VERSION "HNNBNNNYNNNNNNNNNNNNNNNNNNNNNNNNNNNNNNNNNN/4/%%%/4/'%**4NNN///"

NS_ :

BS_:

BU_: BAP_Tester BCM1 Gateway Gateway_PAG Klima_MSB Lift_VA VAS_L VAS_R

BO_ 976 TSG_FT_01: 8 Gateway
 SG_ FT_Tuer_geoeffnet : 0|1@1+ (1.0,0.0) [0.0|1] ""  BCM1,Klima_MSB,Lift_VA,VAS_L,VAS_R
 SG_ FT_verriegelt : 1|1@1+ (1.0,0.0) [0.0|1] ""  VAS_L,VAS_R
 SG_ FT_gesafet : 2|1@1+ (1.0,0.0) [0.0|1] ""  Vector__XXX
 SG_ FT_Schluesselschalter_auf : 3|1@1+ (1.0,0.0) [0.0|1] ""  Vector__XXX
 SG_ FT_Schluesselschalter_zu : 4|1@1+ (1.0,0.0) [0.0|1] ""  Vector__XXX
 SG_ FT_Unlock_Taster : 5|1@1+ (1.0,0.0) [0.0|1] ""  Vector__XXX
 SG_ FT_Lock_Taster : 6|1@1+ (1.0,0.0) [0.0|1] ""  Vector__XXX
 SG_ FT_Sperrklinke : 7|1@1+ (1.0,0.0) [0.0|1] ""  Vector__XXX
 SG_ FT_TAG_betaetigt : 8|1@1+ (1.0,0.0) [0.0|1] ""  VAS_L,VAS_R
 SG_ FT_TIG_betaetigt : 9|1@1+ (1.0,0.0) [0.0|1] ""  BCM1,VAS_L,VAS_R
 SG_ FT_IRUE_Taste : 10|1@1+ (1.0,0.0) [0.0|1] ""  Vector__XXX
 SG_ FT_HD_Taste : 11|1@1+ (1.0,0.0) [0.0|1] ""  Vector__XXX
 SG_ FT_TD_Taste_Fehler : 12|1@1+ (1.0,0.0) [0.0|1] ""  Vector__XXX
 SG_ FT_TD_Taste : 13|1@1+ (1.0,0.0) [0.0|1] ""  Vector__XXX
 SG_ SSR_Temp_Freigabe : 14|1@1+ (1.0,0.0) [0.0|1] ""  Vector__XXX
 SG_ FT_Sp_Heizung_Anf : 15|1@1+ (100,0) [0|100] "Unit_PerCent"  Vector__XXX
 SG_ FT_HD_Taste_2 : 16|1@1+ (1.0,0.0) [0.0|1] ""  Vector__XXX
 SG_ FT_TSG_hinten_verbaut : 18|1@1+ (1.0,0.0) [0.0|1] ""  Vector__XXX
 SG_ FT_Sp_Blk_def : 19|1@1+ (1.0,0.0) [0.0|1] ""  BCM1
 SG_ FT_FH_S_ManHoch : 20|1@1+ (1.0,0.0) [0.0|1] ""  Vector__XXX
 SG_ FT_FH_S_AutoHoch : 21|1@1+ (1.0,0.0) [0.0|1] ""  Vector__XXX
 SG_ FT_FH_S_ManTief : 22|1@1+ (1.0,0.0) [0.0|1] ""  Vector__XXX
 SG_ FT_FH_S_AutoTief : 23|1@1+ (1.0,0.0) [0.0|1] ""  Vector__XXX
 SG_ FT_FH_Oeffnung : 24|8@1+ (0.5,0) [0.0|100.0] "Unit_PerCent"  BCM1,Klima_MSB
 SG_ FT_FH_Bew_hoch : 32|1@1+ (1.0,0.0) [0.0|1] ""  Vector__XXX
 SG_ FT_FH_Bew_tief : 33|1@1+ (1.0,0.0) [0.0|1] ""  Vector__XXX
 SG_ FT_FH_Fang : 34|1@1+ (1.0,0.0) [0.0|1] ""  Vector__XXX
 SG_ FT_FH_Block : 35|1@1+ (1.0,0.0) [0.0|1] ""  Vector__XXX
 SG_ FT_FH_Thermo : 36|1@1+ (1.0,0.0) [0.0|1] ""  Vector__XXX
 SG_ FT_UEKB_aktiviert : 37|1@1+ (1.0,0.0) [0.0|1] ""  Vector__XXX
 SG_ ASW_HMI_defekt : 38|1@1+ (1.0,0.0) [0.0|1] ""  Vector__XXX
 SG_ FT_FH_normiert : 39|1@1+ (1.0,0.0) [0.0|1] ""  Vector__XXX
 SG_ FT_Schliesstaster : 40|1@1+ (1.0,0.0) [0.0|1] ""  Vector__XXX
 SG_ FT_Zuziehhilfe_aktiv : 41|1@1+ (1.0,0.0) [0.0|1] ""  Vector__XXX
 SG_ FT_SP_ausgerastet : 42|1@1+ (1.0,0.0) [0.0|1] ""  Vector__XXX
 SG_ FT_SP_lr_aktiv : 43|1@1+ (1.0,0.0) [0.0|1] ""  Vector__XXX
 SG_ FT_SP_ht_aktiv : 44|1@1+ (1.0,0.0) [0.0|1] ""  Vector__XXX
 SG_ ASW_wakeup : 45|1@1+ (1.0,0.0) [0.0|1] ""  Vector__XXX
 SG_ FT_Oben_Block_erw : 46|1@1+ (1.0,0.0) [0.0|1] ""  Vector__XXX
 SG_ FT_Unten_Block_erw : 47|1@1+ (1.0,0.0) [0.0|1] ""  Vector__XXX
 SG_ FT_Kisi_li_aktiv : 48|1@1+ (1.0,0.0) [0.0|1] ""  BCM1,Klima_MSB
 SG_ FT_Kisi_re_aktiv : 49|1@1+ (1.0,0.0) [0.0|1] ""  BCM1,Klima_MSB
 SG_ FT_Kisi_Taster_li : 50|1@1+ (1.0,0.0) [0.0|1] ""  Vector__XXX
 SG_ FT_Kisi_Taster_re : 51|1@1+ (1.0,0.0) [0.0|1] ""  Vector__XXX
 SG_ FT_BFS_Fond_Freigabe : 52|1@1+ (1.0,0.0) [0.0|1] ""  Vector__XXX
 SG_ FT_Kisi_Fehler : 53|1@1+ (1.0,0.0) [0.0|1] ""  BCM1
 SG_ FT_Daemmglas : 54|1@1+ (1.0,0.0) [0.0|1] ""  Vector__XXX
 SG_ FT_SP_Heizung_Status : 55|1@1+ (1.0,0.0) [0.0|1] ""  BCM1
 SG_ ASW_Warnung_aktiv_FS : 56|1@1+ (1.0,0.0) [0.0|1] ""  BCM1
 SG_ FT_FH_Pos_oben : 57|1@1+ (1.0,0.0) [0.0|1] ""  Vector__XXX
 SG_ FT_Tuerschloss_defekt : 58|1@1+ (1.0,0.0) [0.0|1] ""  Vector__XXX
 SG_ FT_SWA_Taster : 59|1@1+ (1.0,0.0) [0.0|1] ""  Vector__XXX
 SG_ SWA_HMI_Diagnose : 60|2@1+ (1.0,0.0) [0.0|3] ""  Vector__XXX
 SG_ FS_Status_eTAG : 62|2@1+ (1.0,0.0) [0.0|3] ""  Vector__XXX

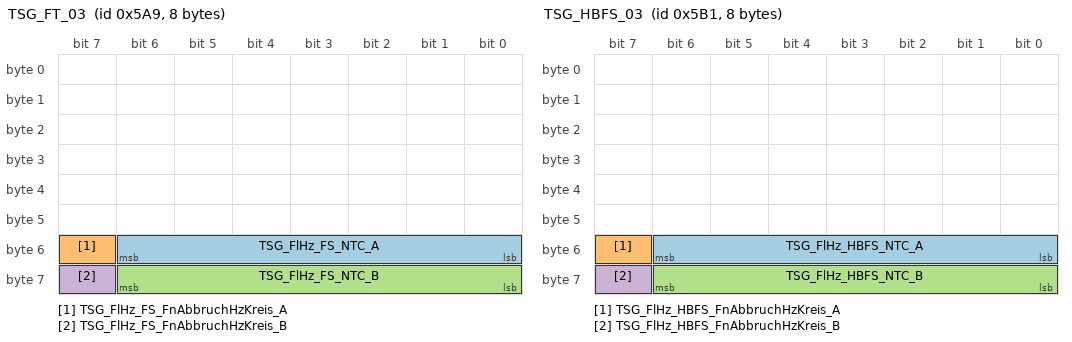
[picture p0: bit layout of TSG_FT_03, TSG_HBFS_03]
BO_ 1449 TSG_FT_03: 8 Gateway
 SG_ TSG_FlHz_FS_NTC_A : 48|7@1+ (1,-40) [-40|80] "Unit_DegreCelsi"  BCM1,Klima_MSB
 SG_ TSG_FlHz_FS_FnAbbruchHzKreis_A : 55|1@1+ (1.0,0.0) [0.0|1] ""  BCM1,Klima_MSB
 SG_ TSG_FlHz_FS_NTC_B : 56|7@1+ (1,-40) [-40|80] "Unit_DegreCelsi"  BCM1
 SG_ TSG_FlHz_FS_FnAbbruchHzKreis_B : 63|1@1+ (1.0,0.0) [0.0|1] ""  BCM1

BO_ 975 TSG_HBFS_01: 8 Gateway
 SG_ HBFS_Tuer_geoeffnet : 0|1@1+ (1.0,0.0) [0.0|1] ""  BCM1,Klima_MSB,VAS_L,VAS_R
 SG_ HBFS_verriegelt : 1|1@1+ (1.0,0.0) [0.0|1] ""  VAS_L,VAS_R
 SG_ HBFS_gesafet : 2|1@1+ (1.0,0.0) [0.0|1] ""  Vector__XXX
 SG_ HBFS_Heckrollotaster_betaetigt : 3|1@1+ (1.0,0.0) [0.0|1] ""  Vector__XXX
 SG_ HBFS_Tuerschloss_defekt : 4|1@1+ (1.0,0.0) [0.0|1] ""  Vector__XXX
 SG_ HBFS_Unlock_Taster : 5|1@1+ (1.0,0.0) [0.0|1] ""  Vector__XXX
 SG_ HBFS_Lock_Taster : 6|1@1+ (1.0,0.0) [0.0|1] ""  Vector__XXX
 SG_ HBFS_Sperrklinke : 7|1@1+ (1.0,0.0) [0.0|1] ""  Vector__XXX
 SG_ HBFS_TAG_betaetigt : 8|1@1+ (1.0,0.0) [0.0|1] ""  VAS_L,VAS_R
 SG_ HBFS_TIG_betaetigt : 9|1@1+ (1.0,0.0) [0.0|1] ""  BCM1,VAS_L,VAS_R
 SG_ HBFS_FH_S_HFS_AutoHoch : 10|1@1+ (1.0,0.0) [0.0|1] ""  Vector__XXX
 SG_ HBFS_FH_S_HFS_AutoTief : 11|1@1+ (1.0,0.0) [0.0|1] ""  Vector__XXX
 SG_ HBFS_FH_S_HFS_ManHoch : 12|1@1+ (1.0,0.0) [0.0|1] ""  Vector__XXX
 SG_ HBFS_FH_S_HFS_ManTief : 13|1@1+ (1.0,0.0) [0.0|1] ""  Vector__XXX
 SG_ HBFS_Tuer_Status : 14|2@1+ (1.0,0.0) [0.0|3] ""  Vector__XXX
 SG_ HBFS_SAD_Schalter : 16|4@1+ (1.0,0.0) [0.0|15] ""  Vector__XXX
 SG_ HBFS_FH_S_ManHoch : 20|1@1+ (1.0,0.0) [0.0|1] ""  Vector__XXX
 SG_ HBFS_FH_S_AutoHoch : 21|1@1+ (1.0,0.0) [0.0|1] ""  Vector__XXX
 SG_ HBFS_FH_S_ManTief : 22|1@1+ (1.0,0.0) [0.0|1] ""  Vector__XXX
 SG_ HBFS_FH_S_AutoTief : 23|1@1+ (1.0,0.0) [0.0|1] ""  Vector__XXX
 SG_ HBFS_FH_Oeffnung : 24|8@1+ (0.5,0) [0.0|100.0] "Unit_PerCent"  BCM1,Klima_MSB
 SG_ HBFS_FH_Bew_hoch : 32|1@1+ (1.0,0.0) [0.0|1] ""  Vector__XXX
 SG_ HBFS_FH_Bew_tief : 33|1@1+ (1.0,0.0) [0.0|1] ""  Vector__XXX
 SG_ HBFS_FH_Fang : 34|1@1+ (1.0,0.0) [0.0|1] ""  Vector__XXX
 SG_ HBFS_FH_Block : 35|1@1+ (1.0,0.0) [0.0|1] ""  Vector__XXX
 SG_ HBFS_FH_Thermo : 36|1@1+ (1.0,0.0) [0.0|1] ""  Vector__XXX
 SG_ HBFS_UEKB_aktiviert : 37|1@1+ (1.0,0.0) [0.0|1] ""  Vector__XXX
 SG_ HBFS_Tueroeffnen_Warnung : 38|1@1+ (1.0,0.0) [0.0|1] ""  Vector__XXX
 SG_ HBFS_FH_normiert : 39|1@1+ (1.0,0.0) [0.0|1] ""  Vector__XXX
 SG_ ASW_Warnung_aktiv_HBFS : 40|1@1+ (1.0,0.0) [0.0|1] ""  BCM1
 SG_ HBFS_Zuziehhilfe_aktiv : 41|1@1+ (1.0,0.0) [0.0|1] ""  Vector__XXX
 SG_ HBFS_Seitenrollo_hoch : 42|1@1+ (1.0,0.0) [0.0|1] ""  BCM1,Klima_MSB
 SG_ HBFS_Seitenrollo_tief : 43|1@1+ (1.0,0.0) [0.0|1] ""  BCM1,Klima_MSB
 SG_ HBFS_Status_KiSi : 44|1@1+ (1.0,0.0) [0.0|1] ""  Vector__XXX
 SG_ SSR_HBFS_Pos_Unten : 45|1@1+ (1.0,0.0) [0.0|1] ""  Vector__XXX
 SG_ HBFS_Oben_Block_erw : 46|1@1+ (1.0,0.0) [0.0|1] ""  Vector__XXX
 SG_ HBFS_Unten_Block_erw : 47|1@1+ (1.0,0.0) [0.0|1] ""  Vector__XXX
 SG_ MTHBFS_M_Taste : 48|1@1+ (1.0,0.0) [0.0|1] ""  Vector__XXX
 SG_ MTHBFS_Pos1 : 49|1@1+ (1.0,0.0) [0.0|1] ""  Vector__XXX
 SG_ MTHBFS_Pos2 : 50|1@1+ (1.0,0.0) [0.0|1] ""  Vector__XXX
 SG_ MTHBFS_Pos3 : 51|1@1+ (1.0,0.0) [0.0|1] ""  Vector__XXX
 SG_ HBFS_MRollo_Schalter : 52|3@1+ (1.0,0.0) [0.0|7] ""  Vector__XXX
 SG_ HBFS_Lock_Taster_inv : 55|1@1+ (1.0,0.0) [0.0|1] ""  Vector__XXX
 SG_ HBFS_Status_KiSi_inv : 56|1@1+ (1.0,0.0) [0.0|1] ""  Vector__XXX
 SG_ HBFS_Status_eTAG : 57|2@1+ (1.0,0.0) [0.0|3] ""  Vector__XXX
 SG_ HBFS_Tuer_Status_QBit : 59|1@1+ (1.0,0.0) [0.0|1] ""  Vector__XXX
 SG_ HBFS_TIG_betaetigt_schliessen : 60|1@1+ (1.0,0.0) [0.0|1] ""  Vector__XXX

BO_ 1457 TSG_HBFS_03: 8 Gateway
 SG_ TSG_FlHz_HBFS_NTC_A : 48|7@1+ (1,-40) [-40|80] "Unit_DegreCelsi"  BCM1,Klima_MSB
 SG_ TSG_FlHz_HBFS_FnAbbruchHzKreis_A : 55|1@1+ (1.0,0.0) [0.0|1] ""  BCM1,Klima_MSB
 SG_ TSG_FlHz_HBFS_NTC_B : 56|7@1+ (1,-40) [-40|80] "Unit_DegreCelsi"  BCM1
 SG_ TSG_FlHz_HBFS_FnAbbruchHzKreis_B : 63|1@1+ (1.0,0.0) [0.0|1] ""  BCM1

BO_ 974 TSG_HFS_01: 8 Gateway
 SG_ HFS_Tuer_geoeffnet : 0|1@1+ (1.0,0.0) [0.0|1] ""  BCM1,Klima_MSB,VAS_L,VAS_R
 SG_ HFS_verriegelt : 1|1@1+ (1.0,0.0) [0.0|1] ""  VAS_L,VAS_R
 SG_ HFS_gesafet : 2|1@1+ (1.0,0.0) [0.0|1] ""  Vector__XXX
 SG_ HFS_Heckrollotaster_betaetigt : 3|1@1+ (1.0,0.0) [0.0|1] ""  Vector__XXX
 SG_ HFS_Tuerschloss_defekt : 4|1@1+ (1.0,0.0) [0.0|1] ""  Vector__XXX
 SG_ HFS_Unlock_Taster : 5|1@1+ (1.0,0.0) [0.0|1] ""  Vector__XXX
 SG_ HFS_Lock_Taster : 6|1@1+ (1.0,0.0) [0.0|1] ""  Vector__XXX
 SG_ HFS_Sperrklinke : 7|1@1+ (1.0,0.0) [0.0|1] ""  Vector__XXX
 SG_ HFS_TAG_betaetigt : 8|1@1+ (1.0,0.0) [0.0|1] ""  VAS_L,VAS_R
 SG_ HFS_TIG_betaetigt : 9|1@1+ (1.0,0.0) [0.0|1] ""  BCM1,VAS_L,VAS_R
 SG_ HFS_FH_S_HBFS_AutoHoch : 10|1@1+ (1.0,0.0) [0.0|1] ""  Vector__XXX
 SG_ HFS_FH_S_HBFS_AutoTief : 11|1@1+ (1.0,0.0) [0.0|1] ""  Vector__XXX
 SG_ HFS_FH_S_HBFS_ManHoch : 12|1@1+ (1.0,0.0) [0.0|1] ""  Vector__XXX
 SG_ HFS_FH_S_HBFS_ManTief : 13|1@1+ (1.0,0.0) [0.0|1] ""  Vector__XXX
 SG_ HFS_Tuer_Status : 14|2@1+ (1.0,0.0) [0.0|3] ""  Vector__XXX
 SG_ HFS_SAD_Schalter : 16|4@1+ (1.0,0.0) [0.0|15] ""  Vector__XXX
 SG_ HFS_FH_S_ManHoch : 20|1@1+ (1.0,0.0) [0.0|1] ""  Vector__XXX
 SG_ HFS_FH_S_AutoHoch : 21|1@1+ (1.0,0.0) [0.0|1] ""  Vector__XXX
 SG_ HFS_FH_S_ManTief : 22|1@1+ (1.0,0.0) [0.0|1] ""  Vector__XXX
 SG_ HFS_FH_S_AutoTief : 23|1@1+ (1.0,0.0) [0.0|1] ""  Vector__XXX
 SG_ HFS_FH_Oeffnung : 24|8@1+ (0.5,0) [0.0|100.0] "Unit_PerCent"  BCM1,Klima_MSB
 SG_ HFS_FH_Bew_hoch : 32|1@1+ (1.0,0.0) [0.0|1] ""  Vector__XXX
 SG_ HFS_FH_Bew_tief : 33|1@1+ (1.0,0.0) [0.0|1] ""  Vector__XXX
 SG_ HFS_FH_Fang : 34|1@1+ (1.0,0.0) [0.0|1] ""  Vector__XXX
 SG_ HFS_FH_Block : 35|1@1+ (1.0,0.0) [0.0|1] ""  Vector__XXX
 SG_ HFS_FH_Thermo : 36|1@1+ (1.0,0.0) [0.0|1] ""  Vector__XXX
 SG_ HFS_UEKB_aktiviert : 37|1@1+ (1.0,0.0) [0.0|1] ""  Vector__XXX
 SG_ HFS_Tueroeffnen_Warnung : 38|1@1+ (1.0,0.0) [0.0|1] ""  Vector__XXX
 SG_ HFS_FH_normiert : 39|1@1+ (1.0,0.0) [0.0|1] ""  Vector__XXX
 SG_ ASW_Warnung_aktiv_HFS : 40|1@1+ (1.0,0.0) [0.0|1] ""  BCM1
 SG_ HFS_Zuziehhilfe_aktiv : 41|1@1+ (1.0,0.0) [0.0|1] ""  Vector__XXX
 SG_ HFS_Seitenrollo_hoch : 42|1@1+ (1.0,0.0) [0.0|1] ""  BCM1,Klima_MSB
 SG_ HFS_Seitenrollo_tief : 43|1@1+ (1.0,0.0) [0.0|1] ""  BCM1,Klima_MSB
 SG_ HFS_Status_KiSi : 44|1@1+ (1.0,0.0) [0.0|1] ""  Vector__XXX
 SG_ SSR_HFS_Pos_Unten : 45|1@1+ (1.0,0.0) [0.0|1] ""  Vector__XXX
 SG_ HFS_Oben_Block_erw : 46|1@1+ (1.0,0.0) [0.0|1] ""  Vector__XXX
 SG_ HFS_Unten_Block_erw : 47|1@1+ (1.0,0.0) [0.0|1] ""  Vector__XXX
 SG_ MTHFS_M_Taste : 48|1@1+ (1.0,0.0) [0.0|1] ""  Vector__XXX
 SG_ MTHFS_Pos1 : 49|1@1+ (1.0,0.0) [0.0|1] ""  Vector__XXX
 SG_ MTHFS_Pos2 : 50|1@1+ (1.0,0.0) [0.0|1] ""  Vector__XXX
 SG_ MTHFS_Pos3 : 51|1@1+ (1.0,0.0) [0.0|1] ""  Vector__XXX
 SG_ HFS_MRollo_Schalter : 52|3@1+ (1.0,0.0) [0.0|7] ""  Vector__XXX
 SG_ HFS_Lock_Taster_inv : 55|1@1+ (1.0,0.0) [0.0|1] ""  Vector__XXX
 SG_ HFS_Status_eTAG : 56|2@1+ (1.0,0.0) [0.0|3] ""  Vector__XXX
 SG_ HFS_Tuer_Status_QBit : 58|1@1+ (1.0,0.0) [0.0|1] ""  Vector__XXX
 SG_ HFS_TCR_Mode_aktiv : 59|1@1+ (1.0,0.0) [0.0|1] ""  Vector__XXX

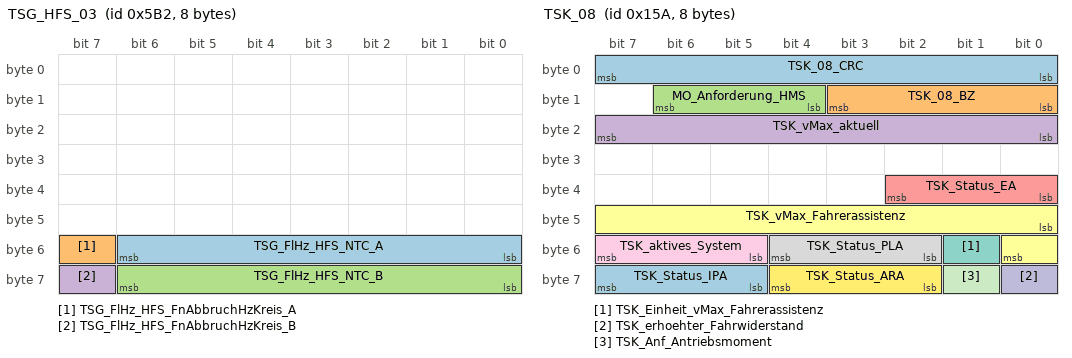
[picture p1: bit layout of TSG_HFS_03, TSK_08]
BO_ 1458 TSG_HFS_03: 8 Gateway
 SG_ TSG_FlHz_HFS_NTC_A : 48|7@1+ (1,-40) [-40|80] "Unit_DegreCelsi"  BCM1,Klima_MSB
 SG_ TSG_FlHz_HFS_FnAbbruchHzKreis_A : 55|1@1+ (1.0,0.0) [0.0|1] ""  BCM1,Klima_MSB
 SG_ TSG_FlHz_HFS_NTC_B : 56|7@1+ (1,-40) [-40|80] "Unit_DegreCelsi"  BCM1
 SG_ TSG_FlHz_HFS_FnAbbruchHzKreis_B : 63|1@1+ (1.0,0.0) [0.0|1] ""  BCM1

BO_ 346 TSK_08: 8 Gateway
 SG_ TSK_08_CRC : 0|8@1+ (1,0) [0|255] ""  Vector__XXX
 SG_ TSK_08_BZ : 8|4@1+ (1,0) [0|15] ""  Vector__XXX
 SG_ MO_Anforderung_HMS : 12|3@1+ (1.0,0.0) [0.0|7] ""  Vector__XXX
 SG_ TSK_vMax_aktuell : 16|8@1+ (1,0) [0|253] "Unit_KiloMeterPerHour"  Vector__XXX
 SG_ TSK_Status_EA : 32|3@1+ (1.0,0.0) [0.0|7] ""  Vector__XXX
 SG_ TSK_vMax_Fahrerassistenz : 40|9@1+ (1,0) [0|510] ""  Vector__XXX
 SG_ TSK_Einheit_vMax_Fahrerassistenz : 49|1@1+ (1.0,0.0) [0.0|1] ""  Vector__XXX
 SG_ TSK_Status_PLA : 50|3@1+ (1.0,0.0) [0.0|7] ""  BCM1
 SG_ TSK_aktives_System : 53|3@1+ (1.0,0.0) [0.0|7] ""  BCM1
 SG_ TSK_erhoehter_Fahrwiderstand : 56|1@1+ (1.0,0.0) [0.0|1] ""  Vector__XXX
 SG_ TSK_Anf_Antriebsmoment : 57|1@1+ (1.0,0.0) [0.0|1] ""  Vector__XXX
 SG_ TSK_Status_ARA : 58|3@1+ (1.0,0.0) [0.0|7] ""  BCM1
 SG_ TSK_Status_IPA : 61|3@1+ (1.0,0.0) [0.0|7] ""  Vector__XXX

BO_ 2589283609 UGDO_02: 8 BCM1
 SG_ UGDO_LED_Code_01 : 0|5@1+ (1.0,0.0) [0.0|31] ""  Gateway,Gateway_PAG
 SG_ UGDO_Function_01 : 5|3@1+ (1.0,0.0) [0.0|7] ""  Gateway,Gateway_PAG
 SG_ UGDO_Failure_Antenne : 8|1@1+ (1.0,0.0) [0.0|1] ""  Gateway,Gateway_PAG
 SG_ UGDO_Failure_Codierung : 9|1@1+ (1.0,0.0) [0.0|1] ""  Gateway,Gateway_PAG
 SG_ UGDO_Failure_Hardware : 10|1@1+ (1.0,0.0) [0.0|1] ""  Gateway,Gateway_PAG
 SG_ UGDO_ResponseError : 16|1@1+ (1.0,0.0) [0.0|1] ""  Gateway,Gateway_PAG
 SG_ UGDO_Channel_1 : 24|1@1+ (1.0,0.0) [0.0|1] ""  Gateway,Gateway_PAG
 SG_ UGDO_Channel_2 : 25|1@1+ (1.0,0.0) [0.0|1] ""  Gateway,Gateway_PAG
 SG_ UGDO_Channel_3 : 26|1@1+ (1.0,0.0) [0.0|1] ""  Gateway,Gateway_PAG
 SG_ UGDO_Channel_4 : 27|1@1+ (1.0,0.0) [0.0|1] ""  Gateway,Gateway_PAG
 SG_ UGDO_Channel_5 : 28|1@1+ (1.0,0.0) [0.0|1] ""  Gateway,Gateway_PAG
 SG_ UGDO_Channel_6 : 29|1@1+ (1.0,0.0) [0.0|1] ""  Gateway,Gateway_PAG
 SG_ UGDO_Channel_7 : 30|1@1+ (1.0,0.0) [0.0|1] ""  Gateway,Gateway_PAG
 SG_ UGDO_Channel_8 : 31|1@1+ (1.0,0.0) [0.0|1] ""  Gateway,Gateway_PAG
 SG_ UGDO_Channel_9 : 32|1@1+ (1.0,0.0) [0.0|1] ""  Gateway,Gateway_PAG
 SG_ UGDO_Channel_10 : 33|1@1+ (1.0,0.0) [0.0|1] ""  Gateway,Gateway_PAG
 SG_ UGDO_Channel_11 : 34|1@1+ (1.0,0.0) [0.0|1] ""  Gateway,Gateway_PAG
 SG_ UGDO_Channel_12 : 35|1@1+ (1.0,0.0) [0.0|1] ""  Gateway,Gateway_PAG
 SG_ UGDO_Channel_13 : 36|1@1+ (1.0,0.0) [0.0|1] ""  Gateway,Gateway_PAG
 SG_ UGDO_Channel_14 : 37|1@1+ (1.0,0.0) [0.0|1] ""  Gateway,Gateway_PAG
 SG_ UGDO_Channel_15 : 38|1@1+ (1.0,0.0) [0.0|1] ""  Gateway,Gateway_PAG
 SG_ UGDO_DoorState : 40|4@1+ (1.0,0.0) [0.0|15] ""  Gateway,Gateway_PAG

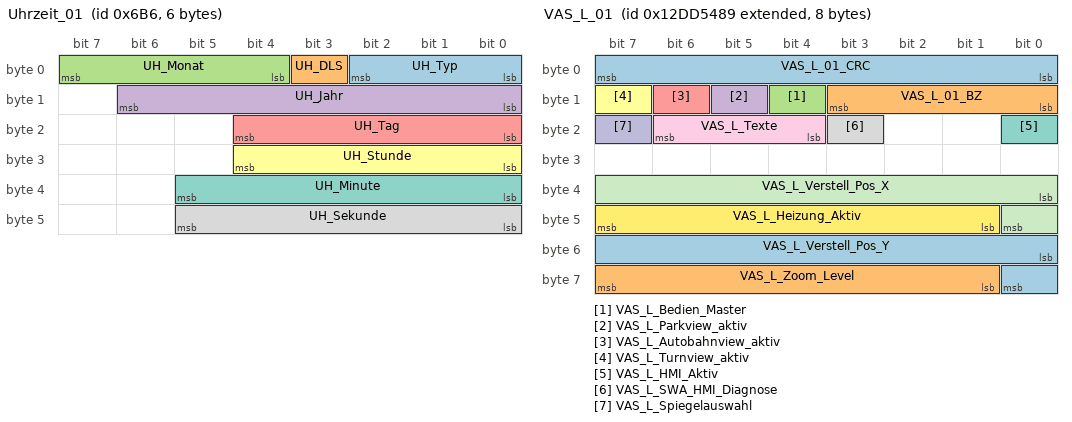
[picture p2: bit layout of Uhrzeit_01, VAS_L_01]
BO_ 1718 Uhrzeit_01: 6 Gateway
 SG_ UH_Typ : 0|3@1+ (1.0,0.0) [0.0|7] ""  Vector__XXX
 SG_ UH_DLS : 3|1@1+ (1.0,0.0) [0.0|1] ""  Vector__XXX
 SG_ UH_Monat : 4|4@1+ (1,0) [1|12] "Unit_Month"  Vector__XXX
 SG_ UH_Jahr : 8|7@1+ (1,2000) [2000|2127] "Unit_Year"  Vector__XXX
 SG_ UH_Tag : 16|5@1+ (1,0) [1|31] "Unit_Day"  Vector__XXX
 SG_ UH_Stunde : 24|5@1+ (1,0) [0|23] "Unit_Hours"  Vector__XXX
 SG_ UH_Minute : 32|6@1+ (1,0) [0|59] "Unit_Minut"  Vector__XXX
 SG_ UH_Sekunde : 40|6@1+ (1,0) [0|59] "Unit_Secon"  Vector__XXX

BO_ 2463978633 VAS_L_01: 8 VAS_L
 SG_ VAS_L_01_CRC : 0|8@1+ (1,0) [0|255] ""  Gateway,Gateway_PAG,VAS_R
 SG_ VAS_L_01_BZ : 8|4@1+ (1,0) [0|15] ""  Gateway,Gateway_PAG,VAS_R
 SG_ VAS_L_Bedien_Master : 12|1@1+ (1.0,0.0) [0.0|1] ""  Gateway,Gateway_PAG,VAS_R
 SG_ VAS_L_Parkview_aktiv : 13|1@1+ (1.0,0.0) [0.0|1] ""  Gateway,Gateway_PAG,VAS_R
 SG_ VAS_L_Autobahnview_aktiv : 14|1@1+ (1.0,0.0) [0.0|1] ""  Gateway,Gateway_PAG,VAS_R
 SG_ VAS_L_Turnview_aktiv : 15|1@1+ (1.0,0.0) [0.0|1] ""  Gateway,Gateway_PAG,VAS_R
 SG_ VAS_L_HMI_Aktiv : 16|1@1+ (1.0,0.0) [0.0|1] ""  Gateway,Gateway_PAG,VAS_R
 SG_ VAS_L_SWA_HMI_Diagnose : 19|1@1+ (1.0,0.0) [0.0|1] ""  Gateway,Gateway_PAG,VAS_R
 SG_ VAS_L_Texte : 20|3@1+ (1.0,0.0) [0.0|7] ""  Gateway,Gateway_PAG,VAS_R
 SG_ VAS_L_Spiegelauswahl : 23|1@1+ (1.0,0.0) [0.0|1] ""  Gateway,Gateway_PAG,VAS_R
 SG_ VAS_L_Verstell_Pos_X : 32|9@1+ (1,0) [0|400] "Unit_None"  Gateway,Gateway_PAG,VAS_R
 SG_ VAS_L_Heizung_Aktiv : 41|7@1+ (1,0) [0|100] "Unit_PerCent"  Gateway,Gateway_PAG,VAS_R
 SG_ VAS_L_Verstell_Pos_Y : 48|9@1+ (1,0) [0|400] "Unit_None"  Gateway,Gateway_PAG,VAS_R
 SG_ VAS_L_Zoom_Level : 57|7@1+ (1,0) [0|100] "Unit_PerCent"  Gateway,Gateway_PAG,VAS_R

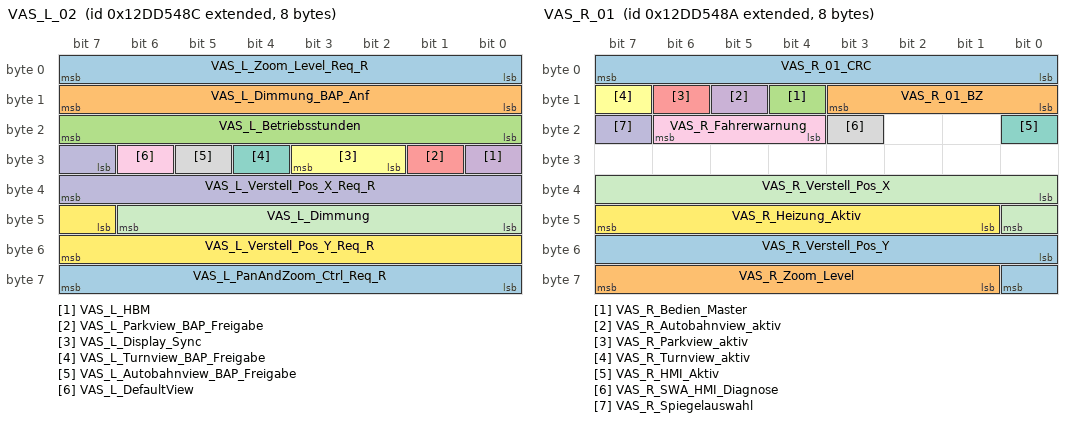
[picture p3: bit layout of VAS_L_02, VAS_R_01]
BO_ 2463978636 VAS_L_02: 8 VAS_L
 SG_ VAS_L_Zoom_Level_Req_R : 0|8@1+ (1,-100) [-100|100] "Unit_PerCent"  VAS_R
 SG_ VAS_L_Dimmung_BAP_Anf : 8|8@1+ (1,-100) [-100|100] "Unit_PerCent"  VAS_R
 SG_ VAS_L_Betriebsstunden : 16|8@1+ (50,0) [0|12500] "Unit_Day"  VAS_R
 SG_ VAS_L_HBM : 24|1@1+ (1.0,0.0) [0.0|1] ""  VAS_R
 SG_ VAS_L_Parkview_BAP_Freigabe : 25|1@1+ (1.0,0.0) [0.0|1] ""  VAS_R
 SG_ VAS_L_Display_Sync : 26|2@1+ (1.0,0.0) [0.0|3] ""  VAS_R
 SG_ VAS_L_Turnview_BAP_Freigabe : 28|1@1+ (1.0,0.0) [0.0|1] ""  VAS_R
 SG_ VAS_L_Autobahnview_BAP_Freigabe : 29|1@1+ (1.0,0.0) [0.0|1] ""  VAS_R
 SG_ VAS_L_DefaultView : 30|1@1+ (1.0,0.0) [0.0|1] ""  VAS_R
 SG_ VAS_L_Verstell_Pos_X_Req_R : 31|9@1+ (1,-200) [-200|200] "Unit_None"  VAS_R
 SG_ VAS_L_Dimmung : 40|7@1+ (1,0) [0|100] "Unit_PerCent"  VAS_R
 SG_ VAS_L_Verstell_Pos_Y_Req_R : 47|9@1+ (1,-200) [-200|200] "Unit_None"  VAS_R
 SG_ VAS_L_PanAndZoom_Ctrl_Req_R : 56|8@1+ (1.0,0.0) [0.0|255] ""  VAS_R

BO_ 2463978634 VAS_R_01: 8 VAS_R
 SG_ VAS_R_01_CRC : 0|8@1+ (1,0) [0|255] ""  Gateway,Gateway_PAG,VAS_L
 SG_ VAS_R_01_BZ : 8|4@1+ (1,0) [0|15] ""  Gateway,Gateway_PAG,VAS_L
 SG_ VAS_R_Bedien_Master : 12|1@1+ (1.0,0.0) [0.0|1] ""  Gateway,Gateway_PAG,VAS_L
 SG_ VAS_R_Autobahnview_aktiv : 13|1@1+ (1.0,0.0) [0.0|1] ""  Gateway,Gateway_PAG,VAS_L
 SG_ VAS_R_Parkview_aktiv : 14|1@1+ (1.0,0.0) [0.0|1] ""  Gateway,Gateway_PAG,VAS_L
 SG_ VAS_R_Turnview_aktiv : 15|1@1+ (1.0,0.0) [0.0|1] ""  Gateway,Gateway_PAG,VAS_L
 SG_ VAS_R_HMI_Aktiv : 16|1@1+ (1.0,0.0) [0.0|1] ""  Gateway,Gateway_PAG,VAS_L
 SG_ VAS_R_SWA_HMI_Diagnose : 19|1@1+ (1.0,0.0) [0.0|1] ""  Gateway,Gateway_PAG,VAS_L
 SG_ VAS_R_Fahrerwarnung : 20|3@1+ (1.0,0.0) [0.0|7] ""  Gateway,Gateway_PAG,VAS_L
 SG_ VAS_R_Spiegelauswahl : 23|1@1+ (1.0,0.0) [0.0|1] ""  Gateway,Gateway_PAG,VAS_L
 SG_ VAS_R_Verstell_Pos_X : 32|9@1+ (1,0) [0|400] "Unit_None"  Gateway,Gateway_PAG,VAS_L
 SG_ VAS_R_Heizung_Aktiv : 41|7@1+ (1,0) [0|100] "Unit_PerCent"  Gateway,Gateway_PAG,VAS_L
 SG_ VAS_R_Verstell_Pos_Y : 48|9@1+ (1,0) [0|400] "Unit_None"  Gateway,Gateway_PAG,VAS_L
 SG_ VAS_R_Zoom_Level : 57|7@1+ (1,0) [0|100] "Unit_PerCent"  Gateway,Gateway_PAG,VAS_L

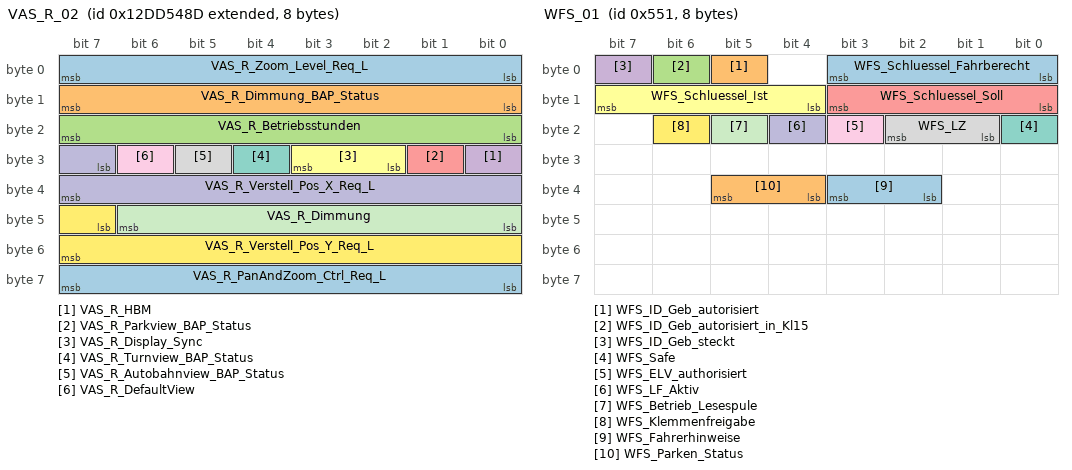
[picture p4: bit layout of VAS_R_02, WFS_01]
BO_ 2463978637 VAS_R_02: 8 VAS_R
 SG_ VAS_R_Zoom_Level_Req_L : 0|8@1+ (1,-100) [-100|100] "Unit_PerCent"  VAS_L
 SG_ VAS_R_Dimmung_BAP_Status : 8|8@1+ (1,-100) [-100|100] "Unit_PerCent"  VAS_L
 SG_ VAS_R_Betriebsstunden : 16|8@1+ (50,0) [0|12500] "Unit_Day"  VAS_L
 SG_ VAS_R_HBM : 24|1@1+ (1.0,0.0) [0.0|1] ""  VAS_L
 SG_ VAS_R_Parkview_BAP_Status : 25|1@1+ (1.0,0.0) [0.0|1] ""  VAS_L
 SG_ VAS_R_Display_Sync : 26|2@1+ (1.0,0.0) [0.0|3] ""  VAS_L
 SG_ VAS_R_Turnview_BAP_Status : 28|1@1+ (1.0,0.0) [0.0|1] ""  VAS_L
 SG_ VAS_R_Autobahnview_BAP_Status : 29|1@1+ (1.0,0.0) [0.0|1] ""  VAS_L
 SG_ VAS_R_DefaultView : 30|1@1+ (1.0,0.0) [0.0|1] ""  VAS_L
 SG_ VAS_R_Verstell_Pos_X_Req_L : 31|9@1+ (1,-200) [-200|200] "Unit_None"  VAS_L
 SG_ VAS_R_Dimmung : 40|7@1+ (1,0) [0|100] "Unit_PerCent"  VAS_L
 SG_ VAS_R_Verstell_Pos_Y_Req_L : 47|9@1+ (1,-200) [-200|200] "Unit_None"  VAS_L
 SG_ VAS_R_PanAndZoom_Ctrl_Req_L : 56|8@1+ (1.0,0.0) [0.0|255] ""  VAS_L

BO_ 995 Verdeck_01: 8 Gateway
 SG_ Verdeck_01_CRC : 0|8@1+ (1,0) [0|255] ""  Vector__XXX
 SG_ Verdeck_01_BZ : 8|4@1+ (1,0) [0|15] ""  Vector__XXX
 SG_ VS_VD_zu_ver : 16|1@1+ (1.0,0.0) [0.0|1] ""  BCM1,Klima_MSB
 SG_ VS_VD_entriegelt : 17|1@1+ (1.0,0.0) [0.0|1] ""  BCM1
 SG_ VS_VD_offen_ver : 18|1@1+ (1.0,0.0) [0.0|1] ""  BCM1,Klima_MSB
 SG_ VS_VD_Zwischenposition : 19|1@1+ (1.0,0.0) [0.0|1] ""  Klima_MSB
 SG_ VS_VD_Bew_auf : 20|1@1+ (1.0,0.0) [0.0|1] ""  BCM1,Klima_MSB
 SG_ VS_VD_Bew_zu : 21|1@1+ (1.0,0.0) [0.0|1] ""  BCM1,Klima_MSB
 SG_ VS_Verdeck_Anf : 22|1@1+ (1.0,0.0) [0.0|1] ""  BCM1
 SG_ VS_Hardtop : 23|1@1+ (1.0,0.0) [0.0|1] ""  BCM1,Klima_MSB
 SG_ VS_VD_Fehler : 24|1@1+ (1.0,0.0) [0.0|1] ""  Vector__XXX
 SG_ VS_Lampe_Blk : 25|1@1+ (1.0,0.0) [0.0|1] ""  Vector__XXX
 SG_ VS_Buzzer : 26|1@1+ (1.0,0.0) [0.0|1] ""  Vector__XXX
 SG_ VS_HD_sperren : 27|1@1+ (1.0,0.0) [0.0|1] ""  Vector__XXX
 SG_ VS_HHS_enable : 28|1@1+ (1.0,0.0) [0.0|1] ""  Vector__XXX
 SG_ VD_SpannungsAnf : 29|2@1+ (1.0,0.0) [0.0|3] ""  Vector__XXX
 SG_ VS_VDKD_auf : 31|1@1+ (1.0,0.0) [0.0|1] ""  BCM1
 SG_ VS_FS_AutoHoch : 32|1@1+ (1.0,0.0) [0.0|1] ""  Vector__XXX
 SG_ VS_FS_AutoTief : 33|1@1+ (1.0,0.0) [0.0|1] ""  Vector__XXX
 SG_ VS_FS_ManHoch : 34|1@1+ (1.0,0.0) [0.0|1] ""  Vector__XXX
 SG_ VS_FS_ManTief : 35|1@1+ (1.0,0.0) [0.0|1] ""  Vector__XXX
 SG_ VS_BFS_AutoHoch : 36|1@1+ (1.0,0.0) [0.0|1] ""  Vector__XXX
 SG_ VS_BFS_AutoTief : 37|1@1+ (1.0,0.0) [0.0|1] ""  Vector__XXX
 SG_ VS_BFS_ManHoch : 38|1@1+ (1.0,0.0) [0.0|1] ""  Vector__XXX
 SG_ VS_BFS_ManTief : 39|1@1+ (1.0,0.0) [0.0|1] ""  Vector__XXX
 SG_ VS_HFS_AutoHoch : 40|1@1+ (1.0,0.0) [0.0|1] ""  Vector__XXX
 SG_ VS_HFS_AutoTief : 41|1@1+ (1.0,0.0) [0.0|1] ""  Vector__XXX
 SG_ VS_HFS_ManHoch : 42|1@1+ (1.0,0.0) [0.0|1] ""  Vector__XXX
 SG_ VS_HFS_ManTief : 43|1@1+ (1.0,0.0) [0.0|1] ""  Vector__XXX
 SG_ VS_HBFS_AutoHoch : 44|1@1+ (1.0,0.0) [0.0|1] ""  Vector__XXX
 SG_ VS_HBFS_AutoTief : 45|1@1+ (1.0,0.0) [0.0|1] ""  Vector__XXX
 SG_ VS_HBFS_ManHoch : 46|1@1+ (1.0,0.0) [0.0|1] ""  Vector__XXX
 SG_ VS_HBFS_ManTief : 47|1@1+ (1.0,0.0) [0.0|1] ""  Vector__XXX
 SG_ VS_FH_FT_Langhub : 49|1@1+ (1.0,0.0) [0.0|1] ""  Vector__XXX
 SG_ VS_Windschott_nicht_abgelegt : 50|1@1+ (1.0,0.0) [0.0|1] ""  Vector__XXX
 SG_ VS_FH_BT_Langhub : 51|1@1+ (1.0,0.0) [0.0|1] ""  Vector__XXX
 SG_ VS_FH_HFS_Langhub : 53|1@1+ (1.0,0.0) [0.0|1] ""  Vector__XXX
 SG_ VS_Heckschloss_auf : 54|1@1+ (1.0,0.0) [0.0|1] ""  Vector__XXX
 SG_ VS_FH_HBFS_Langhub : 55|1@1+ (1.0,0.0) [0.0|1] ""  Vector__XXX
 SG_ VSG_Meldungen : 56|6@1+ (1,0) [1|63] "Unit_None"  BCM1,Klima_MSB
 SG_ VS_StartStopp_Info : 62|2@1+ (1.0,0.0) [0.0|3] ""  Vector__XXX

BO_ 1716 VIN_01: 8 Gateway
 SG_ VIN_01_MUX M  : 0|2@1+ (1,0) [0|3] ""  BCM1,Klima_MSB
 SG_ KS_Geheimnis_1 m0  : 8|8@1+ (1,0) [0|255] ""  Vector__XXX
 SG_ VIN_4 m1  : 8|8@1+ (1,0) [0|255] ""  BCM1,Klima_MSB
 SG_ VIN_11 m2  : 8|8@1+ (1,0) [0|255] ""  BCM1,Klima_MSB
 SG_ KS_Geheimnis_2 m0  : 16|8@1+ (1,0) [0|255] ""  Vector__XXX
 SG_ VIN_5 m1  : 16|8@1+ (1,0) [0|255] ""  BCM1,Klima_MSB
 SG_ VIN_12 m2  : 16|8@1+ (1,0) [0|255] ""  BCM1,Klima_MSB
 SG_ KS_Geheimnis_3 m0  : 24|8@1+ (1,0) [0|255] ""  Vector__XXX
 SG_ VIN_6 m1  : 24|8@1+ (1,0) [0|255] ""  BCM1,Klima_MSB
 SG_ VIN_13 m2  : 24|8@1+ (1,0) [0|255] ""  BCM1,Klima_MSB
 SG_ KS_Geheimnis_4 m0  : 32|8@1+ (1,0) [0|255] ""  Vector__XXX
 SG_ VIN_7 m1  : 32|8@1+ (1,0) [0|255] ""  BCM1,Klima_MSB
 SG_ VIN_14 m2  : 32|8@1+ (1,0) [0|255] ""  BCM1,Klima_MSB
 SG_ VIN_1 m0  : 40|8@1+ (1,0) [0|255] ""  BCM1,Klima_MSB
 SG_ VIN_8 m1  : 40|8@1+ (1,0) [0|255] ""  BCM1,Klima_MSB
 SG_ VIN_15 m2  : 40|8@1+ (1,0) [0|255] ""  BCM1,Klima_MSB
 SG_ VIN_2 m0  : 48|8@1+ (1,0) [0|255] ""  BCM1,Klima_MSB
 SG_ VIN_9 m1  : 48|8@1+ (1,0) [0|255] ""  BCM1,Klima_MSB
 SG_ VIN_16 m2  : 48|8@1+ (1,0) [0|255] ""  BCM1,Klima_MSB
 SG_ VIN_3 m0  : 56|8@1+ (1,0) [0|255] ""  BCM1,Klima_MSB
 SG_ VIN_10 m1  : 56|8@1+ (1,0) [0|255] ""  BCM1,Klima_MSB
 SG_ VIN_17 m2  : 56|8@1+ (1,0) [0|255] ""  BCM1,Klima_MSB

BO_ 1361 WFS_01: 8 Gateway
 SG_ WFS_Schluessel_Fahrberecht : 0|4@1+ (1.0,0.0) [0.0|15] ""  Vector__XXX
 SG_ WFS_ID_Geb_autorisiert : 5|1@1+ (1.0,0.0) [0.0|1] ""  BCM1
 SG_ WFS_ID_Geb_autorisiert_in_Kl15 : 6|1@1+ (1.0,0.0) [0.0|1] ""  Vector__XXX
 SG_ WFS_ID_Geb_steckt : 7|1@1+ (1.0,0.0) [0.0|1] ""  Vector__XXX
 SG_ WFS_Schluessel_Soll : 8|4@1+ (1,0) [0|8] "Unit_None"  Vector__XXX
 SG_ WFS_Schluessel_Ist : 12|4@1+ (1,0) [0|8] "Unit_None"  Vector__XXX
 SG_ WFS_Safe : 16|1@1+ (1.0,0.0) [0.0|1] ""  Vector__XXX
 SG_ WFS_LZ : 17|2@1+ (1.0,0.0) [0.0|3] ""  Vector__XXX
 SG_ WFS_ELV_authorisiert : 19|1@1+ (1.0,0.0) [0.0|1] ""  Vector__XXX
 SG_ WFS_LF_Aktiv : 20|1@1+ (1.0,0.0) [0.0|1] ""  Vector__XXX
 SG_ WFS_Betrieb_Lesespule : 21|1@1+ (1.0,0.0) [0.0|1] ""  Vector__XXX
 SG_ WFS_Klemmenfreigabe : 22|1@1+ (1.0,0.0) [0.0|1] ""  Vector__XXX
 SG_ WFS_Fahrerhinweise : 34|2@1+ (1.0,0.0) [0.0|3] ""  Vector__XXX
 SG_ WFS_Parken_Status : 36|2@1+ (1.0,0.0) [0.0|3] ""  Vector__XXX

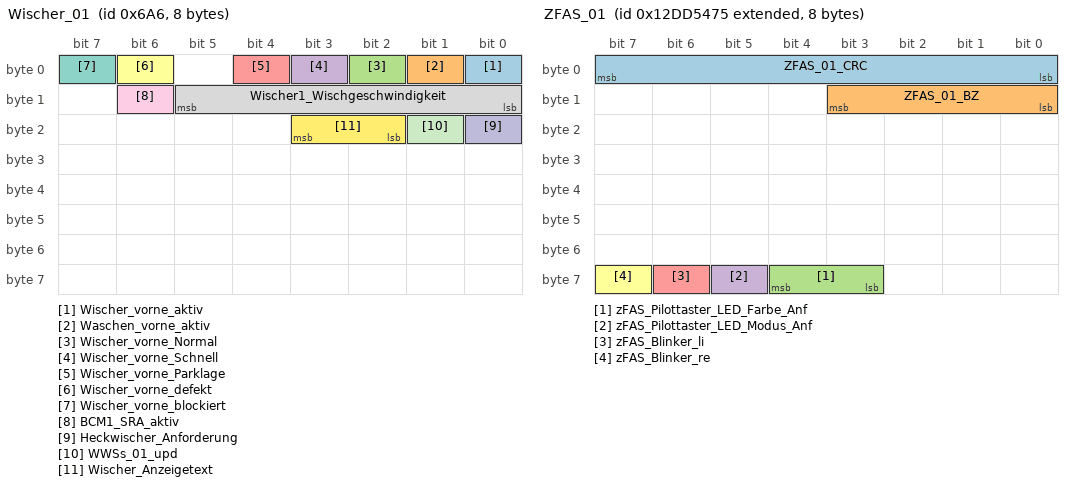
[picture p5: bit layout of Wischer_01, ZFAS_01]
BO_ 1702 Wischer_01: 8 BCM1
 SG_ Wischer_vorne_aktiv : 0|1@1+ (1.0,0.0) [0.0|1] ""  Gateway,Gateway_PAG,Klima_MSB,VAS_L,VAS_R
 SG_ Waschen_vorne_aktiv : 1|1@1+ (1.0,0.0) [0.0|1] ""  Gateway,Gateway_PAG,Klima_MSB
 SG_ Wischer_vorne_Normal : 2|1@1+ (1.0,0.0) [0.0|1] ""  Gateway,Gateway_PAG
 SG_ Wischer_vorne_Schnell : 3|1@1+ (1.0,0.0) [0.0|1] ""  Gateway,Gateway_PAG
 SG_ Wischer_vorne_Parklage : 4|1@1+ (1.0,0.0) [0.0|1] ""  Gateway,Gateway_PAG
 SG_ Wischer_vorne_defekt : 6|1@1+ (1.0,0.0) [0.0|1] ""  Gateway,Gateway_PAG
 SG_ Wischer_vorne_blockiert : 7|1@1+ (1.0,0.0) [0.0|1] ""  Gateway,Gateway_PAG
 SG_ Wischer1_Wischgeschwindigkeit : 8|6@1+ (1,9) [10|70] "Unit_MinutInver"  Gateway,Gateway_PAG
 SG_ BCM1_SRA_aktiv : 14|1@1+ (1.0,0.0) [0.0|1] ""  Gateway,Gateway_PAG
 SG_ Heckwischer_Anforderung : 16|1@1+ (1.0,0.0) [0.0|1] ""  Gateway,Gateway_PAG
 SG_ WWSs_01_upd : 17|1@1+ (1.0,0.0) [0.0|1] ""  Gateway,Gateway_PAG,Klima_MSB
 SG_ Wischer_Anzeigetext : 18|2@1+ (1.0,0.0) [0.0|3] ""  Gateway,Gateway_PAG

BO_ 2617013760 XCP_BCM1_CRO_01: 8 Vector__XXX
 SG_ XCP_BCM1_CRO_01_Data : 0|64@1+ (1,0) [0|1] ""  BCM1

BO_ 2617013761 XCP_BCM1_DTO_01: 8 BCM1
 SG_ XCP_BCM1_DTO_01_Data : 0|64@1+ (1,0) [0|1] ""  Vector__XXX

BO_ 2617124608 XCP_VAS_L_CRO_01: 8 Vector__XXX
 SG_ XCP_VAS_L_CRO_01_Data : 0|64@1+ (1,0) [0|1] ""  VAS_L

BO_ 2617124609 XCP_VAS_L_DTO_01: 8 VAS_L
 SG_ XCP_VAS_L_DTO_01_Data : 0|64@1+ (1,0) [0|1] ""  Vector__XXX

BO_ 2617126656 XCP_VAS_R_CRO_01: 8 Vector__XXX
 SG_ XCP_VAS_R_CRO_01_Data : 0|64@1+ (1,0) [0|1] ""  VAS_R

BO_ 2617126657 XCP_VAS_R_DTO_01: 8 VAS_R
 SG_ XCP_VAS_L_DTO_01_Data : 0|64@1+ (1,0) [0|1] ""  Vector__XXX

BO_ 2463978613 ZFAS_01: 8 Gateway
 SG_ ZFAS_01_CRC : 0|8@1+ (1,0) [0|255] ""  Vector__XXX
 SG_ ZFAS_01_BZ : 8|4@1+ (1,0) [0|15] ""  Vector__XXX
 SG_ zFAS_Pilottaster_LED_Farbe_Anf : 59|2@1+ (1.0,0.0) [0.0|3] ""  BCM1
 SG_ zFAS_Pilottaster_LED_Modus_Anf : 61|1@1+ (1.0,0.0) [0.0|1] ""  BCM1
 SG_ zFAS_Blinker_li : 62|1@1+ (1.0,0.0) [0.0|1] ""  Vector__XXX
 SG_ zFAS_Blinker_re : 63|1@1+ (1.0,0.0) [0.0|1] ""  Vector__XXX

BO_ 388 ZV_01: 8 Gateway
 SG_ ZV_01_CRC : 0|8@1+ (1,0) [0|255] ""  BCM1
 SG_ ZV_01_BZ : 8|4@1+ (1,0) [0|15] ""  BCM1
 SG_ ZV_FT_verriegeln : 12|1@1+ (1.0,0.0) [0.0|1] ""  BCM1
 SG_ ZV_FT_entriegeln : 13|1@1+ (1.0,0.0) [0.0|1] ""  BCM1
 SG_ ZV_BT_verriegeln : 14|1@1+ (1.0,0.0) [0.0|1] ""  Vector__XXX
 SG_ ZV_BT_entriegeln : 15|1@1+ (1.0,0.0) [0.0|1] ""  Vector__XXX
 SG_ ZV_HFS_verriegeln : 16|1@1+ (1.0,0.0) [0.0|1] ""  Vector__XXX
 SG_ ZV_HFS_entriegeln : 17|1@1+ (1.0,0.0) [0.0|1] ""  Vector__XXX
 SG_ ZV_HBFS_verriegeln : 18|1@1+ (1.0,0.0) [0.0|1] ""  Vector__XXX
 SG_ ZV_HBFS_entriegeln : 19|1@1+ (1.0,0.0) [0.0|1] ""  Vector__XXX
 SG_ ZV_zentral_safen : 20|1@1+ (1.0,0.0) [0.0|1] ""  Vector__XXX
 SG_ ZV_zentral_entsafen : 21|1@1+ (1.0,0.0) [0.0|1] ""  Vector__XXX
 SG_ ZV_Spg_Anklappen : 22|1@1+ (1.0,0.0) [0.0|1] ""  Vector__XXX
 SG_ ZV_Softtouch_betaetigt : 23|1@1+ (1.0,0.0) [0.0|1] ""  BCM1
 SG_ ZV_LED_Steuerung : 24|1@1+ (1.0,0.0) [0.0|1] ""  Vector__XXX
 SG_ ZV_LED_Uebernahme : 25|1@1+ (1.0,0.0) [0.0|1] ""  Vector__XXX
 SG_ ZV_auf_FT : 26|1@1+ (1.0,0.0) [0.0|1] ""  BCM1
 SG_ ZV_zu_FT : 27|1@1+ (1.0,0.0) [0.0|1] ""  Vector__XXX
 SG_ ZV_auf_BT : 28|1@1+ (1.0,0.0) [0.0|1] ""  BCM1
 SG_ ZV_zu_BT : 29|1@1+ (1.0,0.0) [0.0|1] ""  Vector__XXX
 SG_ ZV_auf_Kessy : 30|1@1+ (1.0,0.0) [0.0|1] ""  BCM1,Klima_MSB
 SG_ ZV_zu_Kessy : 31|1@1+ (1.0,0.0) [0.0|1] ""  BCM1
 SG_ ZV_auf_Funk : 32|1@1+ (1.0,0.0) [0.0|1] ""  BCM1,Klima_MSB
 SG_ ZV_zu_Funk : 33|1@1+ (1.0,0.0) [0.0|1] ""  BCM1
 SG_ VIP_Sensor_betaetigt : 34|1@1+ (1.0,0.0) [0.0|1] ""  BCM1
 SG_ VIP_Freigabe : 35|1@1+ (1.0,0.0) [0.0|1] ""  Vector__XXX
 SG_ ZV_zu_Zeitl_Nachverr : 36|1@1+ (1.0,0.0) [0.0|1] ""  BCM1
 SG_ ZV_HSK_entriegeln : 37|1@1+ (1.0,0.0) [0.0|1] ""  Vector__XXX
 SG_ ZV_HSK_verriegeln : 38|1@1+ (1.0,0.0) [0.0|1] ""  Vector__XXX
 SG_ ZV_Verdeck_zu : 39|1@1+ (1.0,0.0) [0.0|1] ""  Vector__XXX
 SG_ ZV_Verdeck_auf : 40|1@1+ (1.0,0.0) [0.0|1] ""  Vector__XXX
 SG_ FH_FT_hoch : 41|1@1+ (1.0,0.0) [0.0|1] ""  Vector__XXX
 SG_ FH_FT_tief : 42|1@1+ (1.0,0.0) [0.0|1] ""  Vector__XXX
 SG_ FH_BT_hoch : 43|1@1+ (1.0,0.0) [0.0|1] ""  Vector__XXX
 SG_ FH_BT_tief : 44|1@1+ (1.0,0.0) [0.0|1] ""  Vector__XXX
 SG_ FH_HFS_hoch : 45|1@1+ (1.0,0.0) [0.0|1] ""  Vector__XXX
 SG_ FH_HFS_tief : 46|1@1+ (1.0,0.0) [0.0|1] ""  Vector__XXX
 SG_ FH_HBFS_hoch : 47|1@1+ (1.0,0.0) [0.0|1] ""  Vector__XXX
 SG_ FH_HBFS_tief : 48|1@1+ (1.0,0.0) [0.0|1] ""  Vector__XXX
 SG_ BCM_Spg_Synchron : 49|1@1+ (1.0,0.0) [0.0|1] ""  Vector__XXX
 SG_ BCM_BF_Spg_Absenkung : 50|1@1+ (1.0,0.0) [0.0|1] ""  Vector__XXX
 SG_ ZV_Signatur : 51|11@1+ (1,0) [0|2047] ""  Vector__XXX
 SG_ ZV_entriegeln_Anf : 62|1@1+ (1.0,0.0) [0.0|1] ""  Vector__XXX
 SG_ ZV_auto_Ansteuerung : 63|1@1+ (1.0,0.0) [0.0|1] ""  Vector__XXX

BO_ 1411 ZV_02: 8 Gateway
 SG_ BCM_FH_Freigabe : 12|1@1+ (1.0,0.0) [0.0|1] ""  Vector__XXX
 SG_ BCM_Komfortfkt_Freigabe : 13|1@1+ (1.0,0.0) [0.0|1] ""  BCM1
 SG_ BCM_HSK_Freigabe : 14|1@1+ (1.0,0.0) [0.0|1] ""  Vector__XXX
 SG_ BCM_Verdeck_Freigabe : 15|1@1+ (1.0,0.0) [0.0|1] ""  Vector__XXX
 SG_ ZV_verriegelt_intern_ist : 16|1@1+ (1.0,0.0) [0.0|1] ""  BCM1,Klima_MSB,VAS_L,VAS_R
 SG_ ZV_verriegelt_extern_ist : 17|1@1+ (1.0,0.0) [0.0|1] ""  BCM1,Klima_MSB,VAS_L,VAS_R
 SG_ ZV_verriegelt_intern_soll : 18|1@1+ (1.0,0.0) [0.0|1] ""  BCM1,Klima_MSB
 SG_ ZV_verriegelt_extern_soll : 19|1@1+ (1.0,0.0) [0.0|1] ""  BCM1,Klima_MSB
 SG_ ZV_gesafet_extern_ist : 20|1@1+ (1.0,0.0) [0.0|1] ""  BCM1
 SG_ ZV_gesafet_extern_soll : 21|1@1+ (1.0,0.0) [0.0|1] ""  BCM1
 SG_ ZV_Einzeltuerentriegelung : 22|1@1+ (1.0,0.0) [0.0|1] ""  Vector__XXX
 SG_ ZV_Heckeinzelentriegelung : 23|1@1+ (1.0,0.0) [0.0|1] ""  Vector__XXX
 SG_ ZV_FT_offen : 24|1@1+ (1.0,0.0) [0.0|1] ""  BCM1
 SG_ ZV_BT_offen : 25|1@1+ (1.0,0.0) [0.0|1] ""  BCM1
 SG_ ZV_HFS_offen : 26|1@1+ (1.0,0.0) [0.0|1] ""  BCM1
 SG_ ZV_HBFS_offen : 27|1@1+ (1.0,0.0) [0.0|1] ""  BCM1
 SG_ ZV_HD_offen : 28|1@1+ (1.0,0.0) [0.0|1] ""  BCM1
 SG_ ZV_HS_offen : 29|1@1+ (1.0,0.0) [0.0|1] ""  BCM1
 SG_ IRUE_aktiv : 30|1@1+ (1.0,0.0) [0.0|1] ""  Vector__XXX
 SG_ DWA_aktiv : 31|1@1+ (1.0,0.0) [0.0|1] ""  BCM1
 SG_ HD_Hauptraste : 32|1@1+ (1.0,0.0) [0.0|1] ""  Vector__XXX
 SG_ HD_Vorraste : 33|1@1+ (1.0,0.0) [0.0|1] ""  Vector__XXX
 SG_ FFB_CarFinder : 38|1@1+ (1.0,0.0) [0.0|1] ""  Vector__XXX
 SG_ FFB_Komfortoeffnen : 39|1@1+ (1.0,0.0) [0.0|1] ""  Vector__XXX
 SG_ FFB_Komfortschliessen : 40|1@1+ (1.0,0.0) [0.0|1] ""  Vector__XXX
 SG_ ZV_Schluessel_Zugang : 42|4@1+ (1.0,0.0) [0.0|15] ""  BCM1,Klima_MSB
 SG_ ZV_SafeFunktion_aktiv : 46|1@1+ (1.0,0.0) [0.0|1] ""  Vector__XXX
 SG_ FBS_Warn_Schluessel_Batt : 47|1@1+ (1.0,0.0) [0.0|1] ""  Vector__XXX
 SG_ ZV_Oeffnungsmodus : 48|2@1+ (1.0,0.0) [0.0|3] ""  Vector__XXX
 SG_ HFS_verriegelt : 50|1@1+ (1.0,0.0) [0.0|1] ""  Vector__XXX
 SG_ HFS_gesafet : 51|1@1+ (1.0,0.0) [0.0|1] ""  Vector__XXX
 SG_ HBFS_verriegelt : 52|1@1+ (1.0,0.0) [0.0|1] ""  Vector__XXX
 SG_ HBFS_gesafet : 53|1@1+ (1.0,0.0) [0.0|1] ""  Vector__XXX
 SG_ ZV_ist_Zustand_verfuegbar : 54|1@1+ (1.0,0.0) [0.0|1] ""  BCM1
 SG_ IRUE_Taster_Fkts_LED : 55|1@1+ (1.0,0.0) [0.0|1] ""  Vector__XXX
 SG_ ZV_Tankklappe_offen : 56|1@1+ (1.0,0.0) [0.0|1] ""  Vector__XXX
 SG_ ZV_Rollo_auf : 57|1@1+ (1.0,0.0) [0.0|1] ""  Vector__XXX
 SG_ ZV_Rollo_zu : 58|1@1+ (1.0,0.0) [0.0|1] ""  Vector__XXX
 SG_ ZV_SAD_auf : 59|1@1+ (1.0,0.0) [0.0|1] ""  Vector__XXX
 SG_ ZV_SAD_zu : 60|1@1+ (1.0,0.0) [0.0|1] ""  Vector__XXX
 SG_ BCM_Tankklappensteller_Fehler : 61|1@1+ (1.0,0.0) [0.0|1] ""  Vector__XXX
 SG_ ZV_verriegelt_soll : 62|2@1+ (1.0,0.0) [0.0|3] ""  Vector__XXX

BO_TX_BU_ 976 :Gateway,Gateway_PAG;
BO_TX_BU_ 1449 :Gateway,Gateway_PAG;
BO_TX_BU_ 975 :Gateway,Gateway_PAG;
BO_TX_BU_ 1457 :Gateway,Gateway_PAG;
BO_TX_BU_ 974 :Gateway,Gateway_PAG;
BO_TX_BU_ 1458 :Gateway,Gateway_PAG;
BO_TX_BU_ 346 :Gateway,Gateway_PAG;
BO_TX_BU_ 1718 :Gateway,Gateway_PAG;
BO_TX_BU_ 995 :Gateway,Gateway_PAG;
BO_TX_BU_ 1716 :Gateway,Gateway_PAG;
BO_TX_BU_ 1361 :Gateway,Gateway_PAG;
BO_TX_BU_ 2463978613 :Gateway,Gateway_PAG;
BO_TX_BU_ 388 :Gateway,Gateway_PAG;
BO_TX_BU_ 1411 :Gateway,Gateway_PAG;
CM_ BO_ 976 "ab MQB 7.05";
CM_ BO_ 995 "ab MQB IS5";
CM_ BO_ 1716 "200ms bei D4 und folgende";
CM_ BO_ 1702 "MLBevo";

CM_ SG_ 976 ASW_HMI_defekt "HMI Status der Funktion AusstiegsWarnung (ASW). HMI wird durch das TSG angesteuert.";
CM_ SG_ 976 ASW_wakeup "Trigger Start Nachlaufzeit t_1 für die Funktion Ausstieswarnung (ASW)";
CM_ SG_ 976 ASW_Warnung_aktiv_FS "Abschaltung der Ambientefunktion Fahrertür bei aktiver ASW Warnung an der Fahrertür";
CM_ SG_ 976 FS_Status_eTAG "Status des elektrischen Tueraussengriffes Fahrertuer";
CM_ SG_ 976 FT_BFS_Fond_Freigabe "Freigabe für Fondverstellung";
CM_ SG_ 976 FT_Daemmglas "Daemmglas verbaut";
CM_ SG_ 976 FT_FH_Bew_hoch "Fensterheber in Bewegung Richtung hoch";
CM_ SG_ 976 FT_FH_Bew_tief "Fensterheber in Bewegung Richtung tief";
CM_ SG_ 976 FT_FH_Block "Fensterscheibe befindet sich im mechanischen Block (oben oder unten)";
CM_ SG_ 976 FT_FH_Fang "Fangbereich ist 4mm von oberer Lippendichtung";
CM_ SG_ 976 FT_FH_normiert "Die Position der Fensterheberscheibe ist bekannt";
CM_ SG_ 976 FT_FH_Oeffnung "Gibt den Fensteröffnungswert in % an.";
CM_ SG_ 976 FT_FH_S_AutoHoch "FH Schalter automatisch hoch gedrückt";
CM_ SG_ 976 FT_FH_S_AutoTief "FH Schalter automatisch tief gedrückt";
CM_ SG_ 976 FT_FH_S_ManHoch "FH Schalter manuell hoch gedrückt";
CM_ SG_ 976 FT_FH_S_ManTief "FH Schalter manuell tief gedrückt";
CM_ SG_ 976 FT_FH_Thermo "gibt an ob Fensterheber im Thermoschutz ist";
CM_ SG_ 976 FT_gesafet "Im Zustand Safe wird auch das Signal FT_verriegelt = 1 gesendet";
CM_ SG_ 976 FT_HD_Taste "Taste in der Fahrertür zum Öffnen des Heckschlosses";
CM_ SG_ 976 FT_HD_Taste_2 "2. HD-Taste im Bedienfeld 
Funktion: Heckdeckel schließen";
CM_ SG_ 976 FT_IRUE_Taste "Betätigung IRUE-Taster (Innenraumüberwachung)
MQB: Bei Verbau eines einzelnen Taster zur Deaktivierung von IRUE und NGS wird dieses Signal als Deaktivierungsanforderung beider DWA-Alarmquellen gesendet.";
CM_ SG_ 976 FT_Kisi_Fehler "Fehlerstatus Kindersicherungsfunktion";
CM_ SG_ 976 FT_Kisi_li_aktiv "Aktivierungsstatus der Kindersicherung links";
CM_ SG_ 976 FT_Kisi_re_aktiv "Aktivierungsstatus der Kindersicherung rechts";
CM_ SG_ 976 FT_Kisi_Taster_li "Linker Kisi Taster betaetigt";
CM_ SG_ 976 FT_Kisi_Taster_re "Rechter Kisi Taster betaetigt";
CM_ SG_ 976 FT_Lock_Taster "Verriegelungstaster betätigt";
CM_ SG_ 976 FT_Oben_Block_erw "Fensterheber in Blockerwartung oben";
CM_ SG_ 976 FT_Schliesstaster "Vorhalt";
CM_ SG_ 976 FT_Schluesselschalter_auf "Schlüsselschalter Richtung auf betätigt";
CM_ SG_ 976 FT_SP_ausgerastet "Spiegel ausgerastet";
CM_ SG_ 976 FT_Sp_Blk_def "Blinker am Spiegel defekt";
CM_ SG_ 976 FT_Sp_Heizung_Anf "Kundenanforderung der Außenspiegelheizung Fahrertür";
CM_ SG_ 976 FT_SP_Heizung_Status "Status der Spiegelheizung";
CM_ SG_ 976 FT_SP_ht_aktiv "Spiegelverstellung in Richtung hoch/tief aktiv";
CM_ SG_ 976 FT_SP_lr_aktiv "Spiegelverstellung in Richtung links/rechts aktiv";
CM_ SG_ 976 FT_Sperrklinke "Vorraste für Schloß

zwischen Vor- und Hauptraste Signal kurz auf 1, danach wieder auf 0 wenn Tür in Hauptraste (Tür ist sicher zu wenn Sperrklinke und Türkontakt auf 0 sind)";
CM_ SG_ 976 FT_SWA_Taster "SWA/ASW Taster Fahrertür";
CM_ SG_ 976 FT_TAG_betaetigt "Türaussengriff

wird nicht im MLB-B8 verwendet";
CM_ SG_ 976 FT_TD_Taste "Tankdeckelentriegelungs-Taste betätigt";
CM_ SG_ 976 FT_TD_Taste_Fehler "Fehlerstatus des Tankdeckelentriegelungstasters. Wird bei Drucktankkonzepten vom MSG zusammen mit dem Signal FT_TD_Taste ausgewertet, um Tankbereitschaft herzustellen.
Der Fehler beschreibt einen hängenden TD_Taster. Ein Kurzschluss oder Leitungsunterbre";
CM_ SG_ 976 FT_TIG_betaetigt "Türinnengriff

wird nicht im MLB-B8 verwendet";
CM_ SG_ 976 FT_Tuer_geoeffnet "Zeigt eine geöffnete Tür an";
CM_ SG_ 976 FT_Tuerschloss_defekt "Das Fahrertürschloss ist nicht mehr funktionsfähig.";
CM_ SG_ 976 FT_UEKB_aktiviert "Überschutzbegrenzungskraft bei Reversieren";
CM_ SG_ 976 FT_Unlock_Taster "Entriegelungstaster betätigt";
CM_ SG_ 976 FT_Unten_Block_erw "Fensterheber in Blockerwartung unten";
CM_ SG_ 976 FT_verriegelt "Zeigt eine verriegelte Tür an ( Status wird erst nach vollständiger Schlossansteuerung ausgegeben (<=1,5sek))";
CM_ SG_ 976 FT_Zuziehhilfe_aktiv "Zuziehhilfe aktiv";
CM_ SG_ 976 SSR_Temp_Freigabe "Freigabe des Seitenscheibenrollos. Bit wird  für die Deaktivierung des SSR bei Innenraumtemperaturen kleiner -10 Grad verwendet.";
CM_ SG_ 976 SWA_HMI_Diagnose "SWA HMI Diagnose beim TSG";

CM_ SG_ 1449 TSG_FlHz_FS_FnAbbruchHzKreis_A "Flächenheizung: Status";
CM_ SG_ 1449 TSG_FlHz_FS_FnAbbruchHzKreis_B "Flächenheizung: Status";
CM_ SG_ 1449 TSG_FlHz_FS_NTC_A "Flächenheizung: Temperatur und Fehlerwert des Heizaktors";
CM_ SG_ 1449 TSG_FlHz_FS_NTC_B "Flächenheizung: Temperatur und Fehlerwert des Heizaktors";

CM_ SG_ 975 ASW_Warnung_aktiv_HBFS "Abschaltung der Ambientefunktion Tür hinten der Beifahrerseite bei aktiver ASW Warnung an der Fahrertür";
CM_ SG_ 975 HBFS_FH_Bew_hoch "HBFS Fenster bewegt sich in Richtung hoch";
CM_ SG_ 975 HBFS_FH_Bew_tief "HBFS Fenster bewegt sich in Richtung tief";
CM_ SG_ 975 HBFS_FH_Block "Fensterscheibe befindet sich im mechanischen Block (oben oder unten)";
CM_ SG_ 975 HBFS_FH_Fang "Fangbereich ist 4mm von oberer Lippendichtung";
CM_ SG_ 975 HBFS_FH_normiert "Die Position der Fensterheberscheibe ist bekannt.";
CM_ SG_ 975 HBFS_FH_Oeffnung "Gibt den Fensteröffnungswert in % an.";
CM_ SG_ 975 HBFS_FH_S_AutoHoch "Betaetigung FH Schalter auto tief ";
CM_ SG_ 975 HBFS_FH_S_AutoTief "Betaetigung FH Schalter auto hoch";
CM_ SG_ 975 HBFS_FH_S_HFS_AutoHoch "Automatisches Hochfahren der Seitenscheibe HFS";
CM_ SG_ 975 HBFS_FH_S_HFS_AutoTief "Automatisches Absenken der Seitenscheibe HFS";
CM_ SG_ 975 HBFS_FH_S_HFS_ManHoch "Manuelles Hochfahren der Seitenscheibe HFS";
CM_ SG_ 975 HBFS_FH_S_HFS_ManTief "Manuelles Absenken der Seitenscheibe HFS";
CM_ SG_ 975 HBFS_FH_S_ManHoch "Betaetigung FH Schalter man hoch ";
CM_ SG_ 975 HBFS_FH_S_ManTief "Betaetigung FH Schalter man tief";
CM_ SG_ 975 HBFS_FH_Thermo "gibt an ob Fensterheber im Thermoschutz ist";
CM_ SG_ 975 HBFS_gesafet "HBFS Tuer gesafet.
Im Zustand Safe wird auch das Signal HBFS_verriegelt = 1 gesendet.";
CM_ SG_ 975 HBFS_Heckrollotaster_betaetigt "Verfahren des Heckrollos in Richtung Hoch

Bei Einfachtaster wird Bit als Togglebit verwendet (Heckrollo hoch, tief)";
CM_ SG_ 975 HBFS_Lock_Taster "Betaetigung Lock-Taster";
CM_ SG_ 975 HBFS_Lock_Taster_inv "Lock Taster nicht betätigt";
CM_ SG_ 975 HBFS_MRollo_Schalter "  | MRollo2
-----------------------------
0 | nicht_betaetigt
1 | (m) Zu
2 | (a) Zu
3 | (m) Auf
4 | (a) Auf
5 | Schalter nicht verfuegbar
6 | Init
7 | Fehlerfall";
CM_ SG_ 975 HBFS_Oben_Block_erw "Fensterheber in Blockerwartung oben";
CM_ SG_ 975 HBFS_SAD_Schalter "  |   Ausstelldach MD3
-----------------------------
0 | nicht_betaetigt
1 |
2 |
3 |
4 |
5 | (m) Auf
6 | (a) Auf
7 | (m) Zu
8 | (a) Zu
13| Schalter nicht verfuegbar
14| Init
15| Fehlerfall";
CM_ SG_ 975 HBFS_Seitenrollo_tief "Seitenrollo in Bewegung Richtung tief";
CM_ SG_ 975 HBFS_Sperrklinke "Vorraste für Schloß

zwischen Vor- und Hauptraste Signal kurz auf 1, danach wieder auf 0 wenn Tür in Hauptraste (Tür ist sicher zu wenn Sperrklinke und Türkontakt auf 0 sind)";
CM_ SG_ 975 HBFS_Status_eTAG "Status des elektrischen Tueraussengriffes Tuer Beifahrerseite hinten";
CM_ SG_ 975 HBFS_Status_KiSi "Status Kindersicherung HBFS
";
CM_ SG_ 975 HBFS_Status_KiSi_inv "Inverser Status der elektrischen Kindersicherung Beifahrerseite hinten";
CM_ SG_ 975 HBFS_TAG_betaetigt "Betaetigung Türaussengriff";
CM_ SG_ 975 HBFS_TIG_betaetigt "Betaetigung Tuerinnengriff";
CM_ SG_ 975 HBFS_TIG_betaetigt_schliessen "Türinnenbetätigung, Taster Tür schließen.";
CM_ SG_ 975 HBFS_Tuer_geoeffnet "HBFS Tuer geoeffnet";
CM_ SG_ 975 HBFS_Tuer_Status "Türstatus mit Fehler und Initwert";
CM_ SG_ 975 HBFS_Tuer_Status_QBit "Dieses Bit gibt die Zuverlässigkeit des Türkontakts an. Ein auf dieses Bit folgender Fehlereintrag ist mit dem Sender des Bits abzustimmen (gültig ab PPE).";
CM_ SG_ 975 HBFS_Tueroeffnen_Warnung "Bit wird gesetzt, wenn Tür während der Fahrt geoeffnet werden soll.";
CM_ SG_ 975 HBFS_Tuerschloss_defekt "Das hintere Tuerschloss auf der Beifahrerseite ist nicht mehr funktionsfähig.";
CM_ SG_ 975 HBFS_UEKB_aktiviert "Überschutzbegrenzungskraft bei Reversieren";
CM_ SG_ 975 HBFS_Unlock_Taster "Betaetigung Unlock Taster";
CM_ SG_ 975 HBFS_Unten_Block_erw "Fensterheber in Blockerwartung unten";
CM_ SG_ 975 HBFS_verriegelt "Verriegelungsstatus Tür";
CM_ SG_ 975 HBFS_Zuziehhilfe_aktiv "Zuziehhilfe aktiv";
CM_ SG_ 975 MTHBFS_M_Taste "Betätigung M-Taste HBFS";
CM_ SG_ 975 MTHBFS_Pos1 "Betätigung Postionstaste 1 HBFS";
CM_ SG_ 975 MTHBFS_Pos2 "Betätigung Postionstaste 2 HBFS
";
CM_ SG_ 975 MTHBFS_Pos3 "Betätigung Postionstaste 3 HBFS";
CM_ SG_ 975 SSR_HBFS_Pos_Unten "Signal für die 'Global Close'. Über dieses Bit wissen die anderen TSGs, ob der SSR oder der FH verfahren werden darf.";

CM_ SG_ 1457 TSG_FlHz_HBFS_FnAbbruchHzKreis_A "Flächenheizung: Status";
CM_ SG_ 1457 TSG_FlHz_HBFS_FnAbbruchHzKreis_B "Flächenheizung: Status";
CM_ SG_ 1457 TSG_FlHz_HBFS_NTC_A "Flächenheizung: Temperatur und Fehlerwert des Heizaktors";
CM_ SG_ 1457 TSG_FlHz_HBFS_NTC_B "Flächenheizung: Temperatur und Fehlerwert des Heizaktors";

CM_ SG_ 974 ASW_Warnung_aktiv_HFS "Abschaltung der Ambientefunktion Tür hinten der Fahrerseite bei aktiver ASW Warnung an der Fahrertür";
CM_ SG_ 974 HFS_FH_Bew_hoch "HFS Fenster bewegt sich in Richtung hoch";
CM_ SG_ 974 HFS_FH_Bew_tief "HFS Fenster bewegt sich in Richtung tief";
CM_ SG_ 974 HFS_FH_Block "Fensterscheibe befindet sich im mechanischen Block (oben oder unten)";
CM_ SG_ 974 HFS_FH_Fang "Fangbereich ist 4mm von oberer Lippendichtung";
CM_ SG_ 974 HFS_FH_normiert "Die Position der Fensterheberscheibe ist bekannt.";
CM_ SG_ 974 HFS_FH_Oeffnung "Gibt den Fensteröffnungswert in % an.";
CM_ SG_ 974 HFS_FH_S_AutoHoch "Betaetigung FH Schalter auto hoch";
CM_ SG_ 974 HFS_FH_S_AutoTief "Betaetigung FH Schalter auto tief ";
CM_ SG_ 974 HFS_FH_S_HBFS_AutoHoch "Automatisches Hochfahren der Seitenscheibe HBFS";
CM_ SG_ 974 HFS_FH_S_HBFS_AutoTief "Automatisches Absenken der Seitenscheibe HBFS";
CM_ SG_ 974 HFS_FH_S_HBFS_ManHoch "Manuelles Hochfahren der Seitenscheibe HBFS";
CM_ SG_ 974 HFS_FH_S_HBFS_ManTief "Manuelles Absenken der Seitenscheibe HBFS";
CM_ SG_ 974 HFS_FH_S_ManHoch "Betaetigung FH Schalter man hoch ";
CM_ SG_ 974 HFS_FH_S_ManTief "Betaetigung FH Schalter man tief";
CM_ SG_ 974 HFS_FH_Thermo "gibt an ob Fensterheber im Thermoschutz ist";
CM_ SG_ 974 HFS_gesafet "HFS Tuer gesafet.
Im Zustand Safe wird auch das Signal HFS_verriegelt = 1 gesendet.";
CM_ SG_ 974 HFS_Heckrollotaster_betaetigt "Verfahren des Heckrollos in Richtung Hoch

Bei Einfachtaster wird Bit als Togglebit verwendet (Heckrollo hoch, tief)";
CM_ SG_ 974 HFS_Lock_Taster "Betätigung Lock-Taster";
CM_ SG_ 974 HFS_Lock_Taster_inv "Lock Taster nicht betätigt";
CM_ SG_ 974 HFS_MRollo_Schalter "  | MRollo2
-----------------------------
0 | nicht_betaetigt
1 | (m) Zu
2 | (a) Zu
3 | (m) Auf
4 | (a) Auf
5 | Schalter nicht verfuegbar
6 | Init
7 | Fehlerfall";
CM_ SG_ 974 HFS_Oben_Block_erw "Fensterheber in Blockerwartung oben";
CM_ SG_ 974 HFS_SAD_Schalter "  |   Ausstelldach MD3
-----------------------------
0 | nicht_betaetigt
1 |
2 |
3 |
4 |
5 | (m) Auf
6 | (a) Auf
7 | (m) Zu
8 | (a) Zu
13| Schalter nicht verfuegbar
14| Init
15| Fehlerfall";
CM_ SG_ 974 HFS_Seitenrollo_hoch "Seitenrollo in Bewegung Richtung hoch";
CM_ SG_ 974 HFS_Seitenrollo_tief "Seitenrollo in Bewegung Richtung tief";
CM_ SG_ 974 HFS_Sperrklinke "Vorraste für Schloß

zwischen Vor- und Hauptraste Signal kurz auf 1, danach wieder auf 0 wenn Tür in Hauptraste (Tür ist sicher zu wenn Sperrklinke und Türkontakt auf 0 sind)";
CM_ SG_ 974 HFS_Status_eTAG "Status des elektrischen Tueraussengriffes Tuer Fahrerseite hinten";
CM_ SG_ 974 HFS_Status_KiSi "Status Kindersicherung hinten Fahrerseite";
CM_ SG_ 974 HFS_TAG_betaetigt "Betaetigung Türaussengriff";
CM_ SG_ 974 HFS_TCR_Mode_aktiv "Signal zeigt eine aktive mechanische Redundanz am Türschloss an.";
CM_ SG_ 974 HFS_TIG_betaetigt "Betaetigung Türinnengriff";
CM_ SG_ 974 HFS_Tuer_geoeffnet "HFS Tuer geoeffnet";
CM_ SG_ 974 HFS_Tuer_Status "Türstatus mit Fehler und Initwert";
CM_ SG_ 974 HFS_Tuer_Status_QBit "Dieses Bit gibt die Zuverlässigkeit des Türkontakts an. Ein auf dieses Bit folgender Fehlereintrag ist mit dem Sender des Bits abzustimmen (gültig ab PPE).";
CM_ SG_ 974 HFS_Tueroeffnen_Warnung "Bit wird gesetzt, wenn Tür während der Fahrt geoeffnet werden soll.";
CM_ SG_ 974 HFS_Tuerschloss_defekt "Das hintere Tuerschloss auf der Fahrerseite ist nicht mehr funktionsfähig.";
CM_ SG_ 974 HFS_UEKB_aktiviert "Überschutzbegrenzungskraft bei Reversieren";
CM_ SG_ 974 HFS_Unlock_Taster "Betaetigung Unlock Taster";
CM_ SG_ 974 HFS_Unten_Block_erw "Fensterheber in Blockerwartung unten";
CM_ SG_ 974 HFS_verriegelt "HFS Tuer verriegelt";
CM_ SG_ 974 HFS_Zuziehhilfe_aktiv "Zuziehhilfe aktiv";
CM_ SG_ 974 MTHFS_M_Taste "Betätigung M-Taste HFS";
CM_ SG_ 974 MTHFS_Pos1 "Betätigung Postionstaste 1 HFS";
CM_ SG_ 974 MTHFS_Pos2 "Betätigung Postionstaste 2 HFS
";
CM_ SG_ 974 MTHFS_Pos3 "Betätigung Postionstaste 3 HFS";
CM_ SG_ 974 SSR_HFS_Pos_Unten "Signal für die 'Global Close'. Über dieses Bit wissen die anderen TSGs, ob der SSR oder der FH verfahren werden darf.";

CM_ SG_ 1458 TSG_FlHz_HFS_FnAbbruchHzKreis_A "Flächenheizung: Status";
CM_ SG_ 1458 TSG_FlHz_HFS_FnAbbruchHzKreis_B "Flächenheizung: Status";
CM_ SG_ 1458 TSG_FlHz_HFS_NTC_A "Flächenheizung: Temperatur und Fehlerwert des Heizaktors";
CM_ SG_ 1458 TSG_FlHz_HFS_NTC_B "Flächenheizung: Temperatur und Fehlerwert des Heizaktors";

CM_ SG_ 346 MO_Anforderung_HMS "Halteanforderung vom Motor an HMS";
CM_ SG_ 346 TSK_08_CRC "Für MLB:
'Berechnung siehe Lastenheft 'Kommunikationsabsicherung für FlexRay und CAN''

Ab MQB und MLBevo:
'Berechnung siehe Lastenheft 'End-to-End Kommunikationsabsicherung''

Endwerte siehe Begleitdokument 'S-PDU Kennungsfolgen'";
CM_ SG_ 346 TSK_aktives_System "Anzeige der in der TSK-Längsführung aktiven Funktion";
CM_ SG_ 346 TSK_Anf_Antriebsmoment "Das Signal zeigt an, ob die TSK-Laengsregelung aktuell Antriebsmoment anfordert, zur Verwendung in der ASR/EDS-Funktion";
CM_ SG_ 346 TSK_Einheit_vMax_Fahrerassistenz "Einheit zu Signal TSK_vMax_Fahrerassistenz";
CM_ SG_ 346 TSK_erhoehter_Fahrwiderstand "Rueckmeldung vom Triebstrangkoordinator, dass eine große Reglerdifferenz detektiert wurde. Soll ermoeglichen, einen ggfs. unbekannten Fahrwiderstand am Boden zu erkennen.";
CM_ SG_ 346 TSK_Status_ARA "Funktionsstatus des Triebstrangkoordinators für den Anhängerrangierassistenten";
CM_ SG_ 346 TSK_Status_EA "Funktionsstatus des Triebstrangkoordinators für den Anforderer Emergency Assist";
CM_ SG_ 346 TSK_Status_IPA "Funktionsstatus des Triebstrangkoordinators für die Längsführung des Einparkassistenten";
CM_ SG_ 346 TSK_Status_PLA "Funktionsstatus des Triebstrangkoordinators für den Speedlimiter des Parkassistenten";
CM_ SG_ 346 TSK_vMax_aktuell "Im aktuellen Betriebszustand global gültige Geschwindigkeitslimitierung.";
CM_ SG_ 346 TSK_vMax_Fahrerassistenz "maximale Sollgeschwindigkeit für GRA/ACC/Limiter
Hinweis: Signal ist mit Signal TSK_Einheit_vMax_Fahrerassistenz zu interpretieren.  Das Signal wird abwechselnd in km/h und mph gesendet.";

CM_ SG_ 2589283609 UGDO_Channel_1 "Anlernstatus Kanal X für pilotiertes Parken.";
CM_ SG_ 2589283609 UGDO_Channel_10 "Anlernstatus Kanal X für pilotiertes Parken.";
CM_ SG_ 2589283609 UGDO_Channel_11 "Anlernstatus Kanal X für pilotiertes Parken.";
CM_ SG_ 2589283609 UGDO_Channel_12 "Anlernstatus Kanal X für pilotiertes Parken.";
CM_ SG_ 2589283609 UGDO_Channel_13 "Anlernstatus Kanal X für pilotiertes Parken.";
CM_ SG_ 2589283609 UGDO_Channel_14 "Anlernstatus Kanal X für pilotiertes Parken.";
CM_ SG_ 2589283609 UGDO_Channel_15 "Anlernstatus Kanal X für pilotiertes Parken.";
CM_ SG_ 2589283609 UGDO_Channel_2 "Anlernstatus Kanal X für pilotiertes Parken.";
CM_ SG_ 2589283609 UGDO_Channel_3 "Anlernstatus Kanal X für pilotiertes Parken.";
CM_ SG_ 2589283609 UGDO_Channel_4 "Anlernstatus Kanal X für pilotiertes Parken.";
CM_ SG_ 2589283609 UGDO_Channel_5 "Anlernstatus Kanal X für pilotiertes Parken.";
CM_ SG_ 2589283609 UGDO_Channel_6 "Anlernstatus Kanal X für pilotiertes Parken.";
CM_ SG_ 2589283609 UGDO_Channel_7 "Anlernstatus Kanal X für pilotiertes Parken.";
CM_ SG_ 2589283609 UGDO_Channel_8 "Anlernstatus Kanal X für pilotiertes Parken.";
CM_ SG_ 2589283609 UGDO_Channel_9 "Anlernstatus Kanal X für pilotiertes Parken.";
CM_ SG_ 2589283609 UGDO_DoorState "Ausgabe des Garagentorstatus für pilotiertes Parken.";
CM_ SG_ 2589283609 UGDO_Failure_Antenne "UGDO = LIN-Slave am BCM1.
UGDO-Sender meldet Fehlerstatus ans BCM1.";
CM_ SG_ 2589283609 UGDO_Failure_Codierung "UGDO = LIN-Slave am BCM1.
UGDO-Sender meldet Fehlerstatus ans BCM1.";
CM_ SG_ 2589283609 UGDO_Failure_Hardware "UGDO = LIN-Slave am BCM1.
UGDO-Sender meldet Fehlerstatus ans BCM1.";
CM_ SG_ 2589283609 UGDO_Function_01 "UGDO_Sender = LIN-Slave BCM1
bei Kl.15 AUS wird für 4s noch der letzte Wert gesendet, danach wird der Wert 7 (= Fehler gesendet)";
CM_ SG_ 2589283609 UGDO_LED_Code_01 "UGDO_Sender = LIN-Slave BCM1
Signal wird bei Kl.15 AUS mit dem letzten empfangenen Wert gesendet";
CM_ SG_ 2589283609 UGDO_ResponseError "siehe LIN2.0-Specification
(Darf nicht über ein Fehlergueltigkeitsbit abgesichtert werden!)";

CM_ SG_ 1718 UH_Minute "0x3C- 0x3f = Werte ungültig";
CM_ SG_ 1718 UH_Monat "0x0D, 0xF =  Werte ungültig
0x0E = Relatives Datum (nur VW)";
CM_ SG_ 1718 UH_Sekunde "0x3C- 0x3f = Werte ungültig";
CM_ SG_ 1718 UH_Stunde "0x18 - 0x1F = Werte ungültig";
CM_ SG_ 1718 UH_Tag "0x0: reserviert bei VW";
CM_ SG_ 1718 UH_Typ "0x4 - 0x7 = tbd. ";

CM_ SG_ 2463978633 VAS_L_01_BZ "4bit Botschaftszähler, wird mit jeder Sendebotschaft inkrementiert";
CM_ SG_ 2463978633 VAS_L_01_CRC "Für MLB:
Berechnung siehe Lastenheft 'Kommunikationsabsicherung für FlexRay und CAN'
Ab MQB und MLBevo:
Berechnung siehe Lastenheft 'End-to-End Kommunikationsabsicherung'

Endwerte siehe Begleitdokument 'S-PDU Kennungsfolgen'";
CM_ SG_ 2463978633 VAS_L_Autobahnview_aktiv "Status ob Autobahnview aktiv ist oder nicht";
CM_ SG_ 2463978633 VAS_L_Bedien_Master "Gibt an dass das linke Steuergerät Bedien Master ist";
CM_ SG_ 2463978633 VAS_L_Heizung_Aktiv "VAS rechts Heizung aktiv";
CM_ SG_ 2463978633 VAS_L_HMI_Aktiv "Gibt an ob das HMI angezeigt wird";
CM_ SG_ 2463978633 VAS_L_Parkview_aktiv "VAS links Parkview aktiv";
CM_ SG_ 2463978633 VAS_L_Spiegelauswahl "VAS links Spiegelauswahl";
CM_ SG_ 2463978633 VAS_L_SWA_HMI_Diagnose "SWA HMI Diagnose beim VAS";
CM_ SG_ 2463978633 VAS_L_Texte "Signal uebermittelt die Fahrerhinweise zum Kombi muss E2E abgesichert werden";
CM_ SG_ 2463978633 VAS_L_Turnview_aktiv "Status Turnview Anzeige";
CM_ SG_ 2463978633 VAS_L_Verstell_Pos_X "VAS links Spiegel Verstellposition X";
CM_ SG_ 2463978633 VAS_L_Verstell_Pos_Y "VAS links Spiegel Verstellposition Y";
CM_ SG_ 2463978633 VAS_L_Zoom_Level "VAS links Zoom Level Display";

CM_ SG_ 2463978636 VAS_L_Autobahnview_BAP_Freigabe "BAP Freigabe Autobahnview";
CM_ SG_ 2463978636 VAS_L_Betriebsstunden "Gibt die Bereits gelaufenen Betriebsstunden an zum Abgleich der Display Helligkeiten";
CM_ SG_ 2463978636 VAS_L_DefaultView "Default View aktiviert oder nicht";
CM_ SG_ 2463978636 VAS_L_Dimmung "Dimmungsintensität am VAS links";
CM_ SG_ 2463978636 VAS_L_Dimmung_BAP_Anf "Dimmungs Anforderung über BAP an den VAS Rechts";
CM_ SG_ 2463978636 VAS_L_Display_Sync "VAS links Synchronisierung der Displays beim Startup/Ausschalten";
CM_ SG_ 2463978636 VAS_L_HBM "Status des Highbrightness Modes des linken Aussenspiegels";
CM_ SG_ 2463978636 VAS_L_PanAndZoom_Ctrl_Req_R "Gibt an ob die Verstellung des Signals für PAN oder ZOOM aktiv ist";
CM_ SG_ 2463978636 VAS_L_Parkview_BAP_Freigabe "BAP Freigabe Parkview";
CM_ SG_ 2463978636 VAS_L_Turnview_BAP_Freigabe "BAP Freigabe Turnview";
CM_ SG_ 2463978636 VAS_L_Verstell_Pos_X_Req_R "VAS links Verstellanforderung Position X";
CM_ SG_ 2463978636 VAS_L_Verstell_Pos_Y_Req_R "VAS links Verstellanforderung Position Y";
CM_ SG_ 2463978636 VAS_L_Zoom_Level_Req_R "VAS links Zoom Level Anforderung rechts";

CM_ SG_ 2463978634 VAS_R_01_BZ "4bit Botschaftszähler, wird mit jeder Sendebotschaft inkrementiert";
CM_ SG_ 2463978634 VAS_R_01_CRC "Für MLB:
Berechnung siehe Lastenheft 'Kommunikationsabsicherung für FlexRay und CAN'
Ab MQB und MLBevo:
Berechnung siehe Lastenheft 'End-to-End Kommunikationsabsicherung'

Endwerte siehe Begleitdokument 'S-PDU Kennungsfolgen'";
CM_ SG_ 2463978634 VAS_R_Autobahnview_aktiv "Status der Autobahnview ob aktiv oder deaktiv";
CM_ SG_ 2463978634 VAS_R_Bedien_Master "Gibt an dass das rechte Steuergerät Bedien Master ist";
CM_ SG_ 2463978634 VAS_R_Fahrerwarnung "Signal beinhaltet alle Fahrerwarnungen welche am Kombi angezeigt werden";
CM_ SG_ 2463978634 VAS_R_Heizung_Aktiv "VAS rechts aktive Heizung";
CM_ SG_ 2463978634 VAS_R_HMI_Aktiv "Gibt an ob das HMI angezeigt wird";
CM_ SG_ 2463978634 VAS_R_Parkview_aktiv "VAS rechts Parkview aktiv";
CM_ SG_ 2463978634 VAS_R_Spiegelauswahl "VAS rechts Spiegelauswahl";
CM_ SG_ 2463978634 VAS_R_SWA_HMI_Diagnose "SWA HMI Diagnose beim VAS";
CM_ SG_ 2463978634 VAS_R_Turnview_aktiv "Status Anzeige Turnview des rechten VAS";
CM_ SG_ 2463978634 VAS_R_Verstell_Pos_X "VAS rechts Spiegel Verstellposition X";
CM_ SG_ 2463978634 VAS_R_Verstell_Pos_Y "VAS rechts Spiegel Verstellposition Y";
CM_ SG_ 2463978634 VAS_R_Zoom_Level "VAS rechts Zoom level CMS System";

CM_ SG_ 2463978637 VAS_R_Autobahnview_BAP_Status "Status Rückmeldung BAP Anfage des rechten VAS zur Autobahnview";
CM_ SG_ 2463978637 VAS_R_Betriebsstunden "Gibt die Bereits gelaufenen Betriebsstunden an zum Abgleich der Display Helligkeiten";
CM_ SG_ 2463978637 VAS_R_DefaultView "DefaultView aktiviert oder nicht";
CM_ SG_ 2463978637 VAS_R_Dimmung "Dimmungsintensität am VAS rechts";
CM_ SG_ 2463978637 VAS_R_Dimmung_BAP_Status "Status Rückmeldung VAS R zu BAP Anfrage";
CM_ SG_ 2463978637 VAS_R_Display_Sync "VAS rechts Synchronisierung der Displays beim Startup/Ausschalten";
CM_ SG_ 2463978637 VAS_R_HBM "Status des Highbrightness Modes des rechten Aussenspiegels";
CM_ SG_ 2463978637 VAS_R_PanAndZoom_Ctrl_Req_L "Gibt an ob für die Spiegelverstellung der PAN oder der Zoom aktiv ist";
CM_ SG_ 2463978637 VAS_R_Parkview_BAP_Status "BAP Status Rückmeldung des VAS rechts an den VAS links";
CM_ SG_ 2463978637 VAS_R_Turnview_BAP_Status "Status Rückmeldung BAP Anfage des rechten VAS zur Turnview";
CM_ SG_ 2463978637 VAS_R_Verstell_Pos_X_Req_L "VAS rechts Verstellanforderung Position X";
CM_ SG_ 2463978637 VAS_R_Verstell_Pos_Y_Req_L "VAS rechts Verstellanforderung Position Y";
CM_ SG_ 2463978637 VAS_R_Zoom_Level_Req_L "VAS rechts Anforderung Zoom Level links";

CM_ SG_ 995 VD_SpannungsAnf "Anforderung Forderung des Verdecks zur Spannungsanhebung des Bordnetzes.";
CM_ SG_ 995 Verdeck_01_BZ "4bit Botschaftszähler, wird mit jeder Sendebotschaft inkrementiert";
CM_ SG_ 995 Verdeck_01_CRC "Für MLB:
Berechnung siehe Lastenheft 'Kommunikationsabsicherung für FlexRay und CAN'
Ab MQB und MLBevo:
Berechnung siehe Lastenheft 'End-to-End Kommunikationsabsicherung'

Endwerte siehe Begleitdokument 'S-PDU Kennungsfolgen'";
CM_ SG_ 995 VS_BFS_AutoHoch "automatischer Hochlauf des BFS Fenster ausgelöst durch die Verdecksteuerung";
CM_ SG_ 995 VS_BFS_AutoTief "automatischer Tieflauf des BFS Fenster ausgelöst durch die Verdecksteuerung";
CM_ SG_ 995 VS_BFS_ManHoch "manueller Hochlauf des BFS Fenster ausgelöst durch die Verdecksteuerung";
CM_ SG_ 995 VS_BFS_ManTief "manueller Tieflauf des BFS Fenster ausgelöst durch die Verdecksteuerung";
CM_ SG_ 995 VS_Buzzer "Buzzeransteuerung: 'Buzzeransteuerung' für Gong 200ms (Kombi)";
CM_ SG_ 995 VS_FH_BT_Langhub "Ansteuerung Fensterheber vom Verdecksteuergeraet";
CM_ SG_ 995 VS_FH_FT_Langhub "Ansteuerung Fensterheber vom Verdecksteuergeraet";
CM_ SG_ 995 VS_FH_HBFS_Langhub "Ansteuerung Fensterheber vom Verdecksteuergeraet";
CM_ SG_ 995 VS_FH_HFS_Langhub "Ansteuerung Fensterheber vom Verdecksteuergeraet";
CM_ SG_ 995 VS_FS_AutoHoch "automatischer Hochlauf des FS Fenster ausgelöst durch die Verdecksteuerung";
CM_ SG_ 995 VS_FS_AutoTief "automatischer Tieflauf des FS Fenster ausgelöst durch die Verdecksteuerung";
CM_ SG_ 995 VS_FS_ManHoch "manueller Hochlauf des FS Fenster ausgelöst durch die Verdecksteuerung";
CM_ SG_ 995 VS_FS_ManTief "manueller Tieflauf des FS Fenster ausgelöst durch die Verdecksteuerung";
CM_ SG_ 995 VS_Hardtop "Hardtop montiert";
CM_ SG_ 995 VS_HBFS_AutoHoch "automatischer Hochlauf des HBFS Fenster ausgelöst durch die Verdecksteuerung";
CM_ SG_ 995 VS_HBFS_AutoTief "automatischer Tieflauf des HBFS Fenster ausgelöst durch die Verdecksteuerung";
CM_ SG_ 995 VS_HBFS_ManHoch "manueller Hochlauf des HBFS Fenster ausgelöst durch die Verdecksteuerung";
CM_ SG_ 995 VS_HBFS_ManTief "manueller Tieflauf des HBFS Fenster ausgelöst durch die Verdecksteuerung";
CM_ SG_ 995 VS_HD_sperren "Bei gesetztem Signal wird der Kofferraum/Heckdeckel durch den BCM2 nicht entriegelt werden.";
CM_ SG_ 995 VS_Heckschloss_auf "Signal wird gesetzt, wenn fuer einen Verdeckbetrieb das Öffnen des Heckschlosses erforderlich ist.";
CM_ SG_ 995 VS_HFS_AutoHoch "automatischer Hochlauf des HFS Fenster ausgelöst durch die Verdecksteuerung";
CM_ SG_ 995 VS_HFS_AutoTief "automatischer Tieflauf des HFS Fenster ausgelöst durch die Verdecksteuerung";
CM_ SG_ 995 VS_HFS_ManHoch "manueller Hochlauf des HFS Fenster ausgelöst durch die Verdecksteuerung";
CM_ SG_ 995 VS_HFS_ManTief "manueller Tieflauf des HFS Fenster ausgelöst durch die Verdecksteuerung";
CM_ SG_ 995 VS_HHS_enable "Fehlende Beschreibung (Import)";
CM_ SG_ 995 VS_Lampe_Blk "Ansteuerung Lampe im Kombi

Wird aktiviert bei Aufprüfen, Verdecklauf und Fehlerfall (blinkend).


";
CM_ SG_ 995 VS_StartStopp_Info "Stopp-Freigabe und Start-Anforderung an den Start-Stopp-Koordinator";
CM_ SG_ 995 VS_VD_Bew_auf "



";
CM_ SG_ 995 VS_VD_Bew_zu "


";
CM_ SG_ 995 VS_VD_entriegelt "Zustand des Verdeck entriegelt";
CM_ SG_ 995 VS_VD_Fehler "Fehlerzustand Verdeck";
CM_ SG_ 995 VS_VD_offen_ver "Zustand des Verdecks verriegelt und offen";
CM_ SG_ 995 VS_VD_zu_ver "
";
CM_ SG_ 995 VS_VD_Zwischenposition "Verdeck in Zwischenposition";
CM_ SG_ 995 VS_VDKD_auf "Signal wird gesetzt, wenn der Verdeckkastendeckel vollstaendig geoeffnet ist



";
CM_ SG_ 995 VS_Verdeck_Anf "Verdeckanforderung (Signalisierung der Bereitschaft zur Verdeckbetaetigung ueber Komfortfunktion)";
CM_ SG_ 995 VS_Windschott_nicht_abgelegt "Windschott ist aufgestellt, in Zwischenposition oder die Position ist unbekannt";
CM_ SG_ 995 VSG_Meldungen "Meldungen fuers Kombi lt. konzernübergreifender Abstimmung

0 -> keine Meldung
1 -> 'Verdeckbetrieb RDW aktiv'
2 -> 'Verdeckbetrieb NAR aktiv'
3 -> 'stehendes Verdeck in Zwischenposition (ZP)'
4 -> 'autom. Verdeck in ZP und KL15 aus'
5 -> 'manuelle";

CM_ SG_ 1716 VIN_01_MUX "Achtung:
Die Botschaft ist nicht linear gemultiplext!!!
Sondern 0,1,0,2,0, usw.";
CM_ SG_ 1716 VIN_1 "Initwert:
0x2D bei Fahrzeugen mit Wegfahrsperrengeneration >= 5 
0x58 bei Fahrzeugen mit Wegfahrsperrengeneration < 5 (z.B. WFS-4)";
CM_ SG_ 1716 VIN_10 "Initwert:
0x2D bei Fahrzeugen mit Wegfahrsperrengeneration >= 5 
0x58 bei Fahrzeugen mit Wegfahrsperrengeneration < 5 (z.B. WFS-4)";
CM_ SG_ 1716 VIN_11 "Initwert:
0x2D bei Fahrzeugen mit Wegfahrsperrengeneration >= 5 
0x58 bei Fahrzeugen mit Wegfahrsperrengeneration < 5 (z.B. WFS-4)";
CM_ SG_ 1716 VIN_12 "Initwert:
0x2D bei Fahrzeugen mit Wegfahrsperrengeneration >= 5 
0x58 bei Fahrzeugen mit Wegfahrsperrengeneration < 5 (z.B. WFS-4)";
CM_ SG_ 1716 VIN_13 "Initwert:
0x2D bei Fahrzeugen mit Wegfahrsperrengeneration >= 5 
0x58 bei Fahrzeugen mit Wegfahrsperrengeneration < 5 (z.B. WFS-4)";
CM_ SG_ 1716 VIN_14 "Initwert:
0x2D bei Fahrzeugen mit Wegfahrsperrengeneration >= 5 
0x58 bei Fahrzeugen mit Wegfahrsperrengeneration < 5 (z.B. WFS-4)";
CM_ SG_ 1716 VIN_15 "Initwert:
0x2D bei Fahrzeugen mit Wegfahrsperrengeneration >= 5 
0x58 bei Fahrzeugen mit Wegfahrsperrengeneration < 5 (z.B. WFS-4)";
CM_ SG_ 1716 VIN_16 "Initwert:
0x2D bei Fahrzeugen mit Wegfahrsperrengeneration >= 5 
0x58 bei Fahrzeugen mit Wegfahrsperrengeneration < 5 (z.B. WFS-4)";
CM_ SG_ 1716 VIN_17 "Initwert:
0x2D bei Fahrzeugen mit Wegfahrsperrengeneration >= 5 
0x58 bei Fahrzeugen mit Wegfahrsperrengeneration < 5 (z.B. WFS-4)";
CM_ SG_ 1716 VIN_2 "Initwert:
0x2D bei Fahrzeugen mit Wegfahrsperrengeneration >= 5 
0x58 bei Fahrzeugen mit Wegfahrsperrengeneration < 5 (z.B. WFS-4)";
CM_ SG_ 1716 VIN_3 "Initwert:
0x2D bei Fahrzeugen mit Wegfahrsperrengeneration >= 5 
0x58 bei Fahrzeugen mit Wegfahrsperrengeneration < 5 (z.B. WFS-4)";
CM_ SG_ 1716 VIN_4 "Initwert:
0x2D bei Fahrzeugen mit Wegfahrsperrengeneration >= 5 
0x58 bei Fahrzeugen mit Wegfahrsperrengeneration < 5 (z.B. WFS-4)";
CM_ SG_ 1716 VIN_5 "Initwert:
0x2D bei Fahrzeugen mit Wegfahrsperrengeneration >= 5 
0x58 bei Fahrzeugen mit Wegfahrsperrengeneration < 5 (z.B. WFS-4)";
CM_ SG_ 1716 VIN_6 "Initwert:
0x2D bei Fahrzeugen mit Wegfahrsperrengeneration >= 5 
0x58 bei Fahrzeugen mit Wegfahrsperrengeneration < 5 (z.B. WFS-4)";
CM_ SG_ 1716 VIN_7 "Initwert:
0x2D bei Fahrzeugen mit Wegfahrsperrengeneration >= 5 
0x58 bei Fahrzeugen mit Wegfahrsperrengeneration < 5 (z.B. WFS-4)";
CM_ SG_ 1716 VIN_8 "Initwert:
0x2D bei Fahrzeugen mit Wegfahrsperrengeneration >= 5 
0x58 bei Fahrzeugen mit Wegfahrsperrengeneration < 5 (z.B. WFS-4)";
CM_ SG_ 1716 VIN_9 "Initwert:
0x2D bei Fahrzeugen mit Wegfahrsperrengeneration >= 5 
0x58 bei Fahrzeugen mit Wegfahrsperrengeneration < 5 (z.B. WFS-4)";

CM_ SG_ 1361 WFS_Betrieb_Lesespule "Schlüsselkommunikation über die Lesespule";
CM_ SG_ 1361 WFS_ELV_authorisiert "Authorisierung der elektrischen Lenkungsverriegelung an der WFS";
CM_ SG_ 1361 WFS_Fahrerhinweise "Meldungen, Fahrer- und Warnhinweise der Wegfahrsperre";
CM_ SG_ 1361 WFS_ID_Geb_autorisiert "Authorisierung Schluessel (ID-Geber)";
CM_ SG_ 1361 WFS_ID_Geb_autorisiert_in_Kl15 "Authorisierung des Schlüssels im aktiven Klemme-15-Zyklus";
CM_ SG_ 1361 WFS_ID_Geb_steckt "Schluessel (ID-Geber) im Zuendschloss
";
CM_ SG_ 1361 WFS_Klemmenfreigabe "Freigabe von der WFS zum Einschalten der Klemme 15 und Klemme S";
CM_ SG_ 1361 WFS_LF_Aktiv "LF Schluesselkommunikation
";
CM_ SG_ 1361 WFS_LZ "Anforderung aus Lastenheft WFS V
";
CM_ SG_ 1361 WFS_Parken_Status "Schnittstelle zwischen WFS und ZFAS für das Pilotierte Parken um in Richtung ZFAS den Status der WFS im BCM2 zu kommunizieren";
CM_ SG_ 1361 WFS_Safe "Status WFS";
CM_ SG_ 1361 WFS_Schluessel_Fahrberecht "Schlüsselnummer Fahrberechtigung
0 = ungueltig, xxxx = Schluessel-Nr.";
CM_ SG_ 1361 WFS_Schluessel_Ist "Istwert der gelernten Schluessel";
CM_ SG_ 1361 WFS_Schluessel_Soll "Sollwert der zu lernenden Schluessel";

CM_ SG_ 1702 BCM1_SRA_aktiv "Status Scheinwerferreinigungsanlage";
CM_ SG_ 1702 Heckwischer_Anforderung "Das Signal beschreibt die Anforderung an den Signalausgang im BCM2 zur Ansteuerung des Heckwischers.";
CM_ SG_ 1702 Waschen_vorne_aktiv "Status: Waschen vorne aktiv";
CM_ SG_ 1702 Wischer1_Wischgeschwindigkeit "aktuelle, durch Sensorik gemessene Wischgeschwindigkeit";
CM_ SG_ 1702 Wischer_Anzeigetext "Das Signal fordert einen Kombi-Pop-Up mit entsprechenden Texten an";
CM_ SG_ 1702 Wischer_vorne_aktiv "Status: Wischer vorne";
CM_ SG_ 1702 Wischer_vorne_blockiert "Blockade Wischer vorne (z.B. durch Schnee)";
CM_ SG_ 1702 Wischer_vorne_defekt "Fehlerstatus Wischer vorne (Anzeige im Kombi)";
CM_ SG_ 1702 Wischer_vorne_Normal "Wischer Front normal aktiv";
CM_ SG_ 1702 Wischer_vorne_Parklage "Wischer Front in Parklage";
CM_ SG_ 1702 Wischer_vorne_Schnell "Wischer vorne schnell aktiv";
CM_ SG_ 1702 WWSs_01_upd "Update-Bit für die LIN-Botschaft WWSs_01.

Betroffene Signale:

Wischer_vorne_aktiv
Wischer1_Wischgeschwindigkeit";

CM_ SG_ 2463978613 ZFAS_01_BZ "Botschaftszaehler";
CM_ SG_ 2463978613 ZFAS_01_CRC "Ab MQB und MLBevo:
'Berechnung siehe Lastenheft 'End-to-End Kommunikationsabsicherung''

Endwerte siehe Begleitdokument 'S-PDU Kennungsfolgen'";
CM_ SG_ 2463978613 zFAS_Blinker_li "Anforderung seitens zFAS für 'Links blinken'";
CM_ SG_ 2463978613 zFAS_Blinker_re "Anforderung seitens zFAS für 'Rechts blinken'";
CM_ SG_ 2463978613 zFAS_Pilottaster_LED_Farbe_Anf "Farbanforderung seitens zFAS für die Korona um den Fahrtaster.";
CM_ SG_ 2463978613 zFAS_Pilottaster_LED_Modus_Anf "Anforderung seitens zFAS für den Sondermodus „Blinken/Pulsieren“ der Korona um den Fahrtaster.";

CM_ SG_ 388 BCM_BF_Spg_Absenkung "Spiegelabsenkung Beifahrerseite";
CM_ SG_ 388 BCM_Spg_Synchron "Anforderung zur Aktivierung der synchronen Spiegelverstellung";
CM_ SG_ 388 FH_BT_hoch "Freigabeinformation fuer die FH-Komfortfunktion";
CM_ SG_ 388 FH_BT_tief "Freigabeinformation fuer die FH-Komfortfunktion";
CM_ SG_ 388 FH_FT_hoch "Freigabeinformation fuer die FH-Komfortfunktion";
CM_ SG_ 388 FH_FT_tief "Freigabeinformation fuer die FH-Komfortfunktion";
CM_ SG_ 388 FH_HBFS_hoch "Freigabeinformation fuer die FH-Komfortfunktion";
CM_ SG_ 388 FH_HBFS_tief "Freigabeinformation fuer die FH-Komfortfunktion";
CM_ SG_ 388 FH_HFS_hoch "Freigabeinformation fuer die FH-Komfortfunktion";
CM_ SG_ 388 FH_HFS_tief "Freigabeinformation fuer die FH-Komfortfunktion";
CM_ SG_ 388 VIP_Freigabe "Vituelles Pedal ist über HMI freigeschaltet.";
CM_ SG_ 388 VIP_Sensor_betaetigt "Heckentriegelung durch die Bedienstelle Virtuelles Pedal(VIP) erkannt. Der VIP Sensor hat eine Fusskickbewegung erkannt und es wurde ein Kessy - Schlüssel im Heckaussenbereich erkannt.";
CM_ SG_ 388 ZV_01_CRC "Für MLB:
'Berechnung siehe Lastenheft 'Kommunikationsabsicherung für FlexRay und CAN''

Ab MQB und MLBevo:
'Berechnung siehe Lastenheft 'End-to-End Kommunikationsabsicherung''

Endwerte siehe Begleitdokument 'S-PDU Kennungsfolgen'";
CM_ SG_ 388 ZV_auf_BT "ZV Schliessstelle";
CM_ SG_ 388 ZV_auf_FT "ZV Schliessstelle";
CM_ SG_ 388 ZV_auf_Funk "ZV Schliessstelle";
CM_ SG_ 388 ZV_auf_Kessy "ZV Schliessstelle";
CM_ SG_ 388 ZV_auto_Ansteuerung "Kennung für die automatische Ansteuerung der Zentralverriegelung (Autolock/Autounlock)";
CM_ SG_ 388 ZV_BT_entriegeln "Beifahrertür entriegeln (Anforderung ZV)";
CM_ SG_ 388 ZV_BT_verriegeln "Verriegelungsanforderung ZV für BT";
CM_ SG_ 388 ZV_entriegeln_Anf "Bei ZV Anforderung erfolgt die Entriegelung des Ladesteckers";
CM_ SG_ 388 ZV_FT_entriegeln "Entriegelungsanforderung ZV für FT";
CM_ SG_ 388 ZV_FT_verriegeln "Verriegelungsanforderung ZV für FT";
CM_ SG_ 388 ZV_HBFS_entriegeln "Entriegelungsanforderung ZV für HBFS
";
CM_ SG_ 388 ZV_HBFS_verriegeln "Verriegelungsanforderung ZV für HBFS
";
CM_ SG_ 388 ZV_HFS_entriegeln "Entriegelungsanforderung ZV für HFS
";
CM_ SG_ 388 ZV_HFS_verriegeln "Verriegelungsanforderung ZV für HFS
";
CM_ SG_ 388 ZV_HSK_entriegeln "Anforderungssignal zur Ansteuerung des Handschuhkastenmotors in Richtung Entriegeln. ";
CM_ SG_ 388 ZV_HSK_verriegeln "Anforderungssignal zur Ansteuerung des Handschuhkastenmotors in Richtung Verriegeln. ";
CM_ SG_ 388 ZV_LED_Steuerung "Ansteuerung der LED's in den Tueren; BAF gilt nicht für dieses Bit";
CM_ SG_ 388 ZV_LED_Uebernahme "Uebernahme der LED Steuerung durch das TSG FT";
CM_ SG_ 388 ZV_Signatur "Signatur der ZV";
CM_ SG_ 388 ZV_Softtouch_betaetigt "Betätigung Softtouch";
CM_ SG_ 388 ZV_Spg_Anklappen "Anforderung über ZV: Spiegel sind anzuklappen";
CM_ SG_ 388 ZV_Verdeck_auf "Anforderungssignal für ein Komfortöffnen des Verdecks. 
Signal wird angefordert wenn  SKontakt = 0 und eine Doppelbetätigung Schließzylinder_auf oder Funkfernbedienung_Taste_auf  innerhalb zwei Sekunden empfangen wird. Signal wird auch angefordert wenn S";
CM_ SG_ 388 ZV_Verdeck_zu "Anforderungssignal für ein Komfortschließen des Verdecks. 
Signal wird angefordert wenn  SKontakt = 0 und eine Doppelbetätigung Schließzylinder_Zu oder Funkfernbedienung_Taste_zu  innerhalb zwei Sekunden empfangen wird. Signal wird auch angefordert wenn ";
CM_ SG_ 388 ZV_zentral_entsafen "Zentral entsafen";
CM_ SG_ 388 ZV_zentral_safen "Zentral safen";
CM_ SG_ 388 ZV_zu_BT "ZV Schliessstelle";
CM_ SG_ 388 ZV_zu_FT "ZV Schliessstelle";
CM_ SG_ 388 ZV_zu_Funk "ZV Schliessstelle";
CM_ SG_ 388 ZV_zu_Kessy "ZV Schliessstelle";
CM_ SG_ 388 ZV_zu_Zeitl_Nachverr "ZV Schliessstelle";

CM_ SG_ 1411 BCM_FH_Freigabe "Funktionsfreigabe Fensterheber";
CM_ SG_ 1411 BCM_HSK_Freigabe "Handschuhkastenfreigabe";
CM_ SG_ 1411 BCM_Komfortfkt_Freigabe "globale Freigabe der Komfortfunktion";
CM_ SG_ 1411 BCM_Tankklappensteller_Fehler "Fehler: nicht Funktionalität des Tankklappenstellers";
CM_ SG_ 1411 BCM_Verdeck_Freigabe "Freigabe Verdeckbetrieb
";
CM_ SG_ 1411 DWA_aktiv "Status DWA  aktiv";
CM_ SG_ 1411 FBS_Warn_Schluessel_Batt "Kombi Prio Warnung Schluessel Batterie
'Bitte Schlüsselbatterie wechseln!'";
CM_ SG_ 1411 FFB_CarFinder "Car Finder Funktion (Blinken ohne zu entriegeln)";
CM_ SG_ 1411 FFB_Komfortoeffnen "Komfortoeffnen Funk
";
CM_ SG_ 1411 FFB_Komfortschliessen "Komfortschliessen Funk
";
CM_ SG_ 1411 HBFS_gesafet "HBFS Tuer gesafet.
Im Zustand Safe wird auch das Signal HBFS_verriegelt = 1 gesendet.";
CM_ SG_ 1411 HBFS_verriegelt "Verriegelungsstatus Tür";
CM_ SG_ 1411 HD_Hauptraste "SBL-Schloss (MQB/MLBevo): Drehfalle Heckdeckel
sonst (MQB): Hauptraste Heckdeckel";
CM_ SG_ 1411 HD_Vorraste "SBL_Schloss (MQB/MLBevo): Sperrklinke Heckdeckel
sonst (MQB): Vorraste Heckdeckel";
CM_ SG_ 1411 HFS_gesafet "HFS Tuer gesafet.
Im Zustand Safe wird auch das Signal HFS_verriegelt = 1 gesendet.";
CM_ SG_ 1411 HFS_verriegelt "HFS Tuer verriegelt";
CM_ SG_ 1411 IRUE_aktiv "Status Innenraumüberwachung
";
CM_ SG_ 1411 IRUE_Taster_Fkts_LED "Anforderung Funktions-LED IRUE-Taster (LED wird vom TSG angesteuert)
MQB: Bei Verbau eines einzelnen Taster zur Deaktivierung von IRUE und NGS wird dieses Signal zur Ansteuerung der Funktions-LED gesendet.";
CM_ SG_ 1411 ZV_BT_offen "gespiegeltes Bit BT_Tuer_geoeffnet TSG_BT_1 Botschaft";
CM_ SG_ 1411 ZV_Einzeltuerentriegelung "Einzeltürentriegelung ZV
";
CM_ SG_ 1411 ZV_FT_offen "gespiegeltes Bit FT_Tuer_geoeffnet TSG_FT_1 Botschaft";
CM_ SG_ 1411 ZV_gesafet_extern_ist "Istzustand: Fahrzeug aussen gesafet
";
CM_ SG_ 1411 ZV_gesafet_extern_soll "Sollzustand: Fahrzeug gesafet extern
";
CM_ SG_ 1411 ZV_HBFS_offen "gespiegeltes Bit HBFS_Tuer_geoeffnet TSG_HBFS_1 Botschaft";
CM_ SG_ 1411 ZV_HD_offen "Status Heckdeckel
";
CM_ SG_ 1411 ZV_Heckeinzelentriegelung "Heckdeckeleinzelentriegelung";
CM_ SG_ 1411 ZV_HFS_offen "gespiegeltes Bit HFS_Tuer_geoeffnet TSG_HFS_1 Botschaft";
CM_ SG_ 1411 ZV_HS_offen "Status Heckscheibe
";
CM_ SG_ 1411 ZV_ist_Zustand_verfuegbar "Verfügbarkeit IST-Zustand ZV

";
CM_ SG_ 1411 ZV_Oeffnungsmodus "Konfigurierter Oeffnungsmodus fuer ZV:
0 = globale Oeffnung (alle Tueren)
1 = ZV mit Einzeltuerentriegelung (FFB - nur Fahrertuer, Kessy - nur bediente Tuer)
2 = ZV individuell selektive Oeffnung (FFB - Fahrerseite, Kessy - bediente Tuer + Fahrertuer)";
CM_ SG_ 1411 ZV_Rollo_auf "Komfortöffnen des Dachrollos";
CM_ SG_ 1411 ZV_Rollo_zu "Komfortschließen des Dachrollos";
CM_ SG_ 1411 ZV_SAD_auf "Komfortöffnen des Schiebeausstelldaches";
CM_ SG_ 1411 ZV_SAD_zu "Komfortschließen des Schiebeausstelldaches";
CM_ SG_ 1411 ZV_SafeFunktion_aktiv "Statusübermittlung ob die Safe Funktion im Fzg. aktiv ist. Das Kombi benötigt das Signal, um den Text Safelock aktiv anzuzeigen. ";
CM_ SG_ 1411 ZV_Schluessel_Zugang "aktuelle Funkschlüsselnummer";
CM_ SG_ 1411 ZV_Tankklappe_offen "Öffnungsstatus der Tankklappe";
CM_ SG_ 1411 ZV_verriegelt_extern_ist "Istzustand: Verriegelung Fahrzeug aussen
";
CM_ SG_ 1411 ZV_verriegelt_extern_soll "Sollzustand: Verriegelung Fahrzeug aussen
";
CM_ SG_ 1411 ZV_verriegelt_intern_ist "Istzustand: Verriegelung Fahrzeug innen
";
CM_ SG_ 1411 ZV_verriegelt_intern_soll "Sollzustand: Verriegelung Fahrzeug innen
";
CM_ SG_ 1411 ZV_verriegelt_soll "Fahrzeug Gesamtverriegelungsstatus Sollzustand für Ladestecker- und Ladeklappenverriegelung. ";
BA_DEF_REL_ BU_SG_REL_  "GenSigTimeoutTime" INT 0 65535;
BA_DEF_ BO_  "DiagRequest" ENUM "No", "Yes";
BA_DEF_ BO_  "DiagResponse" ENUM "No", "Yes";
BA_DEF_ BO_  "DiagState" ENUM "No", "Yes";
BA_DEF_ BO_  "GenMsgChkConstant" HEX 0 4095;
BA_DEF_ BO_  "GenMsgCycleTime" INT 0 65535;
BA_DEF_ BO_  "GenMsgCycleTimeFast" INT 0 65535;
BA_DEF_ BO_  "GenMsgDelayTime" INT 0 100000;
BA_DEF_ BO_  "GenMsgILSupport" ENUM "No", "Yes";
BA_DEF_ BO_  "GenMsgNrOfRepetition" INT 0 100;
BA_DEF_ BO_  "GenMsgPDUConstants" STRING;
BA_DEF_ BO_  "GenMsgSendType" ENUM "Cyclic", "not_used", "not_used", "not_used", "not_used", "not_used", "not_used", "IfActive", "NoMsgSendType";
BA_DEF_ BO_  "GenMsgStartDelayTime" INT 0 100000;
BA_DEF_ BO_  "NmMessage" ENUM "No", "Yes";
BA_DEF_ BO_  "NmhMessage" ENUM "No", "Yes";
BA_DEF_ BO_  "MsgType" ENUM "Application", "NM ", "NMH", "TP2.0", "ISO-TP ", "BAP", "EID", "KS", "XCP_PRE_CONFIGURED", "XCP_RUNTIME_CONFIGURED";
BA_DEF_ BO_  "VAGTP20_API" HEX 0 255;
BA_DEF_ BO_  "VAGTP20_DynConnection" ENUM "No", "Yes";
BA_DEF_ BO_  "VAGTP20_DynSetup" ENUM "No", "Yes";
BA_DEF_ BO_  "VAGTP20_StatConnection" ENUM "No", "Yes";
BA_DEF_ SG_  "GenSigActiveRepetitions" INT -2147483648 2147483647;
BA_DEF_ SG_  "GenSigInactiveValue" INT -2147483648 2147483647;
BA_DEF_ SG_  "GenSigSendType" ENUM "Cyclic", "OnWrite", "OnWriteWithRepetition", "OnChange", "OnChangeWithRepetition", "IfActive", "IfActiveWithRepetition", "NoSigSendType", "OnChangeAndIfActive", "OnChangeAndIfActiveWithRepetition";
BA_DEF_ SG_  "GenSigStartValue" INT -2147483648 2147483647;
BA_DEF_ SG_  "NWM-WakeupAllowed" ENUM "No", "Yes";
BA_DEF_ SG_  "GenSigFuncType" ENUM "NoFunction", "MsgCounter", "CRC-8", "XOR", "XOR-2", "DatedBit", "SW-Kl15", "CHK", "Constant", "Protocol", "CRC-8-SAE_J1850", "CRC-32", "DataLength", "DataID", "MsgCounter16", "SOK-Signatur", "Cluster";
BA_DEF_ SG_  "GenSigSwitchedByIgnition" ENUM "No", "Yes";
BA_DEF_ SG_  "Fehlerwert" HEX 0 2147483647;
BA_DEF_ SG_  "GenSigMissingSourceValue" HEX 0 2147483647;
BA_DEF_DEF_REL_  "GenSigTimeoutTime" 0;
BA_DEF_DEF_  "DiagRequest" "No";
BA_DEF_DEF_  "DiagResponse" "No";
BA_DEF_DEF_  "DiagState" "No";
BA_DEF_DEF_  "GenMsgChkConstant" 0;
BA_DEF_DEF_  "GenMsgCycleTime" 0;
BA_DEF_DEF_  "GenMsgCycleTimeFast" 0;
BA_DEF_DEF_  "GenMsgDelayTime" 0;
BA_DEF_DEF_  "GenMsgILSupport" "No";
BA_DEF_DEF_  "GenMsgNrOfRepetition" 0;
BA_DEF_DEF_  "GenMsgPDUConstants" "";
BA_DEF_DEF_  "GenMsgSendType" "NoMsgSendType";
BA_DEF_DEF_  "GenMsgStartDelayTime" 0;
BA_DEF_DEF_  "NmMessage" "No";
BA_DEF_DEF_  "NmhMessage" "No";
BA_DEF_DEF_  "MsgType" "Application";
BA_DEF_DEF_  "VAGTP20_API" 0;
BA_DEF_DEF_  "VAGTP20_DynConnection" "No";
BA_DEF_DEF_  "VAGTP20_DynSetup" "No";
BA_DEF_DEF_  "VAGTP20_StatConnection" "No";
BA_DEF_DEF_  "GenSigActiveRepetitions" 0;
BA_DEF_DEF_  "GenSigInactiveValue" 0;
BA_DEF_DEF_  "GenSigSendType" "NoSigSendType";
BA_DEF_DEF_  "GenSigStartValue" 0;
BA_DEF_DEF_  "NWM-WakeupAllowed" "No";
BA_DEF_DEF_  "GenSigFuncType" "NoFunction";
BA_DEF_DEF_  "GenSigSwitchedByIgnition" "Yes";
BA_DEF_DEF_  "Fehlerwert" 0;
BA_DEF_DEF_  "GenSigMissingSourceValue" 0;
BA_ "GenMsgCycleTime" BO_ 976 100;
BA_ "GenMsgDelayTime" BO_ 976 20;
BA_ "GenMsgILSupport" BO_ 976 1;
BA_ "GenMsgSendType" BO_ 976 0;
BA_ "GenMsgCycleTime" BO_ 1449 1000;
BA_ "GenMsgDelayTime" BO_ 1449 100;
BA_ "GenMsgILSupport" BO_ 1449 1;
BA_ "GenMsgSendType" BO_ 1449 0;
BA_ "GenMsgCycleTime" BO_ 975 100;
BA_ "GenMsgDelayTime" BO_ 975 20;
BA_ "GenMsgILSupport" BO_ 975 1;
BA_ "GenMsgSendType" BO_ 975 0;
BA_ "GenMsgCycleTime" BO_ 1457 1000;
BA_ "GenMsgDelayTime" BO_ 1457 100;
BA_ "GenMsgILSupport" BO_ 1457 1;
BA_ "GenMsgSendType" BO_ 1457 0;
BA_ "GenMsgCycleTime" BO_ 974 100;
BA_ "GenMsgDelayTime" BO_ 974 20;
BA_ "GenMsgILSupport" BO_ 974 1;
BA_ "GenMsgSendType" BO_ 974 0;
BA_ "GenMsgCycleTime" BO_ 1458 1000;
BA_ "GenMsgDelayTime" BO_ 1458 100;
BA_ "GenMsgILSupport" BO_ 1458 1;
BA_ "GenMsgSendType" BO_ 1458 0;
BA_ "GenMsgCycleTime" BO_ 346 100;
BA_ "GenMsgDelayTime" BO_ 346 20;
BA_ "GenMsgILSupport" BO_ 346 1;
BA_ "GenMsgPDUConstants" BO_ 346 "0xcf,0x1a,0x84,0x28,0x05,0xcb,0xb3,0x98,0x82,0x53,0xbe,0xa1,0x4a,0x6d,0x41,0xae";
BA_ "GenMsgSendType" BO_ 346 0;
BA_ "GenMsgCycleTime" BO_ 2589283609 500;
BA_ "GenMsgDelayTime" BO_ 2589283609 80;
BA_ "GenMsgILSupport" BO_ 2589283609 1;
BA_ "GenMsgSendType" BO_ 2589283609 0;
BA_ "GenMsgCycleTime" BO_ 1718 1000;
BA_ "GenMsgILSupport" BO_ 1718 1;
BA_ "GenMsgSendType" BO_ 1718 0;
BA_ "GenMsgCycleTime" BO_ 2463978633 100;
BA_ "GenMsgDelayTime" BO_ 2463978633 50;
BA_ "GenMsgILSupport" BO_ 2463978633 1;
BA_ "GenMsgPDUConstants" BO_ 2463978633 "0x81,0xad,0x54,0x1d,0x28,0xac,0x6c,0x8e,0xd4,0x6e,0xeb,0x58,0x4a,0x71,0x5a,0x3b";
BA_ "GenMsgSendType" BO_ 2463978633 0;
BA_ "GenMsgCycleTime" BO_ 2463978636 1000;
BA_ "GenMsgDelayTime" BO_ 2463978636 10;
BA_ "GenMsgILSupport" BO_ 2463978636 1;
BA_ "GenMsgSendType" BO_ 2463978636 0;
BA_ "GenMsgCycleTime" BO_ 2463978634 100;
BA_ "GenMsgDelayTime" BO_ 2463978634 50;
BA_ "GenMsgILSupport" BO_ 2463978634 1;
BA_ "GenMsgPDUConstants" BO_ 2463978634 "0x10,0xec,0x76,0x31,0x11,0x02,0x55,0xbe,0xa8,0xba,0x68,0x51,0x40,0x7a,0x23,0x13";
BA_ "GenMsgSendType" BO_ 2463978634 0;
BA_ "GenMsgCycleTime" BO_ 2463978637 1000;
BA_ "GenMsgDelayTime" BO_ 2463978637 10;
BA_ "GenMsgILSupport" BO_ 2463978637 1;
BA_ "GenMsgSendType" BO_ 2463978637 0;
BA_ "GenMsgCycleTime" BO_ 995 100;
BA_ "GenMsgCycleTimeFast" BO_ 995 50;
BA_ "GenMsgDelayTime" BO_ 995 50;
BA_ "GenMsgILSupport" BO_ 995 1;
BA_ "GenMsgNrOfRepetition" BO_ 995 5;
BA_ "GenMsgPDUConstants" BO_ 995 "0xad,0x1d,0xac,0x8e,0x6e,0x58,0x71,0x3b,0xce,0xc6,0x27,0x4f,0x06,0xca,0x65,0x84";
BA_ "GenMsgSendType" BO_ 995 0;
BA_ "GenMsgCycleTime" BO_ 1716 200;
BA_ "GenMsgILSupport" BO_ 1716 1;
BA_ "GenMsgSendType" BO_ 1716 0;
BA_ "GenMsgCycleTime" BO_ 1361 200;
BA_ "GenMsgDelayTime" BO_ 1361 50;
BA_ "GenMsgILSupport" BO_ 1361 1;
BA_ "GenMsgSendType" BO_ 1361 0;
BA_ "GenMsgCycleTime" BO_ 1702 500;
BA_ "GenMsgCycleTimeFast" BO_ 1702 100;
BA_ "GenMsgDelayTime" BO_ 1702 50;
BA_ "GenMsgILSupport" BO_ 1702 1;
BA_ "GenMsgNrOfRepetition" BO_ 1702 3;
BA_ "GenMsgSendType" BO_ 1702 0;
BA_ "MsgType" BO_ 2617013760 8;
BA_ "MsgType" BO_ 2617013761 9;
BA_ "MsgType" BO_ 2617124608 6;
BA_ "MsgType" BO_ 2617124609 6;
BA_ "MsgType" BO_ 2617126656 6;
BA_ "MsgType" BO_ 2617126657 6;
BA_ "GenMsgCycleTime" BO_ 2463978613 320;
BA_ "GenMsgCycleTimeFast" BO_ 2463978613 80;
BA_ "GenMsgDelayTime" BO_ 2463978613 20;
BA_ "GenMsgILSupport" BO_ 2463978613 1;
BA_ "GenMsgPDUConstants" BO_ 2463978613 "0x91,0x3a,0x38,0x23,0x8e,0x5b,0xa6,0x6f,0xdf,0x3b,0xc2,0x12,0x0e,0x4b,0x4f,0xb5";
BA_ "GenMsgSendType" BO_ 2463978613 0;
BA_ "GenMsgCycleTime" BO_ 388 1000;
BA_ "GenMsgCycleTimeFast" BO_ 388 20;
BA_ "GenMsgILSupport" BO_ 388 1;
BA_ "GenMsgNrOfRepetition" BO_ 388 11;
BA_ "GenMsgPDUConstants" BO_ 388 "0xe3,0xe8,0xc4,0x7f,0xf1,0x95,0xd8,0xb0,0xc7,0xa3,0xf4,0x6c,0xe7,0xc3,0x5a,0xf7";
BA_ "GenMsgSendType" BO_ 388 0;
BA_ "GenMsgCycleTime" BO_ 1411 200;
BA_ "GenMsgCycleTimeFast" BO_ 1411 50;
BA_ "GenMsgDelayTime" BO_ 1411 50;
BA_ "GenMsgILSupport" BO_ 1411 1;
BA_ "GenMsgNrOfRepetition" BO_ 1411 5;
BA_ "GenMsgSendType" BO_ 1411 0;
BA_ "GenSigSendType" SG_ 976 ASW_HMI_defekt 0;
BA_ "GenSigSwitchedByIgnition" SG_ 976 ASW_HMI_defekt 0;
BA_ "GenSigSendType" SG_ 976 ASW_wakeup 3;
BA_ "GenSigSwitchedByIgnition" SG_ 976 ASW_wakeup 0;
BA_ "GenSigSendType" SG_ 976 ASW_Warnung_aktiv_FS 3;
BA_ "GenSigSwitchedByIgnition" SG_ 976 ASW_Warnung_aktiv_FS 0;
BA_ "GenSigSendType" SG_ 976 FS_Status_eTAG 3;
BA_ "GenSigSwitchedByIgnition" SG_ 976 FS_Status_eTAG 0;
BA_ "Fehlerwert" SG_ 976 FS_Status_eTAG 3;
BA_ "GenSigSendType" SG_ 976 FT_BFS_Fond_Freigabe 3;
BA_ "GenSigSwitchedByIgnition" SG_ 976 FT_BFS_Fond_Freigabe 0;
BA_ "GenSigSendType" SG_ 976 FT_Daemmglas 3;
BA_ "GenSigSwitchedByIgnition" SG_ 976 FT_Daemmglas 0;
BA_ "GenSigSendType" SG_ 976 FT_FH_Bew_hoch 3;
BA_ "GenSigSwitchedByIgnition" SG_ 976 FT_FH_Bew_hoch 0;
BA_ "GenSigSendType" SG_ 976 FT_FH_Bew_tief 3;
BA_ "GenSigSwitchedByIgnition" SG_ 976 FT_FH_Bew_tief 0;
BA_ "GenSigSendType" SG_ 976 FT_FH_Block 3;
BA_ "GenSigSwitchedByIgnition" SG_ 976 FT_FH_Block 0;
BA_ "GenSigSendType" SG_ 976 FT_FH_Fang 3;
BA_ "GenSigSwitchedByIgnition" SG_ 976 FT_FH_Fang 0;
BA_ "GenSigSendType" SG_ 976 FT_FH_normiert 3;
BA_ "GenSigSwitchedByIgnition" SG_ 976 FT_FH_normiert 0;
BA_ "GenSigSendType" SG_ 976 FT_FH_Oeffnung 3;
BA_ "GenSigSwitchedByIgnition" SG_ 976 FT_FH_Oeffnung 0;
BA_ "GenSigSendType" SG_ 976 FT_FH_Pos_oben 3;
BA_ "GenSigSwitchedByIgnition" SG_ 976 FT_FH_Pos_oben 0;
BA_ "GenSigSendType" SG_ 976 FT_FH_S_AutoHoch 3;
BA_ "GenSigSwitchedByIgnition" SG_ 976 FT_FH_S_AutoHoch 0;
BA_ "GenSigSendType" SG_ 976 FT_FH_S_AutoTief 3;
BA_ "GenSigSwitchedByIgnition" SG_ 976 FT_FH_S_AutoTief 0;
BA_ "GenSigSendType" SG_ 976 FT_FH_S_ManHoch 3;
BA_ "GenSigSwitchedByIgnition" SG_ 976 FT_FH_S_ManHoch 0;
BA_ "GenSigSendType" SG_ 976 FT_FH_S_ManTief 3;
BA_ "GenSigSwitchedByIgnition" SG_ 976 FT_FH_S_ManTief 0;
BA_ "GenSigSendType" SG_ 976 FT_FH_Thermo 3;
BA_ "GenSigSwitchedByIgnition" SG_ 976 FT_FH_Thermo 0;
BA_ "GenSigSendType" SG_ 976 FT_gesafet 3;
BA_ "GenSigSwitchedByIgnition" SG_ 976 FT_gesafet 0;
BA_ "GenSigSendType" SG_ 976 FT_HD_Taste 3;
BA_ "GenSigSwitchedByIgnition" SG_ 976 FT_HD_Taste 0;
BA_ "GenSigSendType" SG_ 976 FT_HD_Taste_2 3;
BA_ "GenSigSwitchedByIgnition" SG_ 976 FT_HD_Taste_2 0;
BA_ "GenSigSendType" SG_ 976 FT_IRUE_Taste 3;
BA_ "GenSigSwitchedByIgnition" SG_ 976 FT_IRUE_Taste 0;
BA_ "GenSigSendType" SG_ 976 FT_Kisi_Fehler 3;
BA_ "GenSigSwitchedByIgnition" SG_ 976 FT_Kisi_Fehler 0;
BA_ "Fehlerwert" SG_ 976 FT_Kisi_Fehler 1;
BA_ "GenSigSendType" SG_ 976 FT_Kisi_li_aktiv 3;
BA_ "GenSigSwitchedByIgnition" SG_ 976 FT_Kisi_li_aktiv 0;
BA_ "GenSigSendType" SG_ 976 FT_Kisi_re_aktiv 3;
BA_ "GenSigSwitchedByIgnition" SG_ 976 FT_Kisi_re_aktiv 0;
BA_ "GenSigSendType" SG_ 976 FT_Kisi_Taster_li 3;
BA_ "GenSigSwitchedByIgnition" SG_ 976 FT_Kisi_Taster_li 0;
BA_ "GenSigSendType" SG_ 976 FT_Kisi_Taster_re 3;
BA_ "GenSigSwitchedByIgnition" SG_ 976 FT_Kisi_Taster_re 0;
BA_ "GenSigSendType" SG_ 976 FT_Lock_Taster 3;
BA_ "GenSigSwitchedByIgnition" SG_ 976 FT_Lock_Taster 0;
BA_ "GenSigSendType" SG_ 976 FT_Oben_Block_erw 3;
BA_ "GenSigSwitchedByIgnition" SG_ 976 FT_Oben_Block_erw 0;
BA_ "GenSigSendType" SG_ 976 FT_Schliesstaster 3;
BA_ "GenSigSwitchedByIgnition" SG_ 976 FT_Schliesstaster 0;
BA_ "GenSigSendType" SG_ 976 FT_Schluesselschalter_auf 3;
BA_ "GenSigSwitchedByIgnition" SG_ 976 FT_Schluesselschalter_auf 0;
BA_ "GenSigSendType" SG_ 976 FT_Schluesselschalter_zu 3;
BA_ "GenSigSwitchedByIgnition" SG_ 976 FT_Schluesselschalter_zu 0;
BA_ "GenSigSendType" SG_ 976 FT_SP_ausgerastet 3;
BA_ "GenSigSwitchedByIgnition" SG_ 976 FT_SP_ausgerastet 0;
BA_ "GenSigSendType" SG_ 976 FT_Sp_Blk_def 3;
BA_ "GenSigSwitchedByIgnition" SG_ 976 FT_Sp_Blk_def 0;
BA_ "GenSigSendType" SG_ 976 FT_Sp_Heizung_Anf 0;
BA_ "GenSigSwitchedByIgnition" SG_ 976 FT_Sp_Heizung_Anf 0;
BA_ "GenSigSendType" SG_ 976 FT_SP_Heizung_Status 3;
BA_ "GenSigSwitchedByIgnition" SG_ 976 FT_SP_Heizung_Status 0;
BA_ "GenSigSendType" SG_ 976 FT_SP_ht_aktiv 3;
BA_ "GenSigSwitchedByIgnition" SG_ 976 FT_SP_ht_aktiv 0;
BA_ "GenSigSendType" SG_ 976 FT_SP_lr_aktiv 3;
BA_ "GenSigSwitchedByIgnition" SG_ 976 FT_SP_lr_aktiv 0;
BA_ "GenSigSendType" SG_ 976 FT_Sperrklinke 3;
BA_ "GenSigSwitchedByIgnition" SG_ 976 FT_Sperrklinke 0;
BA_ "GenSigSendType" SG_ 976 FT_SWA_Taster 3;
BA_ "GenSigSwitchedByIgnition" SG_ 976 FT_SWA_Taster 0;
BA_ "GenSigSendType" SG_ 976 FT_TAG_betaetigt 3;
BA_ "GenSigSwitchedByIgnition" SG_ 976 FT_TAG_betaetigt 0;
BA_ "GenSigSendType" SG_ 976 FT_TD_Taste 3;
BA_ "GenSigSwitchedByIgnition" SG_ 976 FT_TD_Taste 0;
BA_ "GenSigSendType" SG_ 976 FT_TD_Taste_Fehler 0;
BA_ "GenSigSwitchedByIgnition" SG_ 976 FT_TD_Taste_Fehler 0;
BA_ "GenSigSendType" SG_ 976 FT_TIG_betaetigt 3;
BA_ "GenSigSwitchedByIgnition" SG_ 976 FT_TIG_betaetigt 0;
BA_ "GenSigSendType" SG_ 976 FT_TSG_hinten_verbaut 3;
BA_ "GenSigSwitchedByIgnition" SG_ 976 FT_TSG_hinten_verbaut 0;
BA_ "GenSigSendType" SG_ 976 FT_Tuer_geoeffnet 3;
BA_ "GenSigSwitchedByIgnition" SG_ 976 FT_Tuer_geoeffnet 0;
BA_ "GenSigSendType" SG_ 976 FT_Tuerschloss_defekt 0;
BA_ "GenSigSwitchedByIgnition" SG_ 976 FT_Tuerschloss_defekt 0;
BA_ "GenSigSendType" SG_ 976 FT_UEKB_aktiviert 3;
BA_ "GenSigSwitchedByIgnition" SG_ 976 FT_UEKB_aktiviert 0;
BA_ "GenSigSendType" SG_ 976 FT_Unlock_Taster 3;
BA_ "GenSigSwitchedByIgnition" SG_ 976 FT_Unlock_Taster 0;
BA_ "GenSigSendType" SG_ 976 FT_Unten_Block_erw 3;
BA_ "GenSigSwitchedByIgnition" SG_ 976 FT_Unten_Block_erw 0;
BA_ "GenSigSendType" SG_ 976 FT_verriegelt 3;
BA_ "GenSigSwitchedByIgnition" SG_ 976 FT_verriegelt 0;
BA_ "GenSigSendType" SG_ 976 FT_Zuziehhilfe_aktiv 3;
BA_ "GenSigSwitchedByIgnition" SG_ 976 FT_Zuziehhilfe_aktiv 0;
BA_ "GenSigSendType" SG_ 976 SSR_Temp_Freigabe 0;
BA_ "GenSigSwitchedByIgnition" SG_ 976 SSR_Temp_Freigabe 0;
BA_ "GenSigSendType" SG_ 976 SWA_HMI_Diagnose 0;
BA_ "GenSigSwitchedByIgnition" SG_ 976 SWA_HMI_Diagnose 0;
BA_ "GenSigSendType" SG_ 1449 TSG_FlHz_FS_FnAbbruchHzKreis_A 3;
BA_ "GenSigSwitchedByIgnition" SG_ 1449 TSG_FlHz_FS_FnAbbruchHzKreis_A 0;
BA_ "GenSigSendType" SG_ 1449 TSG_FlHz_FS_FnAbbruchHzKreis_B 3;
BA_ "GenSigSwitchedByIgnition" SG_ 1449 TSG_FlHz_FS_FnAbbruchHzKreis_B 0;
BA_ "GenSigSendType" SG_ 1449 TSG_FlHz_FS_NTC_A 3;
BA_ "GenSigStartValue" SG_ 1449 TSG_FlHz_FS_NTC_A 127;
BA_ "GenSigSwitchedByIgnition" SG_ 1449 TSG_FlHz_FS_NTC_A 0;
BA_ "GenSigSendType" SG_ 1449 TSG_FlHz_FS_NTC_B 3;
BA_ "GenSigStartValue" SG_ 1449 TSG_FlHz_FS_NTC_B 127;
BA_ "GenSigSwitchedByIgnition" SG_ 1449 TSG_FlHz_FS_NTC_B 0;
BA_ "GenSigSendType" SG_ 975 ASW_Warnung_aktiv_HBFS 3;
BA_ "GenSigSwitchedByIgnition" SG_ 975 ASW_Warnung_aktiv_HBFS 0;
BA_ "GenSigSendType" SG_ 975 HBFS_FH_Bew_hoch 3;
BA_ "GenSigSwitchedByIgnition" SG_ 975 HBFS_FH_Bew_hoch 0;
BA_ "GenSigSendType" SG_ 975 HBFS_FH_Bew_tief 3;
BA_ "GenSigSwitchedByIgnition" SG_ 975 HBFS_FH_Bew_tief 0;
BA_ "GenSigSendType" SG_ 975 HBFS_FH_Block 3;
BA_ "GenSigSwitchedByIgnition" SG_ 975 HBFS_FH_Block 0;
BA_ "GenSigSendType" SG_ 975 HBFS_FH_Fang 3;
BA_ "GenSigSwitchedByIgnition" SG_ 975 HBFS_FH_Fang 0;
BA_ "GenSigSendType" SG_ 975 HBFS_FH_normiert 3;
BA_ "GenSigSwitchedByIgnition" SG_ 975 HBFS_FH_normiert 0;
BA_ "GenSigSendType" SG_ 975 HBFS_FH_Oeffnung 3;
BA_ "GenSigSwitchedByIgnition" SG_ 975 HBFS_FH_Oeffnung 0;
BA_ "GenSigSendType" SG_ 975 HBFS_FH_S_AutoHoch 3;
BA_ "GenSigSwitchedByIgnition" SG_ 975 HBFS_FH_S_AutoHoch 0;
BA_ "GenSigSendType" SG_ 975 HBFS_FH_S_AutoTief 3;
BA_ "GenSigSwitchedByIgnition" SG_ 975 HBFS_FH_S_AutoTief 0;
BA_ "GenSigSendType" SG_ 975 HBFS_FH_S_HFS_AutoHoch 3;
BA_ "GenSigSwitchedByIgnition" SG_ 975 HBFS_FH_S_HFS_AutoHoch 0;
BA_ "GenSigSendType" SG_ 975 HBFS_FH_S_HFS_AutoTief 3;
BA_ "GenSigSwitchedByIgnition" SG_ 975 HBFS_FH_S_HFS_AutoTief 0;
BA_ "GenSigSendType" SG_ 975 HBFS_FH_S_HFS_ManHoch 3;
BA_ "GenSigSwitchedByIgnition" SG_ 975 HBFS_FH_S_HFS_ManHoch 0;
BA_ "GenSigSendType" SG_ 975 HBFS_FH_S_HFS_ManTief 3;
BA_ "GenSigSwitchedByIgnition" SG_ 975 HBFS_FH_S_HFS_ManTief 0;
BA_ "GenSigSendType" SG_ 975 HBFS_FH_S_ManHoch 3;
BA_ "GenSigSwitchedByIgnition" SG_ 975 HBFS_FH_S_ManHoch 0;
BA_ "GenSigSendType" SG_ 975 HBFS_FH_S_ManTief 3;
BA_ "GenSigSwitchedByIgnition" SG_ 975 HBFS_FH_S_ManTief 0;
BA_ "GenSigSendType" SG_ 975 HBFS_FH_Thermo 3;
BA_ "GenSigSwitchedByIgnition" SG_ 975 HBFS_FH_Thermo 0;
BA_ "GenSigSendType" SG_ 975 HBFS_gesafet 3;
BA_ "GenSigSwitchedByIgnition" SG_ 975 HBFS_gesafet 0;
BA_ "GenSigSendType" SG_ 975 HBFS_Heckrollotaster_betaetigt 3;
BA_ "GenSigSwitchedByIgnition" SG_ 975 HBFS_Heckrollotaster_betaetigt 0;
BA_ "GenSigSendType" SG_ 975 HBFS_Lock_Taster 3;
BA_ "GenSigSwitchedByIgnition" SG_ 975 HBFS_Lock_Taster 0;
BA_ "GenSigSendType" SG_ 975 HBFS_Lock_Taster_inv 3;
BA_ "GenSigSwitchedByIgnition" SG_ 975 HBFS_Lock_Taster_inv 0;
BA_ "GenSigSendType" SG_ 975 HBFS_MRollo_Schalter 3;
BA_ "GenSigStartValue" SG_ 975 HBFS_MRollo_Schalter 6;
BA_ "GenSigSwitchedByIgnition" SG_ 975 HBFS_MRollo_Schalter 0;
BA_ "Fehlerwert" SG_ 975 HBFS_MRollo_Schalter 7;
BA_ "GenSigSendType" SG_ 975 HBFS_Oben_Block_erw 3;
BA_ "GenSigSwitchedByIgnition" SG_ 975 HBFS_Oben_Block_erw 0;
BA_ "GenSigSendType" SG_ 975 HBFS_SAD_Schalter 3;
BA_ "GenSigStartValue" SG_ 975 HBFS_SAD_Schalter 14;
BA_ "GenSigSwitchedByIgnition" SG_ 975 HBFS_SAD_Schalter 0;
BA_ "Fehlerwert" SG_ 975 HBFS_SAD_Schalter 15;
BA_ "GenSigSendType" SG_ 975 HBFS_Seitenrollo_hoch 3;
BA_ "GenSigSwitchedByIgnition" SG_ 975 HBFS_Seitenrollo_hoch 0;
BA_ "GenSigSendType" SG_ 975 HBFS_Seitenrollo_tief 3;
BA_ "GenSigSwitchedByIgnition" SG_ 975 HBFS_Seitenrollo_tief 0;
BA_ "GenSigSendType" SG_ 975 HBFS_Sperrklinke 3;
BA_ "GenSigSwitchedByIgnition" SG_ 975 HBFS_Sperrklinke 0;
BA_ "GenSigSendType" SG_ 975 HBFS_Status_eTAG 0;
BA_ "GenSigSwitchedByIgnition" SG_ 975 HBFS_Status_eTAG 0;
BA_ "Fehlerwert" SG_ 975 HBFS_Status_eTAG 3;
BA_ "GenSigSendType" SG_ 975 HBFS_Status_KiSi 3;
BA_ "GenSigSwitchedByIgnition" SG_ 975 HBFS_Status_KiSi 0;
BA_ "GenSigSendType" SG_ 975 HBFS_Status_KiSi_inv 0;
BA_ "GenSigStartValue" SG_ 975 HBFS_Status_KiSi_inv 1;
BA_ "GenSigSwitchedByIgnition" SG_ 975 HBFS_Status_KiSi_inv 0;
BA_ "GenSigSendType" SG_ 975 HBFS_TAG_betaetigt 3;
BA_ "GenSigSwitchedByIgnition" SG_ 975 HBFS_TAG_betaetigt 0;
BA_ "GenSigSendType" SG_ 975 HBFS_TIG_betaetigt 3;
BA_ "GenSigSwitchedByIgnition" SG_ 975 HBFS_TIG_betaetigt 0;
BA_ "GenSigSendType" SG_ 975 HBFS_TIG_betaetigt_schliessen 3;
BA_ "GenSigSwitchedByIgnition" SG_ 975 HBFS_TIG_betaetigt_schliessen 0;
BA_ "GenSigSendType" SG_ 975 HBFS_Tuer_geoeffnet 3;
BA_ "GenSigSwitchedByIgnition" SG_ 975 HBFS_Tuer_geoeffnet 0;
BA_ "GenSigSendType" SG_ 975 HBFS_Tuer_Status 3;
BA_ "GenSigSwitchedByIgnition" SG_ 975 HBFS_Tuer_Status 0;
BA_ "Fehlerwert" SG_ 975 HBFS_Tuer_Status 3;
BA_ "GenSigSendType" SG_ 975 HBFS_Tuer_Status_QBit 0;
BA_ "GenSigSwitchedByIgnition" SG_ 975 HBFS_Tuer_Status_QBit 0;
BA_ "GenSigSendType" SG_ 975 HBFS_Tueroeffnen_Warnung 3;
BA_ "GenSigSwitchedByIgnition" SG_ 975 HBFS_Tueroeffnen_Warnung 0;
BA_ "GenSigSendType" SG_ 975 HBFS_Tuerschloss_defekt 0;
BA_ "GenSigSwitchedByIgnition" SG_ 975 HBFS_Tuerschloss_defekt 0;
BA_ "GenSigSendType" SG_ 975 HBFS_UEKB_aktiviert 3;
BA_ "GenSigSwitchedByIgnition" SG_ 975 HBFS_UEKB_aktiviert 0;
BA_ "GenSigSendType" SG_ 975 HBFS_Unlock_Taster 3;
BA_ "GenSigSwitchedByIgnition" SG_ 975 HBFS_Unlock_Taster 0;
BA_ "GenSigSendType" SG_ 975 HBFS_Unten_Block_erw 3;
BA_ "GenSigSwitchedByIgnition" SG_ 975 HBFS_Unten_Block_erw 0;
BA_ "GenSigSendType" SG_ 975 HBFS_verriegelt 3;
BA_ "GenSigSwitchedByIgnition" SG_ 975 HBFS_verriegelt 0;
BA_ "GenSigSendType" SG_ 975 HBFS_Zuziehhilfe_aktiv 3;
BA_ "GenSigSwitchedByIgnition" SG_ 975 HBFS_Zuziehhilfe_aktiv 0;
BA_ "GenSigSendType" SG_ 975 MTHBFS_M_Taste 3;
BA_ "GenSigSwitchedByIgnition" SG_ 975 MTHBFS_M_Taste 0;
BA_ "GenSigSendType" SG_ 975 MTHBFS_Pos1 3;
BA_ "GenSigSwitchedByIgnition" SG_ 975 MTHBFS_Pos1 0;
BA_ "GenSigSendType" SG_ 975 MTHBFS_Pos2 3;
BA_ "GenSigSwitchedByIgnition" SG_ 975 MTHBFS_Pos2 0;
BA_ "GenSigSendType" SG_ 975 MTHBFS_Pos3 3;
BA_ "GenSigSwitchedByIgnition" SG_ 975 MTHBFS_Pos3 0;
BA_ "GenSigSendType" SG_ 975 SSR_HBFS_Pos_Unten 0;
BA_ "GenSigSwitchedByIgnition" SG_ 975 SSR_HBFS_Pos_Unten 0;
BA_ "GenSigSendType" SG_ 1457 TSG_FlHz_HBFS_FnAbbruchHzKreis_A 3;
BA_ "GenSigSwitchedByIgnition" SG_ 1457 TSG_FlHz_HBFS_FnAbbruchHzKreis_A 0;
BA_ "GenSigSendType" SG_ 1457 TSG_FlHz_HBFS_FnAbbruchHzKreis_B 3;
BA_ "GenSigSwitchedByIgnition" SG_ 1457 TSG_FlHz_HBFS_FnAbbruchHzKreis_B 0;
BA_ "GenSigSendType" SG_ 1457 TSG_FlHz_HBFS_NTC_A 3;
BA_ "GenSigStartValue" SG_ 1457 TSG_FlHz_HBFS_NTC_A 127;
BA_ "GenSigSwitchedByIgnition" SG_ 1457 TSG_FlHz_HBFS_NTC_A 0;
BA_ "GenSigSendType" SG_ 1457 TSG_FlHz_HBFS_NTC_B 3;
BA_ "GenSigStartValue" SG_ 1457 TSG_FlHz_HBFS_NTC_B 127;
BA_ "GenSigSwitchedByIgnition" SG_ 1457 TSG_FlHz_HBFS_NTC_B 0;
BA_ "GenSigSendType" SG_ 974 ASW_Warnung_aktiv_HFS 3;
BA_ "GenSigSwitchedByIgnition" SG_ 974 ASW_Warnung_aktiv_HFS 0;
BA_ "GenSigSendType" SG_ 974 HFS_FH_Bew_hoch 3;
BA_ "GenSigSwitchedByIgnition" SG_ 974 HFS_FH_Bew_hoch 0;
BA_ "GenSigSendType" SG_ 974 HFS_FH_Bew_tief 3;
BA_ "GenSigSwitchedByIgnition" SG_ 974 HFS_FH_Bew_tief 0;
BA_ "GenSigSendType" SG_ 974 HFS_FH_Block 3;
BA_ "GenSigSwitchedByIgnition" SG_ 974 HFS_FH_Block 0;
BA_ "GenSigSendType" SG_ 974 HFS_FH_Fang 3;
BA_ "GenSigSwitchedByIgnition" SG_ 974 HFS_FH_Fang 0;
BA_ "GenSigSendType" SG_ 974 HFS_FH_normiert 3;
BA_ "GenSigSwitchedByIgnition" SG_ 974 HFS_FH_normiert 0;
BA_ "GenSigSendType" SG_ 974 HFS_FH_Oeffnung 3;
BA_ "GenSigSwitchedByIgnition" SG_ 974 HFS_FH_Oeffnung 0;
BA_ "GenSigSendType" SG_ 974 HFS_FH_S_AutoHoch 3;
BA_ "GenSigSwitchedByIgnition" SG_ 974 HFS_FH_S_AutoHoch 0;
BA_ "GenSigSendType" SG_ 974 HFS_FH_S_AutoTief 3;
BA_ "GenSigSwitchedByIgnition" SG_ 974 HFS_FH_S_AutoTief 0;
BA_ "GenSigSendType" SG_ 974 HFS_FH_S_HBFS_AutoHoch 3;
BA_ "GenSigSwitchedByIgnition" SG_ 974 HFS_FH_S_HBFS_AutoHoch 0;
BA_ "GenSigSendType" SG_ 974 HFS_FH_S_HBFS_AutoTief 3;
BA_ "GenSigSwitchedByIgnition" SG_ 974 HFS_FH_S_HBFS_AutoTief 0;
BA_ "GenSigSendType" SG_ 974 HFS_FH_S_HBFS_ManHoch 3;
BA_ "GenSigSwitchedByIgnition" SG_ 974 HFS_FH_S_HBFS_ManHoch 0;
BA_ "GenSigSendType" SG_ 974 HFS_FH_S_HBFS_ManTief 3;
BA_ "GenSigSwitchedByIgnition" SG_ 974 HFS_FH_S_HBFS_ManTief 0;
BA_ "GenSigSendType" SG_ 974 HFS_FH_S_ManHoch 3;
BA_ "GenSigSwitchedByIgnition" SG_ 974 HFS_FH_S_ManHoch 0;
BA_ "GenSigSendType" SG_ 974 HFS_FH_S_ManTief 3;
BA_ "GenSigSwitchedByIgnition" SG_ 974 HFS_FH_S_ManTief 0;
BA_ "GenSigSendType" SG_ 974 HFS_FH_Thermo 3;
BA_ "GenSigSwitchedByIgnition" SG_ 974 HFS_FH_Thermo 0;
BA_ "GenSigSendType" SG_ 974 HFS_gesafet 3;
BA_ "GenSigSwitchedByIgnition" SG_ 974 HFS_gesafet 0;
BA_ "GenSigSendType" SG_ 974 HFS_Heckrollotaster_betaetigt 3;
BA_ "GenSigSwitchedByIgnition" SG_ 974 HFS_Heckrollotaster_betaetigt 0;
BA_ "GenSigSendType" SG_ 974 HFS_Lock_Taster 3;
BA_ "GenSigSwitchedByIgnition" SG_ 974 HFS_Lock_Taster 0;
BA_ "GenSigSendType" SG_ 974 HFS_Lock_Taster_inv 3;
BA_ "GenSigSwitchedByIgnition" SG_ 974 HFS_Lock_Taster_inv 0;
BA_ "GenSigSendType" SG_ 974 HFS_MRollo_Schalter 3;
BA_ "GenSigStartValue" SG_ 974 HFS_MRollo_Schalter 6;
BA_ "GenSigSwitchedByIgnition" SG_ 974 HFS_MRollo_Schalter 0;
BA_ "Fehlerwert" SG_ 974 HFS_MRollo_Schalter 7;
BA_ "GenSigSendType" SG_ 974 HFS_Oben_Block_erw 3;
BA_ "GenSigSwitchedByIgnition" SG_ 974 HFS_Oben_Block_erw 0;
BA_ "GenSigSendType" SG_ 974 HFS_SAD_Schalter 3;
BA_ "GenSigStartValue" SG_ 974 HFS_SAD_Schalter 14;
BA_ "GenSigSwitchedByIgnition" SG_ 974 HFS_SAD_Schalter 0;
BA_ "Fehlerwert" SG_ 974 HFS_SAD_Schalter 15;
BA_ "GenSigSendType" SG_ 974 HFS_Seitenrollo_hoch 3;
BA_ "GenSigSwitchedByIgnition" SG_ 974 HFS_Seitenrollo_hoch 0;
BA_ "GenSigSendType" SG_ 974 HFS_Seitenrollo_tief 3;
BA_ "GenSigSwitchedByIgnition" SG_ 974 HFS_Seitenrollo_tief 0;
BA_ "GenSigSendType" SG_ 974 HFS_Sperrklinke 3;
BA_ "GenSigSwitchedByIgnition" SG_ 974 HFS_Sperrklinke 0;
BA_ "GenSigSendType" SG_ 974 HFS_Status_eTAG 0;
BA_ "GenSigSwitchedByIgnition" SG_ 974 HFS_Status_eTAG 0;
BA_ "Fehlerwert" SG_ 974 HFS_Status_eTAG 3;
BA_ "GenSigSendType" SG_ 974 HFS_Status_KiSi 3;
BA_ "GenSigSwitchedByIgnition" SG_ 974 HFS_Status_KiSi 0;
BA_ "GenSigSendType" SG_ 974 HFS_TAG_betaetigt 3;
BA_ "GenSigSwitchedByIgnition" SG_ 974 HFS_TAG_betaetigt 0;
BA_ "GenSigSendType" SG_ 974 HFS_TCR_Mode_aktiv 3;
BA_ "GenSigSwitchedByIgnition" SG_ 974 HFS_TCR_Mode_aktiv 0;
BA_ "GenSigSendType" SG_ 974 HFS_TIG_betaetigt 3;
BA_ "GenSigSwitchedByIgnition" SG_ 974 HFS_TIG_betaetigt 0;
BA_ "GenSigSendType" SG_ 974 HFS_Tuer_geoeffnet 3;
BA_ "GenSigSwitchedByIgnition" SG_ 974 HFS_Tuer_geoeffnet 0;
BA_ "GenSigSendType" SG_ 974 HFS_Tuer_Status 3;
BA_ "GenSigSwitchedByIgnition" SG_ 974 HFS_Tuer_Status 0;
BA_ "Fehlerwert" SG_ 974 HFS_Tuer_Status 3;
BA_ "GenSigSendType" SG_ 974 HFS_Tuer_Status_QBit 0;
BA_ "GenSigSwitchedByIgnition" SG_ 974 HFS_Tuer_Status_QBit 0;
BA_ "GenSigSendType" SG_ 974 HFS_Tueroeffnen_Warnung 3;
BA_ "GenSigSwitchedByIgnition" SG_ 974 HFS_Tueroeffnen_Warnung 0;
BA_ "GenSigSendType" SG_ 974 HFS_Tuerschloss_defekt 0;
BA_ "GenSigSwitchedByIgnition" SG_ 974 HFS_Tuerschloss_defekt 0;
BA_ "GenSigSendType" SG_ 974 HFS_UEKB_aktiviert 3;
BA_ "GenSigSwitchedByIgnition" SG_ 974 HFS_UEKB_aktiviert 0;
BA_ "GenSigSendType" SG_ 974 HFS_Unlock_Taster 3;
BA_ "GenSigSwitchedByIgnition" SG_ 974 HFS_Unlock_Taster 0;
BA_ "GenSigSendType" SG_ 974 HFS_Unten_Block_erw 3;
BA_ "GenSigSwitchedByIgnition" SG_ 974 HFS_Unten_Block_erw 0;
BA_ "GenSigSendType" SG_ 974 HFS_verriegelt 3;
BA_ "GenSigSwitchedByIgnition" SG_ 974 HFS_verriegelt 0;
BA_ "GenSigSendType" SG_ 974 HFS_Zuziehhilfe_aktiv 3;
BA_ "GenSigSwitchedByIgnition" SG_ 974 HFS_Zuziehhilfe_aktiv 0;
BA_ "GenSigSendType" SG_ 974 MTHFS_M_Taste 3;
BA_ "GenSigSwitchedByIgnition" SG_ 974 MTHFS_M_Taste 0;
BA_ "GenSigSendType" SG_ 974 MTHFS_Pos1 3;
BA_ "GenSigSwitchedByIgnition" SG_ 974 MTHFS_Pos1 0;
BA_ "GenSigSendType" SG_ 974 MTHFS_Pos2 3;
BA_ "GenSigSwitchedByIgnition" SG_ 974 MTHFS_Pos2 0;
BA_ "GenSigSendType" SG_ 974 MTHFS_Pos3 3;
BA_ "GenSigSwitchedByIgnition" SG_ 974 MTHFS_Pos3 0;
BA_ "GenSigSendType" SG_ 974 SSR_HFS_Pos_Unten 0;
BA_ "GenSigSwitchedByIgnition" SG_ 974 SSR_HFS_Pos_Unten 0;
BA_ "GenSigSendType" SG_ 1458 TSG_FlHz_HFS_FnAbbruchHzKreis_A 3;
BA_ "GenSigSwitchedByIgnition" SG_ 1458 TSG_FlHz_HFS_FnAbbruchHzKreis_A 0;
BA_ "GenSigSendType" SG_ 1458 TSG_FlHz_HFS_FnAbbruchHzKreis_B 3;
BA_ "GenSigSwitchedByIgnition" SG_ 1458 TSG_FlHz_HFS_FnAbbruchHzKreis_B 0;
BA_ "GenSigSendType" SG_ 1458 TSG_FlHz_HFS_NTC_A 3;
BA_ "GenSigStartValue" SG_ 1458 TSG_FlHz_HFS_NTC_A 127;
BA_ "GenSigSwitchedByIgnition" SG_ 1458 TSG_FlHz_HFS_NTC_A 0;
BA_ "GenSigSendType" SG_ 1458 TSG_FlHz_HFS_NTC_B 3;
BA_ "GenSigStartValue" SG_ 1458 TSG_FlHz_HFS_NTC_B 127;
BA_ "GenSigSwitchedByIgnition" SG_ 1458 TSG_FlHz_HFS_NTC_B 0;
BA_ "GenSigSendType" SG_ 346 MO_Anforderung_HMS 3;
BA_ "GenSigSwitchedByIgnition" SG_ 346 MO_Anforderung_HMS 0;
BA_ "GenSigSendType" SG_ 346 TSK_08_BZ 0;
BA_ "GenSigFuncType" SG_ 346 TSK_08_BZ 1;
BA_ "GenSigSwitchedByIgnition" SG_ 346 TSK_08_BZ 0;
BA_ "GenSigSendType" SG_ 346 TSK_08_CRC 0;
BA_ "GenSigFuncType" SG_ 346 TSK_08_CRC 2;
BA_ "GenSigSwitchedByIgnition" SG_ 346 TSK_08_CRC 0;
BA_ "GenSigSendType" SG_ 346 TSK_aktives_System 3;
BA_ "GenSigSwitchedByIgnition" SG_ 346 TSK_aktives_System 0;
BA_ "GenSigSendType" SG_ 346 TSK_Anf_Antriebsmoment 3;
BA_ "GenSigSwitchedByIgnition" SG_ 346 TSK_Anf_Antriebsmoment 0;
BA_ "GenSigSendType" SG_ 346 TSK_Einheit_vMax_Fahrerassistenz 0;
BA_ "GenSigSwitchedByIgnition" SG_ 346 TSK_Einheit_vMax_Fahrerassistenz 0;
BA_ "GenSigSendType" SG_ 346 TSK_erhoehter_Fahrwiderstand 3;
BA_ "GenSigSwitchedByIgnition" SG_ 346 TSK_erhoehter_Fahrwiderstand 0;
BA_ "GenSigSendType" SG_ 346 TSK_Status_ARA 3;
BA_ "GenSigStartValue" SG_ 346 TSK_Status_ARA 1;
BA_ "GenSigSwitchedByIgnition" SG_ 346 TSK_Status_ARA 0;
BA_ "Fehlerwert" SG_ 346 TSK_Status_ARA 7;
BA_ "GenSigSendType" SG_ 346 TSK_Status_EA 3;
BA_ "GenSigStartValue" SG_ 346 TSK_Status_EA 1;
BA_ "GenSigSwitchedByIgnition" SG_ 346 TSK_Status_EA 0;
BA_ "Fehlerwert" SG_ 346 TSK_Status_EA 7;
BA_ "GenSigSendType" SG_ 346 TSK_Status_IPA 3;
BA_ "GenSigStartValue" SG_ 346 TSK_Status_IPA 1;
BA_ "GenSigSwitchedByIgnition" SG_ 346 TSK_Status_IPA 0;
BA_ "Fehlerwert" SG_ 346 TSK_Status_IPA 7;
BA_ "GenSigSendType" SG_ 346 TSK_Status_PLA 3;
BA_ "GenSigStartValue" SG_ 346 TSK_Status_PLA 1;
BA_ "GenSigSwitchedByIgnition" SG_ 346 TSK_Status_PLA 0;
BA_ "Fehlerwert" SG_ 346 TSK_Status_PLA 7;
BA_ "GenSigSendType" SG_ 346 TSK_vMax_aktuell 0;
BA_ "GenSigStartValue" SG_ 346 TSK_vMax_aktuell 255;
BA_ "GenSigSendType" SG_ 346 TSK_vMax_Fahrerassistenz 0;
BA_ "GenSigStartValue" SG_ 346 TSK_vMax_Fahrerassistenz 511;
BA_ "GenSigSwitchedByIgnition" SG_ 346 TSK_vMax_Fahrerassistenz 0;
BA_ "GenSigSendType" SG_ 2589283609 UGDO_Channel_1 3;
BA_ "GenSigSwitchedByIgnition" SG_ 2589283609 UGDO_Channel_1 0;
BA_ "GenSigSendType" SG_ 2589283609 UGDO_Channel_10 3;
BA_ "GenSigSwitchedByIgnition" SG_ 2589283609 UGDO_Channel_10 0;
BA_ "GenSigSendType" SG_ 2589283609 UGDO_Channel_11 3;
BA_ "GenSigSwitchedByIgnition" SG_ 2589283609 UGDO_Channel_11 0;
BA_ "GenSigSendType" SG_ 2589283609 UGDO_Channel_12 3;
BA_ "GenSigSwitchedByIgnition" SG_ 2589283609 UGDO_Channel_12 0;
BA_ "GenSigSendType" SG_ 2589283609 UGDO_Channel_13 3;
BA_ "GenSigSwitchedByIgnition" SG_ 2589283609 UGDO_Channel_13 0;
BA_ "GenSigSendType" SG_ 2589283609 UGDO_Channel_14 3;
BA_ "GenSigSwitchedByIgnition" SG_ 2589283609 UGDO_Channel_14 0;
BA_ "GenSigSendType" SG_ 2589283609 UGDO_Channel_15 3;
BA_ "GenSigSwitchedByIgnition" SG_ 2589283609 UGDO_Channel_15 0;
BA_ "GenSigSendType" SG_ 2589283609 UGDO_Channel_2 3;
BA_ "GenSigSwitchedByIgnition" SG_ 2589283609 UGDO_Channel_2 0;
BA_ "GenSigSendType" SG_ 2589283609 UGDO_Channel_3 3;
BA_ "GenSigSwitchedByIgnition" SG_ 2589283609 UGDO_Channel_3 0;
BA_ "GenSigSendType" SG_ 2589283609 UGDO_Channel_4 3;
BA_ "GenSigSwitchedByIgnition" SG_ 2589283609 UGDO_Channel_4 0;
BA_ "GenSigSendType" SG_ 2589283609 UGDO_Channel_5 3;
BA_ "GenSigSwitchedByIgnition" SG_ 2589283609 UGDO_Channel_5 0;
BA_ "GenSigSendType" SG_ 2589283609 UGDO_Channel_6 3;
BA_ "GenSigSwitchedByIgnition" SG_ 2589283609 UGDO_Channel_6 0;
BA_ "GenSigSendType" SG_ 2589283609 UGDO_Channel_7 3;
BA_ "GenSigSwitchedByIgnition" SG_ 2589283609 UGDO_Channel_7 0;
BA_ "GenSigSendType" SG_ 2589283609 UGDO_Channel_8 3;
BA_ "GenSigSwitchedByIgnition" SG_ 2589283609 UGDO_Channel_8 0;
BA_ "GenSigSendType" SG_ 2589283609 UGDO_Channel_9 3;
BA_ "GenSigSwitchedByIgnition" SG_ 2589283609 UGDO_Channel_9 0;
BA_ "GenSigSendType" SG_ 2589283609 UGDO_DoorState 3;
BA_ "GenSigSwitchedByIgnition" SG_ 2589283609 UGDO_DoorState 0;
BA_ "GenSigSendType" SG_ 2589283609 UGDO_Failure_Antenne 0;
BA_ "Fehlerwert" SG_ 2589283609 UGDO_Failure_Antenne 1;
BA_ "GenSigSendType" SG_ 2589283609 UGDO_Failure_Codierung 0;
BA_ "Fehlerwert" SG_ 2589283609 UGDO_Failure_Codierung 1;
BA_ "GenSigSendType" SG_ 2589283609 UGDO_Failure_Hardware 0;
BA_ "Fehlerwert" SG_ 2589283609 UGDO_Failure_Hardware 1;
BA_ "GenSigSendType" SG_ 2589283609 UGDO_Function_01 0;
BA_ "Fehlerwert" SG_ 2589283609 UGDO_Function_01 7;
BA_ "GenSigSendType" SG_ 2589283609 UGDO_LED_Code_01 0;
BA_ "GenSigSendType" SG_ 2589283609 UGDO_ResponseError 0;
BA_ "Fehlerwert" SG_ 2589283609 UGDO_ResponseError 1;
BA_ "GenSigSendType" SG_ 1718 UH_DLS 0;
BA_ "GenSigSwitchedByIgnition" SG_ 1718 UH_DLS 0;
BA_ "GenSigSendType" SG_ 1718 UH_Jahr 0;
BA_ "GenSigSwitchedByIgnition" SG_ 1718 UH_Jahr 0;
BA_ "GenSigSendType" SG_ 1718 UH_Minute 0;
BA_ "GenSigSwitchedByIgnition" SG_ 1718 UH_Minute 0;
BA_ "GenSigSendType" SG_ 1718 UH_Monat 0;
BA_ "GenSigSwitchedByIgnition" SG_ 1718 UH_Monat 0;
BA_ "Fehlerwert" SG_ 1718 UH_Monat 15;
BA_ "GenSigSendType" SG_ 1718 UH_Sekunde 0;
BA_ "GenSigSwitchedByIgnition" SG_ 1718 UH_Sekunde 0;
BA_ "GenSigSendType" SG_ 1718 UH_Stunde 0;
BA_ "GenSigSwitchedByIgnition" SG_ 1718 UH_Stunde 0;
BA_ "GenSigSendType" SG_ 1718 UH_Tag 0;
BA_ "GenSigSwitchedByIgnition" SG_ 1718 UH_Tag 0;
BA_ "GenSigSendType" SG_ 1718 UH_Typ 0;
BA_ "GenSigFuncType" SG_ 1718 UH_Typ 8;
BA_ "GenSigSwitchedByIgnition" SG_ 1718 UH_Typ 0;
BA_ "GenSigSendType" SG_ 2463978633 VAS_L_01_BZ 0;
BA_ "GenSigFuncType" SG_ 2463978633 VAS_L_01_BZ 1;
BA_ "GenSigSwitchedByIgnition" SG_ 2463978633 VAS_L_01_BZ 0;
BA_ "GenSigSendType" SG_ 2463978633 VAS_L_01_CRC 0;
BA_ "GenSigFuncType" SG_ 2463978633 VAS_L_01_CRC 2;
BA_ "GenSigSwitchedByIgnition" SG_ 2463978633 VAS_L_01_CRC 0;
BA_ "GenSigSendType" SG_ 2463978633 VAS_L_Autobahnview_aktiv 3;
BA_ "GenSigSwitchedByIgnition" SG_ 2463978633 VAS_L_Autobahnview_aktiv 0;
BA_ "GenSigSendType" SG_ 2463978633 VAS_L_Bedien_Master 3;
BA_ "GenSigSwitchedByIgnition" SG_ 2463978633 VAS_L_Bedien_Master 0;
BA_ "GenSigSendType" SG_ 2463978633 VAS_L_Heizung_Aktiv 3;
BA_ "GenSigSwitchedByIgnition" SG_ 2463978633 VAS_L_Heizung_Aktiv 0;
BA_ "Fehlerwert" SG_ 2463978633 VAS_L_Heizung_Aktiv 127;
BA_ "GenSigSendType" SG_ 2463978633 VAS_L_HMI_Aktiv 3;
BA_ "GenSigSwitchedByIgnition" SG_ 2463978633 VAS_L_HMI_Aktiv 0;
BA_ "GenSigSendType" SG_ 2463978633 VAS_L_Parkview_aktiv 3;
BA_ "GenSigSwitchedByIgnition" SG_ 2463978633 VAS_L_Parkview_aktiv 0;
BA_ "GenSigSendType" SG_ 2463978633 VAS_L_Spiegelauswahl 3;
BA_ "GenSigSwitchedByIgnition" SG_ 2463978633 VAS_L_Spiegelauswahl 0;
BA_ "GenSigSendType" SG_ 2463978633 VAS_L_SWA_HMI_Diagnose 0;
BA_ "GenSigSwitchedByIgnition" SG_ 2463978633 VAS_L_SWA_HMI_Diagnose 0;
BA_ "GenSigSendType" SG_ 2463978633 VAS_L_Texte 3;
BA_ "GenSigStartValue" SG_ 2463978633 VAS_L_Texte 7;
BA_ "GenSigSwitchedByIgnition" SG_ 2463978633 VAS_L_Texte 0;
BA_ "GenSigSendType" SG_ 2463978633 VAS_L_Turnview_aktiv 3;
BA_ "GenSigSwitchedByIgnition" SG_ 2463978633 VAS_L_Turnview_aktiv 0;
BA_ "GenSigSendType" SG_ 2463978633 VAS_L_Verstell_Pos_X 3;
BA_ "GenSigSwitchedByIgnition" SG_ 2463978633 VAS_L_Verstell_Pos_X 0;
BA_ "Fehlerwert" SG_ 2463978633 VAS_L_Verstell_Pos_X 511;
BA_ "GenSigSendType" SG_ 2463978633 VAS_L_Verstell_Pos_Y 3;
BA_ "GenSigSwitchedByIgnition" SG_ 2463978633 VAS_L_Verstell_Pos_Y 0;
BA_ "Fehlerwert" SG_ 2463978633 VAS_L_Verstell_Pos_Y 511;
BA_ "GenSigSendType" SG_ 2463978633 VAS_L_Zoom_Level 3;
BA_ "GenSigSwitchedByIgnition" SG_ 2463978633 VAS_L_Zoom_Level 0;
BA_ "Fehlerwert" SG_ 2463978633 VAS_L_Zoom_Level 127;
BA_ "GenSigSendType" SG_ 2463978636 VAS_L_Autobahnview_BAP_Freigabe 3;
BA_ "GenSigSwitchedByIgnition" SG_ 2463978636 VAS_L_Autobahnview_BAP_Freigabe 0;
BA_ "GenSigSendType" SG_ 2463978636 VAS_L_Betriebsstunden 0;
BA_ "GenSigStartValue" SG_ 2463978636 VAS_L_Betriebsstunden 255;
BA_ "GenSigSwitchedByIgnition" SG_ 2463978636 VAS_L_Betriebsstunden 0;
BA_ "GenSigSendType" SG_ 2463978636 VAS_L_DefaultView 3;
BA_ "GenSigSwitchedByIgnition" SG_ 2463978636 VAS_L_DefaultView 0;
BA_ "GenSigSendType" SG_ 2463978636 VAS_L_Dimmung 3;
BA_ "GenSigStartValue" SG_ 2463978636 VAS_L_Dimmung 126;
BA_ "GenSigSwitchedByIgnition" SG_ 2463978636 VAS_L_Dimmung 0;
BA_ "Fehlerwert" SG_ 2463978636 VAS_L_Dimmung 127;
BA_ "GenSigSendType" SG_ 2463978636 VAS_L_Dimmung_BAP_Anf 3;
BA_ "GenSigStartValue" SG_ 2463978636 VAS_L_Dimmung_BAP_Anf 254;
BA_ "GenSigSwitchedByIgnition" SG_ 2463978636 VAS_L_Dimmung_BAP_Anf 0;
BA_ "Fehlerwert" SG_ 2463978636 VAS_L_Dimmung_BAP_Anf 255;
BA_ "GenSigSendType" SG_ 2463978636 VAS_L_Display_Sync 3;
BA_ "GenSigSwitchedByIgnition" SG_ 2463978636 VAS_L_Display_Sync 0;
BA_ "Fehlerwert" SG_ 2463978636 VAS_L_Display_Sync 3;
BA_ "GenSigSendType" SG_ 2463978636 VAS_L_HBM 3;
BA_ "GenSigSwitchedByIgnition" SG_ 2463978636 VAS_L_HBM 0;
BA_ "GenSigSendType" SG_ 2463978636 VAS_L_PanAndZoom_Ctrl_Req_R 3;
BA_ "GenSigSwitchedByIgnition" SG_ 2463978636 VAS_L_PanAndZoom_Ctrl_Req_R 0;
BA_ "GenSigSendType" SG_ 2463978636 VAS_L_Parkview_BAP_Freigabe 3;
BA_ "GenSigSwitchedByIgnition" SG_ 2463978636 VAS_L_Parkview_BAP_Freigabe 0;
BA_ "GenSigSendType" SG_ 2463978636 VAS_L_Turnview_BAP_Freigabe 3;
BA_ "GenSigSwitchedByIgnition" SG_ 2463978636 VAS_L_Turnview_BAP_Freigabe 0;
BA_ "GenSigSendType" SG_ 2463978636 VAS_L_Verstell_Pos_X_Req_R 3;
BA_ "GenSigSwitchedByIgnition" SG_ 2463978636 VAS_L_Verstell_Pos_X_Req_R 0;
BA_ "Fehlerwert" SG_ 2463978636 VAS_L_Verstell_Pos_X_Req_R 511;
BA_ "GenSigSendType" SG_ 2463978636 VAS_L_Verstell_Pos_Y_Req_R 3;
BA_ "GenSigSwitchedByIgnition" SG_ 2463978636 VAS_L_Verstell_Pos_Y_Req_R 0;
BA_ "Fehlerwert" SG_ 2463978636 VAS_L_Verstell_Pos_Y_Req_R 511;
BA_ "GenSigSendType" SG_ 2463978636 VAS_L_Zoom_Level_Req_R 3;
BA_ "GenSigStartValue" SG_ 2463978636 VAS_L_Zoom_Level_Req_R 100;
BA_ "GenSigSwitchedByIgnition" SG_ 2463978636 VAS_L_Zoom_Level_Req_R 0;
BA_ "Fehlerwert" SG_ 2463978636 VAS_L_Zoom_Level_Req_R 255;
BA_ "GenSigSendType" SG_ 2463978634 VAS_R_01_BZ 0;
BA_ "GenSigFuncType" SG_ 2463978634 VAS_R_01_BZ 1;
BA_ "GenSigSwitchedByIgnition" SG_ 2463978634 VAS_R_01_BZ 0;
BA_ "GenSigSendType" SG_ 2463978634 VAS_R_01_CRC 0;
BA_ "GenSigFuncType" SG_ 2463978634 VAS_R_01_CRC 2;
BA_ "GenSigSwitchedByIgnition" SG_ 2463978634 VAS_R_01_CRC 0;
BA_ "GenSigSendType" SG_ 2463978634 VAS_R_Autobahnview_aktiv 3;
BA_ "GenSigSwitchedByIgnition" SG_ 2463978634 VAS_R_Autobahnview_aktiv 0;
BA_ "GenSigSendType" SG_ 2463978634 VAS_R_Bedien_Master 3;
BA_ "GenSigSwitchedByIgnition" SG_ 2463978634 VAS_R_Bedien_Master 0;
BA_ "GenSigSendType" SG_ 2463978634 VAS_R_Fahrerwarnung 3;
BA_ "GenSigStartValue" SG_ 2463978634 VAS_R_Fahrerwarnung 7;
BA_ "GenSigSwitchedByIgnition" SG_ 2463978634 VAS_R_Fahrerwarnung 0;
BA_ "GenSigSendType" SG_ 2463978634 VAS_R_Heizung_Aktiv 3;
BA_ "GenSigSwitchedByIgnition" SG_ 2463978634 VAS_R_Heizung_Aktiv 0;
BA_ "Fehlerwert" SG_ 2463978634 VAS_R_Heizung_Aktiv 127;
BA_ "GenSigSendType" SG_ 2463978634 VAS_R_HMI_Aktiv 3;
BA_ "GenSigSwitchedByIgnition" SG_ 2463978634 VAS_R_HMI_Aktiv 0;
BA_ "GenSigSendType" SG_ 2463978634 VAS_R_Parkview_aktiv 3;
BA_ "GenSigSwitchedByIgnition" SG_ 2463978634 VAS_R_Parkview_aktiv 0;
BA_ "GenSigSendType" SG_ 2463978634 VAS_R_Spiegelauswahl 3;
BA_ "GenSigSwitchedByIgnition" SG_ 2463978634 VAS_R_Spiegelauswahl 0;
BA_ "GenSigSendType" SG_ 2463978634 VAS_R_SWA_HMI_Diagnose 0;
BA_ "GenSigSwitchedByIgnition" SG_ 2463978634 VAS_R_SWA_HMI_Diagnose 0;
BA_ "GenSigSendType" SG_ 2463978634 VAS_R_Turnview_aktiv 3;
BA_ "GenSigSwitchedByIgnition" SG_ 2463978634 VAS_R_Turnview_aktiv 0;
BA_ "GenSigSendType" SG_ 2463978634 VAS_R_Verstell_Pos_X 3;
BA_ "GenSigSwitchedByIgnition" SG_ 2463978634 VAS_R_Verstell_Pos_X 0;
BA_ "Fehlerwert" SG_ 2463978634 VAS_R_Verstell_Pos_X 511;
BA_ "GenSigSendType" SG_ 2463978634 VAS_R_Verstell_Pos_Y 3;
BA_ "GenSigSwitchedByIgnition" SG_ 2463978634 VAS_R_Verstell_Pos_Y 0;
BA_ "Fehlerwert" SG_ 2463978634 VAS_R_Verstell_Pos_Y 511;
BA_ "GenSigSendType" SG_ 2463978634 VAS_R_Zoom_Level 3;
BA_ "GenSigStartValue" SG_ 2463978634 VAS_R_Zoom_Level 70;
BA_ "GenSigSwitchedByIgnition" SG_ 2463978634 VAS_R_Zoom_Level 0;
BA_ "Fehlerwert" SG_ 2463978634 VAS_R_Zoom_Level 127;
BA_ "GenSigSendType" SG_ 2463978637 VAS_R_Autobahnview_BAP_Status 3;
BA_ "GenSigSwitchedByIgnition" SG_ 2463978637 VAS_R_Autobahnview_BAP_Status 0;
BA_ "GenSigSendType" SG_ 2463978637 VAS_R_Betriebsstunden 0;
BA_ "GenSigStartValue" SG_ 2463978637 VAS_R_Betriebsstunden 255;
BA_ "GenSigSwitchedByIgnition" SG_ 2463978637 VAS_R_Betriebsstunden 0;
BA_ "GenSigSendType" SG_ 2463978637 VAS_R_DefaultView 3;
BA_ "GenSigSwitchedByIgnition" SG_ 2463978637 VAS_R_DefaultView 0;
BA_ "GenSigSendType" SG_ 2463978637 VAS_R_Dimmung 3;
BA_ "GenSigStartValue" SG_ 2463978637 VAS_R_Dimmung 126;
BA_ "GenSigSwitchedByIgnition" SG_ 2463978637 VAS_R_Dimmung 0;
BA_ "Fehlerwert" SG_ 2463978637 VAS_R_Dimmung 127;
BA_ "GenSigSendType" SG_ 2463978637 VAS_R_Dimmung_BAP_Status 3;
BA_ "GenSigStartValue" SG_ 2463978637 VAS_R_Dimmung_BAP_Status 254;
BA_ "GenSigSwitchedByIgnition" SG_ 2463978637 VAS_R_Dimmung_BAP_Status 0;
BA_ "Fehlerwert" SG_ 2463978637 VAS_R_Dimmung_BAP_Status 255;
BA_ "GenSigSendType" SG_ 2463978637 VAS_R_Display_Sync 3;
BA_ "GenSigSwitchedByIgnition" SG_ 2463978637 VAS_R_Display_Sync 0;
BA_ "Fehlerwert" SG_ 2463978637 VAS_R_Display_Sync 3;
BA_ "GenSigSendType" SG_ 2463978637 VAS_R_HBM 3;
BA_ "GenSigSwitchedByIgnition" SG_ 2463978637 VAS_R_HBM 0;
BA_ "GenSigSendType" SG_ 2463978637 VAS_R_PanAndZoom_Ctrl_Req_L 3;
BA_ "GenSigSwitchedByIgnition" SG_ 2463978637 VAS_R_PanAndZoom_Ctrl_Req_L 0;
BA_ "GenSigSendType" SG_ 2463978637 VAS_R_Parkview_BAP_Status 3;
BA_ "GenSigSwitchedByIgnition" SG_ 2463978637 VAS_R_Parkview_BAP_Status 0;
BA_ "GenSigSendType" SG_ 2463978637 VAS_R_Turnview_BAP_Status 3;
BA_ "GenSigSwitchedByIgnition" SG_ 2463978637 VAS_R_Turnview_BAP_Status 0;
BA_ "GenSigSendType" SG_ 2463978637 VAS_R_Verstell_Pos_X_Req_L 3;
BA_ "GenSigSwitchedByIgnition" SG_ 2463978637 VAS_R_Verstell_Pos_X_Req_L 0;
BA_ "Fehlerwert" SG_ 2463978637 VAS_R_Verstell_Pos_X_Req_L 511;
BA_ "GenSigSendType" SG_ 2463978637 VAS_R_Verstell_Pos_Y_Req_L 3;
BA_ "GenSigSwitchedByIgnition" SG_ 2463978637 VAS_R_Verstell_Pos_Y_Req_L 0;
BA_ "Fehlerwert" SG_ 2463978637 VAS_R_Verstell_Pos_Y_Req_L 511;
BA_ "GenSigSendType" SG_ 2463978637 VAS_R_Zoom_Level_Req_L 3;
BA_ "GenSigStartValue" SG_ 2463978637 VAS_R_Zoom_Level_Req_L 100;
BA_ "GenSigSwitchedByIgnition" SG_ 2463978637 VAS_R_Zoom_Level_Req_L 0;
BA_ "Fehlerwert" SG_ 2463978637 VAS_R_Zoom_Level_Req_L 255;
BA_ "GenSigSendType" SG_ 995 VD_SpannungsAnf 3;
BA_ "GenSigSwitchedByIgnition" SG_ 995 VD_SpannungsAnf 0;
BA_ "GenSigSendType" SG_ 995 Verdeck_01_BZ 0;
BA_ "GenSigFuncType" SG_ 995 Verdeck_01_BZ 1;
BA_ "GenSigSwitchedByIgnition" SG_ 995 Verdeck_01_BZ 0;
BA_ "GenSigSendType" SG_ 995 Verdeck_01_CRC 0;
BA_ "GenSigFuncType" SG_ 995 Verdeck_01_CRC 2;
BA_ "GenSigActiveRepetitions" SG_ 995 VS_BFS_AutoHoch 5;
BA_ "GenSigSendType" SG_ 995 VS_BFS_AutoHoch 4;
BA_ "GenSigSwitchedByIgnition" SG_ 995 VS_BFS_AutoHoch 0;
BA_ "GenSigActiveRepetitions" SG_ 995 VS_BFS_AutoTief 5;
BA_ "GenSigSendType" SG_ 995 VS_BFS_AutoTief 4;
BA_ "GenSigSwitchedByIgnition" SG_ 995 VS_BFS_AutoTief 0;
BA_ "GenSigActiveRepetitions" SG_ 995 VS_BFS_ManHoch 5;
BA_ "GenSigSendType" SG_ 995 VS_BFS_ManHoch 4;
BA_ "GenSigSwitchedByIgnition" SG_ 995 VS_BFS_ManHoch 0;
BA_ "GenSigActiveRepetitions" SG_ 995 VS_BFS_ManTief 5;
BA_ "GenSigSendType" SG_ 995 VS_BFS_ManTief 4;
BA_ "GenSigSwitchedByIgnition" SG_ 995 VS_BFS_ManTief 0;
BA_ "GenSigSendType" SG_ 995 VS_Buzzer 3;
BA_ "GenSigSwitchedByIgnition" SG_ 995 VS_Buzzer 0;
BA_ "GenSigSendType" SG_ 995 VS_FH_BT_Langhub 3;
BA_ "GenSigSwitchedByIgnition" SG_ 995 VS_FH_BT_Langhub 0;
BA_ "GenSigSendType" SG_ 995 VS_FH_FT_Langhub 3;
BA_ "GenSigSwitchedByIgnition" SG_ 995 VS_FH_FT_Langhub 0;
BA_ "GenSigSendType" SG_ 995 VS_FH_HBFS_Langhub 3;
BA_ "GenSigSwitchedByIgnition" SG_ 995 VS_FH_HBFS_Langhub 0;
BA_ "GenSigSendType" SG_ 995 VS_FH_HFS_Langhub 3;
BA_ "GenSigSwitchedByIgnition" SG_ 995 VS_FH_HFS_Langhub 0;
BA_ "GenSigActiveRepetitions" SG_ 995 VS_FS_AutoHoch 5;
BA_ "GenSigSendType" SG_ 995 VS_FS_AutoHoch 4;
BA_ "GenSigSwitchedByIgnition" SG_ 995 VS_FS_AutoHoch 0;
BA_ "GenSigActiveRepetitions" SG_ 995 VS_FS_AutoTief 5;
BA_ "GenSigSendType" SG_ 995 VS_FS_AutoTief 4;
BA_ "GenSigSwitchedByIgnition" SG_ 995 VS_FS_AutoTief 0;
BA_ "GenSigActiveRepetitions" SG_ 995 VS_FS_ManHoch 5;
BA_ "GenSigSendType" SG_ 995 VS_FS_ManHoch 4;
BA_ "GenSigSwitchedByIgnition" SG_ 995 VS_FS_ManHoch 0;
BA_ "GenSigActiveRepetitions" SG_ 995 VS_FS_ManTief 5;
BA_ "GenSigSendType" SG_ 995 VS_FS_ManTief 4;
BA_ "GenSigSwitchedByIgnition" SG_ 995 VS_FS_ManTief 0;
BA_ "GenSigSendType" SG_ 995 VS_Hardtop 3;
BA_ "GenSigSwitchedByIgnition" SG_ 995 VS_Hardtop 0;
BA_ "GenSigActiveRepetitions" SG_ 995 VS_HBFS_AutoHoch 5;
BA_ "GenSigSendType" SG_ 995 VS_HBFS_AutoHoch 4;
BA_ "GenSigSwitchedByIgnition" SG_ 995 VS_HBFS_AutoHoch 0;
BA_ "GenSigActiveRepetitions" SG_ 995 VS_HBFS_AutoTief 5;
BA_ "GenSigSendType" SG_ 995 VS_HBFS_AutoTief 4;
BA_ "GenSigSwitchedByIgnition" SG_ 995 VS_HBFS_AutoTief 0;
BA_ "GenSigActiveRepetitions" SG_ 995 VS_HBFS_ManHoch 5;
BA_ "GenSigSendType" SG_ 995 VS_HBFS_ManHoch 4;
BA_ "GenSigSwitchedByIgnition" SG_ 995 VS_HBFS_ManHoch 0;
BA_ "GenSigActiveRepetitions" SG_ 995 VS_HBFS_ManTief 5;
BA_ "GenSigSendType" SG_ 995 VS_HBFS_ManTief 4;
BA_ "GenSigSwitchedByIgnition" SG_ 995 VS_HBFS_ManTief 0;
BA_ "GenSigSendType" SG_ 995 VS_HD_sperren 3;
BA_ "GenSigSwitchedByIgnition" SG_ 995 VS_HD_sperren 0;
BA_ "GenSigSendType" SG_ 995 VS_Heckschloss_auf 3;
BA_ "GenSigSwitchedByIgnition" SG_ 995 VS_Heckschloss_auf 0;
BA_ "GenSigActiveRepetitions" SG_ 995 VS_HFS_AutoHoch 5;
BA_ "GenSigSendType" SG_ 995 VS_HFS_AutoHoch 4;
BA_ "GenSigSwitchedByIgnition" SG_ 995 VS_HFS_AutoHoch 0;
BA_ "GenSigActiveRepetitions" SG_ 995 VS_HFS_AutoTief 5;
BA_ "GenSigSendType" SG_ 995 VS_HFS_AutoTief 4;
BA_ "GenSigSwitchedByIgnition" SG_ 995 VS_HFS_AutoTief 0;
BA_ "GenSigActiveRepetitions" SG_ 995 VS_HFS_ManHoch 5;
BA_ "GenSigSendType" SG_ 995 VS_HFS_ManHoch 4;
BA_ "GenSigSwitchedByIgnition" SG_ 995 VS_HFS_ManHoch 0;
BA_ "GenSigActiveRepetitions" SG_ 995 VS_HFS_ManTief 5;
BA_ "GenSigSendType" SG_ 995 VS_HFS_ManTief 4;
BA_ "GenSigSwitchedByIgnition" SG_ 995 VS_HFS_ManTief 0;
BA_ "GenSigSendType" SG_ 995 VS_HHS_enable 3;
BA_ "GenSigSwitchedByIgnition" SG_ 995 VS_HHS_enable 0;
BA_ "GenSigSendType" SG_ 995 VS_Lampe_Blk 3;
BA_ "GenSigSwitchedByIgnition" SG_ 995 VS_Lampe_Blk 0;
BA_ "GenSigSendType" SG_ 995 VS_StartStopp_Info 3;
BA_ "GenSigSwitchedByIgnition" SG_ 995 VS_StartStopp_Info 0;
BA_ "Fehlerwert" SG_ 995 VS_StartStopp_Info 3;
BA_ "GenSigSendType" SG_ 995 VS_VD_Bew_auf 3;
BA_ "GenSigSwitchedByIgnition" SG_ 995 VS_VD_Bew_auf 0;
BA_ "GenSigSendType" SG_ 995 VS_VD_Bew_zu 3;
BA_ "GenSigSwitchedByIgnition" SG_ 995 VS_VD_Bew_zu 0;
BA_ "GenSigSendType" SG_ 995 VS_VD_entriegelt 3;
BA_ "GenSigSwitchedByIgnition" SG_ 995 VS_VD_entriegelt 0;
BA_ "GenSigSendType" SG_ 995 VS_VD_Fehler 3;
BA_ "GenSigSwitchedByIgnition" SG_ 995 VS_VD_Fehler 0;
BA_ "GenSigSendType" SG_ 995 VS_VD_offen_ver 3;
BA_ "GenSigSwitchedByIgnition" SG_ 995 VS_VD_offen_ver 0;
BA_ "GenSigSendType" SG_ 995 VS_VD_zu_ver 3;
BA_ "GenSigSwitchedByIgnition" SG_ 995 VS_VD_zu_ver 0;
BA_ "GenSigSendType" SG_ 995 VS_VD_Zwischenposition 3;
BA_ "GenSigSwitchedByIgnition" SG_ 995 VS_VD_Zwischenposition 0;
BA_ "GenSigSendType" SG_ 995 VS_VDKD_auf 3;
BA_ "GenSigSwitchedByIgnition" SG_ 995 VS_VDKD_auf 0;
BA_ "GenSigSendType" SG_ 995 VS_Verdeck_Anf 3;
BA_ "GenSigSwitchedByIgnition" SG_ 995 VS_Verdeck_Anf 0;
BA_ "GenSigSendType" SG_ 995 VS_Windschott_nicht_abgelegt 3;
BA_ "GenSigSwitchedByIgnition" SG_ 995 VS_Windschott_nicht_abgelegt 0;
BA_ "GenSigSendType" SG_ 995 VSG_Meldungen 3;
BA_ "GenSigSwitchedByIgnition" SG_ 995 VSG_Meldungen 0;
BA_ "GenSigSwitchedByIgnition" SG_ 1716 KS_Geheimnis_1 0;
BA_ "GenSigSwitchedByIgnition" SG_ 1716 KS_Geheimnis_2 0;
BA_ "GenSigSwitchedByIgnition" SG_ 1716 KS_Geheimnis_3 0;
BA_ "GenSigSwitchedByIgnition" SG_ 1716 KS_Geheimnis_4 0;
BA_ "GenSigSendType" SG_ 1716 VIN_01_MUX 0;
BA_ "GenSigSwitchedByIgnition" SG_ 1716 VIN_01_MUX 0;
BA_ "GenSigStartValue" SG_ 1716 VIN_1 45;
BA_ "GenSigSwitchedByIgnition" SG_ 1716 VIN_1 0;
BA_ "GenSigStartValue" SG_ 1716 VIN_10 45;
BA_ "GenSigSwitchedByIgnition" SG_ 1716 VIN_10 0;
BA_ "GenSigStartValue" SG_ 1716 VIN_11 45;
BA_ "GenSigSwitchedByIgnition" SG_ 1716 VIN_11 0;
BA_ "GenSigStartValue" SG_ 1716 VIN_12 45;
BA_ "GenSigSwitchedByIgnition" SG_ 1716 VIN_12 0;
BA_ "GenSigStartValue" SG_ 1716 VIN_13 45;
BA_ "GenSigSwitchedByIgnition" SG_ 1716 VIN_13 0;
BA_ "GenSigStartValue" SG_ 1716 VIN_14 45;
BA_ "GenSigSwitchedByIgnition" SG_ 1716 VIN_14 0;
BA_ "GenSigStartValue" SG_ 1716 VIN_15 45;
BA_ "GenSigSwitchedByIgnition" SG_ 1716 VIN_15 0;
BA_ "GenSigStartValue" SG_ 1716 VIN_16 45;
BA_ "GenSigSwitchedByIgnition" SG_ 1716 VIN_16 0;
BA_ "GenSigStartValue" SG_ 1716 VIN_17 45;
BA_ "GenSigSwitchedByIgnition" SG_ 1716 VIN_17 0;
BA_ "GenSigStartValue" SG_ 1716 VIN_2 45;
BA_ "GenSigSwitchedByIgnition" SG_ 1716 VIN_2 0;
BA_ "GenSigStartValue" SG_ 1716 VIN_3 45;
BA_ "GenSigSwitchedByIgnition" SG_ 1716 VIN_3 0;
BA_ "GenSigStartValue" SG_ 1716 VIN_4 45;
BA_ "GenSigSwitchedByIgnition" SG_ 1716 VIN_4 0;
BA_ "GenSigStartValue" SG_ 1716 VIN_5 45;
BA_ "GenSigSwitchedByIgnition" SG_ 1716 VIN_5 0;
BA_ "GenSigStartValue" SG_ 1716 VIN_6 45;
BA_ "GenSigSwitchedByIgnition" SG_ 1716 VIN_6 0;
BA_ "GenSigStartValue" SG_ 1716 VIN_7 45;
BA_ "GenSigSwitchedByIgnition" SG_ 1716 VIN_7 0;
BA_ "GenSigStartValue" SG_ 1716 VIN_8 45;
BA_ "GenSigSwitchedByIgnition" SG_ 1716 VIN_8 0;
BA_ "GenSigStartValue" SG_ 1716 VIN_9 45;
BA_ "GenSigSwitchedByIgnition" SG_ 1716 VIN_9 0;
BA_ "GenSigSendType" SG_ 1361 WFS_Betrieb_Lesespule 3;
BA_ "GenSigSwitchedByIgnition" SG_ 1361 WFS_Betrieb_Lesespule 0;
BA_ "GenSigSendType" SG_ 1361 WFS_ELV_authorisiert 3;
BA_ "GenSigSwitchedByIgnition" SG_ 1361 WFS_ELV_authorisiert 0;
BA_ "GenSigSendType" SG_ 1361 WFS_Fahrerhinweise 3;
BA_ "GenSigSwitchedByIgnition" SG_ 1361 WFS_Fahrerhinweise 0;
BA_ "GenSigSendType" SG_ 1361 WFS_ID_Geb_autorisiert 3;
BA_ "GenSigSwitchedByIgnition" SG_ 1361 WFS_ID_Geb_autorisiert 0;
BA_ "GenSigSendType" SG_ 1361 WFS_ID_Geb_autorisiert_in_Kl15 3;
BA_ "GenSigSwitchedByIgnition" SG_ 1361 WFS_ID_Geb_autorisiert_in_Kl15 0;
BA_ "GenSigSendType" SG_ 1361 WFS_ID_Geb_steckt 3;
BA_ "GenSigSwitchedByIgnition" SG_ 1361 WFS_ID_Geb_steckt 0;
BA_ "GenSigSendType" SG_ 1361 WFS_Klemmenfreigabe 3;
BA_ "GenSigSwitchedByIgnition" SG_ 1361 WFS_Klemmenfreigabe 0;
BA_ "GenSigSendType" SG_ 1361 WFS_LF_Aktiv 3;
BA_ "GenSigSwitchedByIgnition" SG_ 1361 WFS_LF_Aktiv 0;
BA_ "GenSigSendType" SG_ 1361 WFS_LZ 3;
BA_ "GenSigSwitchedByIgnition" SG_ 1361 WFS_LZ 0;
BA_ "GenSigSendType" SG_ 1361 WFS_Parken_Status 3;
BA_ "GenSigSwitchedByIgnition" SG_ 1361 WFS_Parken_Status 0;
BA_ "GenSigSendType" SG_ 1361 WFS_Safe 3;
BA_ "GenSigSwitchedByIgnition" SG_ 1361 WFS_Safe 0;
BA_ "GenSigSendType" SG_ 1361 WFS_Schluessel_Fahrberecht 0;
BA_ "GenSigSwitchedByIgnition" SG_ 1361 WFS_Schluessel_Fahrberecht 0;
BA_ "GenSigSendType" SG_ 1361 WFS_Schluessel_Ist 3;
BA_ "GenSigSwitchedByIgnition" SG_ 1361 WFS_Schluessel_Ist 0;
BA_ "GenSigSendType" SG_ 1361 WFS_Schluessel_Soll 3;
BA_ "GenSigSwitchedByIgnition" SG_ 1361 WFS_Schluessel_Soll 0;
BA_ "GenSigSendType" SG_ 1702 BCM1_SRA_aktiv 3;
BA_ "GenSigSwitchedByIgnition" SG_ 1702 BCM1_SRA_aktiv 0;
BA_ "GenSigActiveRepetitions" SG_ 1702 Heckwischer_Anforderung 3;
BA_ "GenSigSendType" SG_ 1702 Heckwischer_Anforderung 4;
BA_ "GenSigSwitchedByIgnition" SG_ 1702 Heckwischer_Anforderung 0;
BA_ "GenSigSendType" SG_ 1702 Waschen_vorne_aktiv 3;
BA_ "GenSigSwitchedByIgnition" SG_ 1702 Waschen_vorne_aktiv 0;
BA_ "GenSigSendType" SG_ 1702 Wischer1_Wischgeschwindigkeit 0;
BA_ "GenSigStartValue" SG_ 1702 Wischer1_Wischgeschwindigkeit 62;
BA_ "GenSigSwitchedByIgnition" SG_ 1702 Wischer1_Wischgeschwindigkeit 0;
BA_ "Fehlerwert" SG_ 1702 Wischer1_Wischgeschwindigkeit 63;
BA_ "GenSigSendType" SG_ 1702 Wischer_Anzeigetext 3;
BA_ "GenSigSwitchedByIgnition" SG_ 1702 Wischer_Anzeigetext 0;
BA_ "GenSigSendType" SG_ 1702 Wischer_vorne_aktiv 3;
BA_ "GenSigSwitchedByIgnition" SG_ 1702 Wischer_vorne_aktiv 0;
BA_ "GenSigSendType" SG_ 1702 Wischer_vorne_blockiert 3;
BA_ "GenSigSwitchedByIgnition" SG_ 1702 Wischer_vorne_blockiert 0;
BA_ "GenSigSendType" SG_ 1702 Wischer_vorne_defekt 3;
BA_ "GenSigSwitchedByIgnition" SG_ 1702 Wischer_vorne_defekt 0;
BA_ "GenSigSendType" SG_ 1702 Wischer_vorne_Normal 3;
BA_ "GenSigSwitchedByIgnition" SG_ 1702 Wischer_vorne_Normal 0;
BA_ "GenSigSendType" SG_ 1702 Wischer_vorne_Parklage 3;
BA_ "GenSigStartValue" SG_ 1702 Wischer_vorne_Parklage 1;
BA_ "GenSigSwitchedByIgnition" SG_ 1702 Wischer_vorne_Parklage 0;
BA_ "GenSigSendType" SG_ 1702 Wischer_vorne_Schnell 3;
BA_ "GenSigSwitchedByIgnition" SG_ 1702 Wischer_vorne_Schnell 0;
BA_ "GenSigSendType" SG_ 1702 WWSs_01_upd 0;
BA_ "GenSigFuncType" SG_ 1702 WWSs_01_upd 5;
BA_ "GenSigSwitchedByIgnition" SG_ 1702 WWSs_01_upd 0;
BA_ "GenSigSwitchedByIgnition" SG_ 2617013760 XCP_BCM1_CRO_01_Data 0;
BA_ "GenSigSwitchedByIgnition" SG_ 2617013761 XCP_BCM1_DTO_01_Data 0;
BA_ "GenSigSwitchedByIgnition" SG_ 2617124608 XCP_VAS_L_CRO_01_Data 0;
BA_ "GenSigSwitchedByIgnition" SG_ 2617124609 XCP_VAS_L_DTO_01_Data 0;
BA_ "GenSigSwitchedByIgnition" SG_ 2617126656 XCP_VAS_R_CRO_01_Data 0;
BA_ "GenSigSwitchedByIgnition" SG_ 2617126657 XCP_VAS_L_DTO_01_Data 0;
BA_ "GenSigSendType" SG_ 2463978613 ZFAS_01_BZ 0;
BA_ "GenSigFuncType" SG_ 2463978613 ZFAS_01_BZ 1;
BA_ "GenSigSwitchedByIgnition" SG_ 2463978613 ZFAS_01_BZ 0;
BA_ "GenSigSendType" SG_ 2463978613 ZFAS_01_CRC 0;
BA_ "GenSigFuncType" SG_ 2463978613 ZFAS_01_CRC 2;
BA_ "GenSigSwitchedByIgnition" SG_ 2463978613 ZFAS_01_CRC 0;
BA_ "GenSigSendType" SG_ 2463978613 zFAS_Blinker_li 5;
BA_ "GenSigSwitchedByIgnition" SG_ 2463978613 zFAS_Blinker_li 0;
BA_ "GenSigSendType" SG_ 2463978613 zFAS_Blinker_re 5;
BA_ "GenSigSwitchedByIgnition" SG_ 2463978613 zFAS_Blinker_re 0;
BA_ "GenSigActiveRepetitions" SG_ 2463978613 zFAS_Pilottaster_LED_Farbe_Anf 5;
BA_ "GenSigSendType" SG_ 2463978613 zFAS_Pilottaster_LED_Farbe_Anf 4;
BA_ "GenSigActiveRepetitions" SG_ 2463978613 zFAS_Pilottaster_LED_Modus_Anf 5;
BA_ "GenSigSendType" SG_ 2463978613 zFAS_Pilottaster_LED_Modus_Anf 4;
BA_ "GenSigSendType" SG_ 388 BCM_BF_Spg_Absenkung 0;
BA_ "GenSigSwitchedByIgnition" SG_ 388 BCM_BF_Spg_Absenkung 0;
BA_ "GenSigSendType" SG_ 388 BCM_Spg_Synchron 0;
BA_ "GenSigSwitchedByIgnition" SG_ 388 BCM_Spg_Synchron 0;
BA_ "GenSigActiveRepetitions" SG_ 388 FH_BT_hoch 11;
BA_ "GenSigSendType" SG_ 388 FH_BT_hoch 6;
BA_ "GenSigSwitchedByIgnition" SG_ 388 FH_BT_hoch 0;
BA_ "GenSigActiveRepetitions" SG_ 388 FH_BT_tief 11;
BA_ "GenSigSendType" SG_ 388 FH_BT_tief 6;
BA_ "GenSigSwitchedByIgnition" SG_ 388 FH_BT_tief 0;
BA_ "GenSigActiveRepetitions" SG_ 388 FH_FT_hoch 11;
BA_ "GenSigSendType" SG_ 388 FH_FT_hoch 6;
BA_ "GenSigSwitchedByIgnition" SG_ 388 FH_FT_hoch 0;
BA_ "GenSigActiveRepetitions" SG_ 388 FH_FT_tief 11;
BA_ "GenSigSendType" SG_ 388 FH_FT_tief 6;
BA_ "GenSigSwitchedByIgnition" SG_ 388 FH_FT_tief 0;
BA_ "GenSigActiveRepetitions" SG_ 388 FH_HBFS_hoch 11;
BA_ "GenSigSendType" SG_ 388 FH_HBFS_hoch 6;
BA_ "GenSigSwitchedByIgnition" SG_ 388 FH_HBFS_hoch 0;
BA_ "GenSigActiveRepetitions" SG_ 388 FH_HBFS_tief 11;
BA_ "GenSigSendType" SG_ 388 FH_HBFS_tief 6;
BA_ "GenSigSwitchedByIgnition" SG_ 388 FH_HBFS_tief 0;
BA_ "GenSigActiveRepetitions" SG_ 388 FH_HFS_hoch 11;
BA_ "GenSigSendType" SG_ 388 FH_HFS_hoch 6;
BA_ "GenSigSwitchedByIgnition" SG_ 388 FH_HFS_hoch 0;
BA_ "GenSigActiveRepetitions" SG_ 388 FH_HFS_tief 11;
BA_ "GenSigSendType" SG_ 388 FH_HFS_tief 6;
BA_ "GenSigSwitchedByIgnition" SG_ 388 FH_HFS_tief 0;
BA_ "GenSigSendType" SG_ 388 VIP_Freigabe 0;
BA_ "GenSigSwitchedByIgnition" SG_ 388 VIP_Freigabe 0;
BA_ "GenSigActiveRepetitions" SG_ 388 VIP_Sensor_betaetigt 11;
BA_ "GenSigSendType" SG_ 388 VIP_Sensor_betaetigt 6;
BA_ "GenSigSwitchedByIgnition" SG_ 388 VIP_Sensor_betaetigt 0;
BA_ "GenSigSendType" SG_ 388 ZV_01_BZ 0;
BA_ "GenSigFuncType" SG_ 388 ZV_01_BZ 1;
BA_ "GenSigSendType" SG_ 388 ZV_01_CRC 0;
BA_ "GenSigFuncType" SG_ 388 ZV_01_CRC 2;
BA_ "GenSigActiveRepetitions" SG_ 388 ZV_auf_BT 11;
BA_ "GenSigSendType" SG_ 388 ZV_auf_BT 6;
BA_ "GenSigSwitchedByIgnition" SG_ 388 ZV_auf_BT 0;
BA_ "GenSigActiveRepetitions" SG_ 388 ZV_auf_FT 11;
BA_ "GenSigSendType" SG_ 388 ZV_auf_FT 6;
BA_ "GenSigSwitchedByIgnition" SG_ 388 ZV_auf_FT 0;
BA_ "GenSigActiveRepetitions" SG_ 388 ZV_auf_Funk 11;
BA_ "GenSigSendType" SG_ 388 ZV_auf_Funk 6;
BA_ "GenSigSwitchedByIgnition" SG_ 388 ZV_auf_Funk 0;
BA_ "GenSigActiveRepetitions" SG_ 388 ZV_auf_Kessy 11;
BA_ "GenSigSendType" SG_ 388 ZV_auf_Kessy 6;
BA_ "GenSigSwitchedByIgnition" SG_ 388 ZV_auf_Kessy 0;
BA_ "GenSigActiveRepetitions" SG_ 388 ZV_auto_Ansteuerung 11;
BA_ "GenSigSendType" SG_ 388 ZV_auto_Ansteuerung 6;
BA_ "GenSigSwitchedByIgnition" SG_ 388 ZV_auto_Ansteuerung 0;
BA_ "GenSigActiveRepetitions" SG_ 388 ZV_BT_entriegeln 11;
BA_ "GenSigSendType" SG_ 388 ZV_BT_entriegeln 6;
BA_ "GenSigSwitchedByIgnition" SG_ 388 ZV_BT_entriegeln 0;
BA_ "GenSigActiveRepetitions" SG_ 388 ZV_BT_verriegeln 11;
BA_ "GenSigSendType" SG_ 388 ZV_BT_verriegeln 6;
BA_ "GenSigSwitchedByIgnition" SG_ 388 ZV_BT_verriegeln 0;
BA_ "GenSigActiveRepetitions" SG_ 388 ZV_entriegeln_Anf 11;
BA_ "GenSigSendType" SG_ 388 ZV_entriegeln_Anf 6;
BA_ "GenSigSwitchedByIgnition" SG_ 388 ZV_entriegeln_Anf 0;
BA_ "GenSigActiveRepetitions" SG_ 388 ZV_FT_entriegeln 11;
BA_ "GenSigSendType" SG_ 388 ZV_FT_entriegeln 6;
BA_ "GenSigSwitchedByIgnition" SG_ 388 ZV_FT_entriegeln 0;
BA_ "GenSigActiveRepetitions" SG_ 388 ZV_FT_verriegeln 11;
BA_ "GenSigSendType" SG_ 388 ZV_FT_verriegeln 6;
BA_ "GenSigSwitchedByIgnition" SG_ 388 ZV_FT_verriegeln 0;
BA_ "GenSigActiveRepetitions" SG_ 388 ZV_HBFS_entriegeln 11;
BA_ "GenSigSendType" SG_ 388 ZV_HBFS_entriegeln 6;
BA_ "GenSigSwitchedByIgnition" SG_ 388 ZV_HBFS_entriegeln 0;
BA_ "GenSigActiveRepetitions" SG_ 388 ZV_HBFS_verriegeln 11;
BA_ "GenSigSendType" SG_ 388 ZV_HBFS_verriegeln 6;
BA_ "GenSigSwitchedByIgnition" SG_ 388 ZV_HBFS_verriegeln 0;
BA_ "GenSigActiveRepetitions" SG_ 388 ZV_HFS_entriegeln 11;
BA_ "GenSigSendType" SG_ 388 ZV_HFS_entriegeln 6;
BA_ "GenSigSwitchedByIgnition" SG_ 388 ZV_HFS_entriegeln 0;
BA_ "GenSigActiveRepetitions" SG_ 388 ZV_HFS_verriegeln 11;
BA_ "GenSigSendType" SG_ 388 ZV_HFS_verriegeln 6;
BA_ "GenSigSwitchedByIgnition" SG_ 388 ZV_HFS_verriegeln 0;
BA_ "GenSigActiveRepetitions" SG_ 388 ZV_HSK_entriegeln 11;
BA_ "GenSigSendType" SG_ 388 ZV_HSK_entriegeln 6;
BA_ "GenSigSwitchedByIgnition" SG_ 388 ZV_HSK_entriegeln 0;
BA_ "GenSigActiveRepetitions" SG_ 388 ZV_HSK_verriegeln 11;
BA_ "GenSigSendType" SG_ 388 ZV_HSK_verriegeln 6;
BA_ "GenSigSwitchedByIgnition" SG_ 388 ZV_HSK_verriegeln 0;
BA_ "GenSigActiveRepetitions" SG_ 388 ZV_LED_Steuerung 11;
BA_ "GenSigSendType" SG_ 388 ZV_LED_Steuerung 6;
BA_ "GenSigSwitchedByIgnition" SG_ 388 ZV_LED_Steuerung 0;
BA_ "GenSigActiveRepetitions" SG_ 388 ZV_LED_Uebernahme 11;
BA_ "GenSigSendType" SG_ 388 ZV_LED_Uebernahme 6;
BA_ "GenSigSwitchedByIgnition" SG_ 388 ZV_LED_Uebernahme 0;
BA_ "GenSigActiveRepetitions" SG_ 388 ZV_Signatur 11;
BA_ "GenSigSendType" SG_ 388 ZV_Signatur 6;
BA_ "GenSigSwitchedByIgnition" SG_ 388 ZV_Signatur 0;
BA_ "GenSigActiveRepetitions" SG_ 388 ZV_Softtouch_betaetigt 11;
BA_ "GenSigSendType" SG_ 388 ZV_Softtouch_betaetigt 6;
BA_ "GenSigSwitchedByIgnition" SG_ 388 ZV_Softtouch_betaetigt 0;
BA_ "GenSigActiveRepetitions" SG_ 388 ZV_Spg_Anklappen 11;
BA_ "GenSigSendType" SG_ 388 ZV_Spg_Anklappen 6;
BA_ "GenSigSwitchedByIgnition" SG_ 388 ZV_Spg_Anklappen 0;
BA_ "GenSigActiveRepetitions" SG_ 388 ZV_Verdeck_auf 11;
BA_ "GenSigSendType" SG_ 388 ZV_Verdeck_auf 6;
BA_ "GenSigSwitchedByIgnition" SG_ 388 ZV_Verdeck_auf 0;
BA_ "GenSigActiveRepetitions" SG_ 388 ZV_Verdeck_zu 11;
BA_ "GenSigSendType" SG_ 388 ZV_Verdeck_zu 6;
BA_ "GenSigSwitchedByIgnition" SG_ 388 ZV_Verdeck_zu 0;
BA_ "GenSigActiveRepetitions" SG_ 388 ZV_zentral_entsafen 11;
BA_ "GenSigSendType" SG_ 388 ZV_zentral_entsafen 6;
BA_ "GenSigSwitchedByIgnition" SG_ 388 ZV_zentral_entsafen 0;
BA_ "GenSigActiveRepetitions" SG_ 388 ZV_zentral_safen 11;
BA_ "GenSigSendType" SG_ 388 ZV_zentral_safen 6;
BA_ "GenSigSwitchedByIgnition" SG_ 388 ZV_zentral_safen 0;
BA_ "GenSigActiveRepetitions" SG_ 388 ZV_zu_BT 11;
BA_ "GenSigSendType" SG_ 388 ZV_zu_BT 6;
BA_ "GenSigSwitchedByIgnition" SG_ 388 ZV_zu_BT 0;
BA_ "GenSigActiveRepetitions" SG_ 388 ZV_zu_FT 11;
BA_ "GenSigSendType" SG_ 388 ZV_zu_FT 6;
BA_ "GenSigSwitchedByIgnition" SG_ 388 ZV_zu_FT 0;
BA_ "GenSigActiveRepetitions" SG_ 388 ZV_zu_Funk 11;
BA_ "GenSigSendType" SG_ 388 ZV_zu_Funk 6;
BA_ "GenSigSwitchedByIgnition" SG_ 388 ZV_zu_Funk 0;
BA_ "GenSigActiveRepetitions" SG_ 388 ZV_zu_Kessy 11;
BA_ "GenSigSendType" SG_ 388 ZV_zu_Kessy 6;
BA_ "GenSigSwitchedByIgnition" SG_ 388 ZV_zu_Kessy 0;
BA_ "GenSigActiveRepetitions" SG_ 388 ZV_zu_Zeitl_Nachverr 11;
BA_ "GenSigSendType" SG_ 388 ZV_zu_Zeitl_Nachverr 6;
BA_ "GenSigSwitchedByIgnition" SG_ 388 ZV_zu_Zeitl_Nachverr 0;
BA_ "GenSigSendType" SG_ 1411 BCM_FH_Freigabe 3;
BA_ "GenSigSwitchedByIgnition" SG_ 1411 BCM_FH_Freigabe 0;
BA_ "GenSigSendType" SG_ 1411 BCM_HSK_Freigabe 3;
BA_ "GenSigSwitchedByIgnition" SG_ 1411 BCM_HSK_Freigabe 0;
BA_ "GenSigSendType" SG_ 1411 BCM_Komfortfkt_Freigabe 3;
BA_ "GenSigSwitchedByIgnition" SG_ 1411 BCM_Komfortfkt_Freigabe 0;
BA_ "GenSigSendType" SG_ 1411 BCM_Tankklappensteller_Fehler 0;
BA_ "GenSigSwitchedByIgnition" SG_ 1411 BCM_Tankklappensteller_Fehler 0;
BA_ "Fehlerwert" SG_ 1411 BCM_Tankklappensteller_Fehler 1;
BA_ "GenSigSendType" SG_ 1411 BCM_Verdeck_Freigabe 3;
BA_ "GenSigSwitchedByIgnition" SG_ 1411 BCM_Verdeck_Freigabe 0;
BA_ "GenSigSendType" SG_ 1411 DWA_aktiv 3;
BA_ "GenSigSwitchedByIgnition" SG_ 1411 DWA_aktiv 0;
BA_ "GenSigSendType" SG_ 1411 FBS_Warn_Schluessel_Batt 3;
BA_ "GenSigSwitchedByIgnition" SG_ 1411 FBS_Warn_Schluessel_Batt 0;
BA_ "GenSigActiveRepetitions" SG_ 1411 FFB_CarFinder 5;
BA_ "GenSigSendType" SG_ 1411 FFB_CarFinder 2;
BA_ "GenSigSwitchedByIgnition" SG_ 1411 FFB_CarFinder 0;
BA_ "GenSigActiveRepetitions" SG_ 1411 FFB_Komfortoeffnen 5;
BA_ "GenSigSendType" SG_ 1411 FFB_Komfortoeffnen 2;
BA_ "GenSigSwitchedByIgnition" SG_ 1411 FFB_Komfortoeffnen 0;
BA_ "GenSigActiveRepetitions" SG_ 1411 FFB_Komfortschliessen 5;
BA_ "GenSigSendType" SG_ 1411 FFB_Komfortschliessen 2;
BA_ "GenSigSwitchedByIgnition" SG_ 1411 FFB_Komfortschliessen 0;
BA_ "GenSigSendType" SG_ 1411 HBFS_gesafet 3;
BA_ "GenSigSwitchedByIgnition" SG_ 1411 HBFS_gesafet 0;
BA_ "GenSigSendType" SG_ 1411 HBFS_verriegelt 3;
BA_ "GenSigSwitchedByIgnition" SG_ 1411 HBFS_verriegelt 0;
BA_ "GenSigSendType" SG_ 1411 HD_Hauptraste 3;
BA_ "GenSigSwitchedByIgnition" SG_ 1411 HD_Hauptraste 0;
BA_ "GenSigSendType" SG_ 1411 HD_Vorraste 3;
BA_ "GenSigSwitchedByIgnition" SG_ 1411 HD_Vorraste 0;
BA_ "GenSigSendType" SG_ 1411 HFS_gesafet 3;
BA_ "GenSigSwitchedByIgnition" SG_ 1411 HFS_gesafet 0;
BA_ "GenSigSendType" SG_ 1411 HFS_verriegelt 3;
BA_ "GenSigSwitchedByIgnition" SG_ 1411 HFS_verriegelt 0;
BA_ "GenSigSendType" SG_ 1411 IRUE_aktiv 3;
BA_ "GenSigSwitchedByIgnition" SG_ 1411 IRUE_aktiv 0;
BA_ "GenSigSendType" SG_ 1411 IRUE_Taster_Fkts_LED 3;
BA_ "GenSigSwitchedByIgnition" SG_ 1411 IRUE_Taster_Fkts_LED 0;
BA_ "GenSigSendType" SG_ 1411 ZV_BT_offen 3;
BA_ "GenSigSwitchedByIgnition" SG_ 1411 ZV_BT_offen 0;
BA_ "GenSigSendType" SG_ 1411 ZV_Einzeltuerentriegelung 3;
BA_ "GenSigSwitchedByIgnition" SG_ 1411 ZV_Einzeltuerentriegelung 0;
BA_ "GenSigSendType" SG_ 1411 ZV_FT_offen 3;
BA_ "GenSigSwitchedByIgnition" SG_ 1411 ZV_FT_offen 0;
BA_ "GenSigSendType" SG_ 1411 ZV_gesafet_extern_ist 3;
BA_ "GenSigSwitchedByIgnition" SG_ 1411 ZV_gesafet_extern_ist 0;
BA_ "GenSigSendType" SG_ 1411 ZV_gesafet_extern_soll 3;
BA_ "GenSigSwitchedByIgnition" SG_ 1411 ZV_gesafet_extern_soll 0;
BA_ "GenSigSendType" SG_ 1411 ZV_HBFS_offen 3;
BA_ "GenSigSwitchedByIgnition" SG_ 1411 ZV_HBFS_offen 0;
BA_ "GenSigSendType" SG_ 1411 ZV_HD_offen 3;
BA_ "GenSigSwitchedByIgnition" SG_ 1411 ZV_HD_offen 0;
BA_ "GenSigSendType" SG_ 1411 ZV_Heckeinzelentriegelung 3;
BA_ "GenSigSwitchedByIgnition" SG_ 1411 ZV_Heckeinzelentriegelung 0;
BA_ "GenSigSendType" SG_ 1411 ZV_HFS_offen 3;
BA_ "GenSigSwitchedByIgnition" SG_ 1411 ZV_HFS_offen 0;
BA_ "GenSigSendType" SG_ 1411 ZV_HS_offen 3;
BA_ "GenSigSwitchedByIgnition" SG_ 1411 ZV_HS_offen 0;
BA_ "GenSigSendType" SG_ 1411 ZV_ist_Zustand_verfuegbar 3;
BA_ "GenSigSwitchedByIgnition" SG_ 1411 ZV_ist_Zustand_verfuegbar 0;
BA_ "GenSigSendType" SG_ 1411 ZV_Oeffnungsmodus 3;
BA_ "GenSigSwitchedByIgnition" SG_ 1411 ZV_Oeffnungsmodus 0;
BA_ "GenSigSendType" SG_ 1411 ZV_Rollo_auf 3;
BA_ "GenSigSwitchedByIgnition" SG_ 1411 ZV_Rollo_auf 0;
BA_ "GenSigSendType" SG_ 1411 ZV_Rollo_zu 3;
BA_ "GenSigSwitchedByIgnition" SG_ 1411 ZV_Rollo_zu 0;
BA_ "GenSigSendType" SG_ 1411 ZV_SAD_auf 3;
BA_ "GenSigSwitchedByIgnition" SG_ 1411 ZV_SAD_auf 0;
BA_ "GenSigSendType" SG_ 1411 ZV_SAD_zu 3;
BA_ "GenSigSwitchedByIgnition" SG_ 1411 ZV_SAD_zu 0;
BA_ "GenSigSendType" SG_ 1411 ZV_SafeFunktion_aktiv 3;
BA_ "GenSigSwitchedByIgnition" SG_ 1411 ZV_SafeFunktion_aktiv 0;
BA_ "GenSigActiveRepetitions" SG_ 1411 ZV_Schluessel_Zugang 5;
BA_ "GenSigSendType" SG_ 1411 ZV_Schluessel_Zugang 4;
BA_ "GenSigSwitchedByIgnition" SG_ 1411 ZV_Schluessel_Zugang 0;
BA_ "GenSigSendType" SG_ 1411 ZV_Tankklappe_offen 0;
BA_ "GenSigSwitchedByIgnition" SG_ 1411 ZV_Tankklappe_offen 0;
BA_ "GenSigSendType" SG_ 1411 ZV_verriegelt_extern_ist 3;
BA_ "GenSigSwitchedByIgnition" SG_ 1411 ZV_verriegelt_extern_ist 0;
BA_ "GenSigSendType" SG_ 1411 ZV_verriegelt_extern_soll 3;
BA_ "GenSigSwitchedByIgnition" SG_ 1411 ZV_verriegelt_extern_soll 0;
BA_ "GenSigSendType" SG_ 1411 ZV_verriegelt_intern_ist 3;
BA_ "GenSigSwitchedByIgnition" SG_ 1411 ZV_verriegelt_intern_ist 0;
BA_ "GenSigSendType" SG_ 1411 ZV_verriegelt_intern_soll 3;
BA_ "GenSigSwitchedByIgnition" SG_ 1411 ZV_verriegelt_intern_soll 0;
BA_ "GenSigSendType" SG_ 1411 ZV_verriegelt_soll 3;
BA_ "GenSigSwitchedByIgnition" SG_ 1411 ZV_verriegelt_soll 0;
BA_REL_ "GenSigTimeoutTime" BU_SG_REL_ BCM1 SG_ 976 FT_Tuer_geoeffnet 1000;
BA_REL_ "GenSigTimeoutTime" BU_SG_REL_ BCM1 SG_ 976 FT_TIG_betaetigt 1000;
BA_REL_ "GenSigTimeoutTime" BU_SG_REL_ BCM1 SG_ 976 FT_Sp_Blk_def 1000;
BA_REL_ "GenSigTimeoutTime" BU_SG_REL_ BCM1 SG_ 976 FT_FH_Oeffnung 1000;
BA_REL_ "GenSigTimeoutTime" BU_SG_REL_ BCM1 SG_ 976 FT_Kisi_li_aktiv 1000;
BA_REL_ "GenSigTimeoutTime" BU_SG_REL_ BCM1 SG_ 976 FT_Kisi_re_aktiv 1000;
BA_REL_ "GenSigTimeoutTime" BU_SG_REL_ BCM1 SG_ 976 FT_Kisi_Fehler 1000;
BA_REL_ "GenSigTimeoutTime" BU_SG_REL_ BCM1 SG_ 976 FT_SP_Heizung_Status 1000;
BA_REL_ "GenSigTimeoutTime" BU_SG_REL_ BCM1 SG_ 976 ASW_Warnung_aktiv_FS 1000;
BA_REL_ "GenSigTimeoutTime" BU_SG_REL_ BCM1 SG_ 1449 TSG_FlHz_FS_NTC_A 5000;
BA_REL_ "GenSigTimeoutTime" BU_SG_REL_ BCM1 SG_ 1449 TSG_FlHz_FS_FnAbbruchHzKreis_A 5000;
BA_REL_ "GenSigTimeoutTime" BU_SG_REL_ BCM1 SG_ 1449 TSG_FlHz_FS_NTC_B 5000;
BA_REL_ "GenSigTimeoutTime" BU_SG_REL_ BCM1 SG_ 1449 TSG_FlHz_FS_FnAbbruchHzKreis_B 5000;
BA_REL_ "GenSigTimeoutTime" BU_SG_REL_ BCM1 SG_ 975 HBFS_Tuer_geoeffnet 1000;
BA_REL_ "GenSigTimeoutTime" BU_SG_REL_ BCM1 SG_ 975 HBFS_TIG_betaetigt 1000;
BA_REL_ "GenSigTimeoutTime" BU_SG_REL_ BCM1 SG_ 975 HBFS_FH_Oeffnung 1000;
BA_REL_ "GenSigTimeoutTime" BU_SG_REL_ BCM1 SG_ 975 ASW_Warnung_aktiv_HBFS 1000;
BA_REL_ "GenSigTimeoutTime" BU_SG_REL_ BCM1 SG_ 975 HBFS_Seitenrollo_hoch 1000;
BA_REL_ "GenSigTimeoutTime" BU_SG_REL_ BCM1 SG_ 975 HBFS_Seitenrollo_tief 1000;
BA_REL_ "GenSigTimeoutTime" BU_SG_REL_ BCM1 SG_ 1457 TSG_FlHz_HBFS_NTC_A 5000;
BA_REL_ "GenSigTimeoutTime" BU_SG_REL_ BCM1 SG_ 1457 TSG_FlHz_HBFS_FnAbbruchHzKreis_A 5000;
BA_REL_ "GenSigTimeoutTime" BU_SG_REL_ BCM1 SG_ 1457 TSG_FlHz_HBFS_NTC_B 5000;
BA_REL_ "GenSigTimeoutTime" BU_SG_REL_ BCM1 SG_ 1457 TSG_FlHz_HBFS_FnAbbruchHzKreis_B 5000;
BA_REL_ "GenSigTimeoutTime" BU_SG_REL_ BCM1 SG_ 974 HFS_Tuer_geoeffnet 1000;
BA_REL_ "GenSigTimeoutTime" BU_SG_REL_ BCM1 SG_ 974 HFS_TIG_betaetigt 1000;
BA_REL_ "GenSigTimeoutTime" BU_SG_REL_ BCM1 SG_ 974 HFS_FH_Oeffnung 1000;
BA_REL_ "GenSigTimeoutTime" BU_SG_REL_ BCM1 SG_ 974 ASW_Warnung_aktiv_HFS 1000;
BA_REL_ "GenSigTimeoutTime" BU_SG_REL_ BCM1 SG_ 974 HFS_Seitenrollo_hoch 1000;
BA_REL_ "GenSigTimeoutTime" BU_SG_REL_ BCM1 SG_ 974 HFS_Seitenrollo_tief 1000;
BA_REL_ "GenSigTimeoutTime" BU_SG_REL_ BCM1 SG_ 1458 TSG_FlHz_HFS_NTC_A 5000;
BA_REL_ "GenSigTimeoutTime" BU_SG_REL_ BCM1 SG_ 1458 TSG_FlHz_HFS_FnAbbruchHzKreis_A 5000;
BA_REL_ "GenSigTimeoutTime" BU_SG_REL_ BCM1 SG_ 1458 TSG_FlHz_HFS_NTC_B 5000;
BA_REL_ "GenSigTimeoutTime" BU_SG_REL_ BCM1 SG_ 1458 TSG_FlHz_HFS_FnAbbruchHzKreis_B 5000;
BA_REL_ "GenSigTimeoutTime" BU_SG_REL_ BCM1 SG_ 346 TSK_Status_PLA 1000;
BA_REL_ "GenSigTimeoutTime" BU_SG_REL_ BCM1 SG_ 346 TSK_aktives_System 1000;
BA_REL_ "GenSigTimeoutTime" BU_SG_REL_ BCM1 SG_ 346 TSK_Status_ARA 1000;
BA_REL_ "GenSigTimeoutTime" BU_SG_REL_ BCM1 SG_ 995 VS_VD_zu_ver 1000;
BA_REL_ "GenSigTimeoutTime" BU_SG_REL_ BCM1 SG_ 995 VS_VD_entriegelt 1000;
BA_REL_ "GenSigTimeoutTime" BU_SG_REL_ BCM1 SG_ 995 VS_VD_offen_ver 1000;
BA_REL_ "GenSigTimeoutTime" BU_SG_REL_ BCM1 SG_ 995 VS_VD_Bew_auf 1000;
BA_REL_ "GenSigTimeoutTime" BU_SG_REL_ BCM1 SG_ 995 VS_VD_Bew_zu 1000;
BA_REL_ "GenSigTimeoutTime" BU_SG_REL_ BCM1 SG_ 995 VS_Verdeck_Anf 1000;
BA_REL_ "GenSigTimeoutTime" BU_SG_REL_ BCM1 SG_ 995 VS_Hardtop 1000;
BA_REL_ "GenSigTimeoutTime" BU_SG_REL_ BCM1 SG_ 995 VS_VDKD_auf 1000;
BA_REL_ "GenSigTimeoutTime" BU_SG_REL_ BCM1 SG_ 995 VSG_Meldungen 1000;
BA_REL_ "GenSigTimeoutTime" BU_SG_REL_ BCM1 SG_ 1716 VIN_01_MUX 2000;
BA_REL_ "GenSigTimeoutTime" BU_SG_REL_ BCM1 SG_ 1716 VIN_4 2000;
BA_REL_ "GenSigTimeoutTime" BU_SG_REL_ BCM1 SG_ 1716 VIN_11 2000;
BA_REL_ "GenSigTimeoutTime" BU_SG_REL_ BCM1 SG_ 1716 VIN_5 2000;
BA_REL_ "GenSigTimeoutTime" BU_SG_REL_ BCM1 SG_ 1716 VIN_12 2000;
BA_REL_ "GenSigTimeoutTime" BU_SG_REL_ BCM1 SG_ 1716 VIN_6 2000;
BA_REL_ "GenSigTimeoutTime" BU_SG_REL_ BCM1 SG_ 1716 VIN_13 2000;
BA_REL_ "GenSigTimeoutTime" BU_SG_REL_ BCM1 SG_ 1716 VIN_7 2000;
BA_REL_ "GenSigTimeoutTime" BU_SG_REL_ BCM1 SG_ 1716 VIN_14 2000;
BA_REL_ "GenSigTimeoutTime" BU_SG_REL_ BCM1 SG_ 1716 VIN_1 2000;
BA_REL_ "GenSigTimeoutTime" BU_SG_REL_ BCM1 SG_ 1716 VIN_8 2000;
BA_REL_ "GenSigTimeoutTime" BU_SG_REL_ BCM1 SG_ 1716 VIN_15 2000;
BA_REL_ "GenSigTimeoutTime" BU_SG_REL_ BCM1 SG_ 1716 VIN_2 2000;
BA_REL_ "GenSigTimeoutTime" BU_SG_REL_ BCM1 SG_ 1716 VIN_9 2000;
BA_REL_ "GenSigTimeoutTime" BU_SG_REL_ BCM1 SG_ 1716 VIN_16 2000;
BA_REL_ "GenSigTimeoutTime" BU_SG_REL_ BCM1 SG_ 1716 VIN_3 2000;
BA_REL_ "GenSigTimeoutTime" BU_SG_REL_ BCM1 SG_ 1716 VIN_10 2000;
BA_REL_ "GenSigTimeoutTime" BU_SG_REL_ BCM1 SG_ 1716 VIN_17 2000;
BA_REL_ "GenSigTimeoutTime" BU_SG_REL_ BCM1 SG_ 1361 WFS_ID_Geb_autorisiert 2000;
BA_REL_ "GenSigTimeoutTime" BU_SG_REL_ BCM1 SG_ 2463978613 zFAS_Pilottaster_LED_Farbe_Anf 3200;
BA_REL_ "GenSigTimeoutTime" BU_SG_REL_ BCM1 SG_ 2463978613 zFAS_Pilottaster_LED_Modus_Anf 3200;
BA_REL_ "GenSigTimeoutTime" BU_SG_REL_ BCM1 SG_ 388 ZV_01_CRC 5000;
BA_REL_ "GenSigTimeoutTime" BU_SG_REL_ BCM1 SG_ 388 ZV_01_BZ 5000;
BA_REL_ "GenSigTimeoutTime" BU_SG_REL_ BCM1 SG_ 388 ZV_FT_verriegeln 5000;
BA_REL_ "GenSigTimeoutTime" BU_SG_REL_ BCM1 SG_ 388 ZV_FT_entriegeln 5000;
BA_REL_ "GenSigTimeoutTime" BU_SG_REL_ BCM1 SG_ 388 ZV_Softtouch_betaetigt 5000;
BA_REL_ "GenSigTimeoutTime" BU_SG_REL_ BCM1 SG_ 388 ZV_auf_FT 5000;
BA_REL_ "GenSigTimeoutTime" BU_SG_REL_ BCM1 SG_ 388 ZV_auf_BT 5000;
BA_REL_ "GenSigTimeoutTime" BU_SG_REL_ BCM1 SG_ 388 ZV_auf_Kessy 5000;
BA_REL_ "GenSigTimeoutTime" BU_SG_REL_ BCM1 SG_ 388 ZV_zu_Kessy 5000;
BA_REL_ "GenSigTimeoutTime" BU_SG_REL_ BCM1 SG_ 388 ZV_auf_Funk 5000;
BA_REL_ "GenSigTimeoutTime" BU_SG_REL_ BCM1 SG_ 388 ZV_zu_Funk 5000;
BA_REL_ "GenSigTimeoutTime" BU_SG_REL_ BCM1 SG_ 388 VIP_Sensor_betaetigt 5000;
BA_REL_ "GenSigTimeoutTime" BU_SG_REL_ BCM1 SG_ 388 ZV_zu_Zeitl_Nachverr 5000;
BA_REL_ "GenSigTimeoutTime" BU_SG_REL_ BCM1 SG_ 1411 BCM_Komfortfkt_Freigabe 2000;
BA_REL_ "GenSigTimeoutTime" BU_SG_REL_ BCM1 SG_ 1411 ZV_verriegelt_intern_ist 2000;
BA_REL_ "GenSigTimeoutTime" BU_SG_REL_ BCM1 SG_ 1411 ZV_verriegelt_extern_ist 2000;
BA_REL_ "GenSigTimeoutTime" BU_SG_REL_ BCM1 SG_ 1411 ZV_verriegelt_intern_soll 2000;
BA_REL_ "GenSigTimeoutTime" BU_SG_REL_ BCM1 SG_ 1411 ZV_verriegelt_extern_soll 2000;
BA_REL_ "GenSigTimeoutTime" BU_SG_REL_ BCM1 SG_ 1411 ZV_gesafet_extern_ist 2000;
BA_REL_ "GenSigTimeoutTime" BU_SG_REL_ BCM1 SG_ 1411 ZV_gesafet_extern_soll 2000;
BA_REL_ "GenSigTimeoutTime" BU_SG_REL_ BCM1 SG_ 1411 ZV_FT_offen 2000;
BA_REL_ "GenSigTimeoutTime" BU_SG_REL_ BCM1 SG_ 1411 ZV_BT_offen 2000;
BA_REL_ "GenSigTimeoutTime" BU_SG_REL_ BCM1 SG_ 1411 ZV_HFS_offen 2000;
BA_REL_ "GenSigTimeoutTime" BU_SG_REL_ BCM1 SG_ 1411 ZV_HBFS_offen 2000;
BA_REL_ "GenSigTimeoutTime" BU_SG_REL_ BCM1 SG_ 1411 ZV_HD_offen 2000;
BA_REL_ "GenSigTimeoutTime" BU_SG_REL_ BCM1 SG_ 1411 ZV_HS_offen 2000;
BA_REL_ "GenSigTimeoutTime" BU_SG_REL_ BCM1 SG_ 1411 DWA_aktiv 2000;
BA_REL_ "GenSigTimeoutTime" BU_SG_REL_ BCM1 SG_ 1411 ZV_Schluessel_Zugang 2000;
BA_REL_ "GenSigTimeoutTime" BU_SG_REL_ BCM1 SG_ 1411 ZV_ist_Zustand_verfuegbar 2000;
BA_REL_ "GenSigTimeoutTime" BU_SG_REL_ Gateway SG_ 1702 Wischer1_Wischgeschwindigkeit 5000;
BA_REL_ "GenSigTimeoutTime" BU_SG_REL_ Klima_MSB SG_ 976 FT_Tuer_geoeffnet 1000;
BA_REL_ "GenSigTimeoutTime" BU_SG_REL_ Klima_MSB SG_ 976 FT_FH_Oeffnung 1000;
BA_REL_ "GenSigTimeoutTime" BU_SG_REL_ Klima_MSB SG_ 1449 TSG_FlHz_FS_NTC_A 5000;
BA_REL_ "GenSigTimeoutTime" BU_SG_REL_ Klima_MSB SG_ 1449 TSG_FlHz_FS_FnAbbruchHzKreis_A 5000;
BA_REL_ "GenSigTimeoutTime" BU_SG_REL_ Klima_MSB SG_ 975 HBFS_Tuer_geoeffnet 1000;
BA_REL_ "GenSigTimeoutTime" BU_SG_REL_ Klima_MSB SG_ 975 HBFS_FH_Oeffnung 1000;
BA_REL_ "GenSigTimeoutTime" BU_SG_REL_ Klima_MSB SG_ 975 HBFS_Seitenrollo_hoch 1000;
BA_REL_ "GenSigTimeoutTime" BU_SG_REL_ Klima_MSB SG_ 975 HBFS_Seitenrollo_tief 1000;
BA_REL_ "GenSigTimeoutTime" BU_SG_REL_ Klima_MSB SG_ 1457 TSG_FlHz_HBFS_NTC_A 5000;
BA_REL_ "GenSigTimeoutTime" BU_SG_REL_ Klima_MSB SG_ 1457 TSG_FlHz_HBFS_FnAbbruchHzKreis_A 5000;
BA_REL_ "GenSigTimeoutTime" BU_SG_REL_ Klima_MSB SG_ 974 HFS_Tuer_geoeffnet 1000;
BA_REL_ "GenSigTimeoutTime" BU_SG_REL_ Klima_MSB SG_ 974 HFS_FH_Oeffnung 1000;
BA_REL_ "GenSigTimeoutTime" BU_SG_REL_ Klima_MSB SG_ 974 HFS_Seitenrollo_hoch 1000;
BA_REL_ "GenSigTimeoutTime" BU_SG_REL_ Klima_MSB SG_ 974 HFS_Seitenrollo_tief 1000;
BA_REL_ "GenSigTimeoutTime" BU_SG_REL_ Klima_MSB SG_ 1458 TSG_FlHz_HFS_NTC_A 5000;
BA_REL_ "GenSigTimeoutTime" BU_SG_REL_ Klima_MSB SG_ 1458 TSG_FlHz_HFS_FnAbbruchHzKreis_A 5000;
BA_REL_ "GenSigTimeoutTime" BU_SG_REL_ Klima_MSB SG_ 995 VS_VD_zu_ver 1000;
BA_REL_ "GenSigTimeoutTime" BU_SG_REL_ Klima_MSB SG_ 995 VS_VD_offen_ver 1000;
BA_REL_ "GenSigTimeoutTime" BU_SG_REL_ Klima_MSB SG_ 995 VS_VD_Zwischenposition 1000;
BA_REL_ "GenSigTimeoutTime" BU_SG_REL_ Klima_MSB SG_ 995 VS_VD_Bew_auf 1000;
BA_REL_ "GenSigTimeoutTime" BU_SG_REL_ Klima_MSB SG_ 995 VS_VD_Bew_zu 1000;
BA_REL_ "GenSigTimeoutTime" BU_SG_REL_ Klima_MSB SG_ 995 VS_Hardtop 1000;
BA_REL_ "GenSigTimeoutTime" BU_SG_REL_ Klima_MSB SG_ 995 VSG_Meldungen 1000;
BA_REL_ "GenSigTimeoutTime" BU_SG_REL_ Klima_MSB SG_ 1716 VIN_01_MUX 2000;
BA_REL_ "GenSigTimeoutTime" BU_SG_REL_ Klima_MSB SG_ 1716 VIN_4 2000;
BA_REL_ "GenSigTimeoutTime" BU_SG_REL_ Klima_MSB SG_ 1716 VIN_11 2000;
BA_REL_ "GenSigTimeoutTime" BU_SG_REL_ Klima_MSB SG_ 1716 VIN_5 2000;
BA_REL_ "GenSigTimeoutTime" BU_SG_REL_ Klima_MSB SG_ 1716 VIN_12 2000;
BA_REL_ "GenSigTimeoutTime" BU_SG_REL_ Klima_MSB SG_ 1716 VIN_6 2000;
BA_REL_ "GenSigTimeoutTime" BU_SG_REL_ Klima_MSB SG_ 1716 VIN_13 2000;
BA_REL_ "GenSigTimeoutTime" BU_SG_REL_ Klima_MSB SG_ 1716 VIN_7 2000;
BA_REL_ "GenSigTimeoutTime" BU_SG_REL_ Klima_MSB SG_ 1716 VIN_14 2000;
BA_REL_ "GenSigTimeoutTime" BU_SG_REL_ Klima_MSB SG_ 1716 VIN_1 2000;
BA_REL_ "GenSigTimeoutTime" BU_SG_REL_ Klima_MSB SG_ 1716 VIN_8 2000;
BA_REL_ "GenSigTimeoutTime" BU_SG_REL_ Klima_MSB SG_ 1716 VIN_15 2000;
BA_REL_ "GenSigTimeoutTime" BU_SG_REL_ Klima_MSB SG_ 1716 VIN_2 2000;
BA_REL_ "GenSigTimeoutTime" BU_SG_REL_ Klima_MSB SG_ 1716 VIN_9 2000;
BA_REL_ "GenSigTimeoutTime" BU_SG_REL_ Klima_MSB SG_ 1716 VIN_16 2000;
BA_REL_ "GenSigTimeoutTime" BU_SG_REL_ Klima_MSB SG_ 1716 VIN_3 2000;
BA_REL_ "GenSigTimeoutTime" BU_SG_REL_ Klima_MSB SG_ 1716 VIN_10 2000;
BA_REL_ "GenSigTimeoutTime" BU_SG_REL_ Klima_MSB SG_ 1716 VIN_17 2000;
BA_REL_ "GenSigTimeoutTime" BU_SG_REL_ Klima_MSB SG_ 1702 Wischer_vorne_aktiv 5000;
BA_REL_ "GenSigTimeoutTime" BU_SG_REL_ Klima_MSB SG_ 1702 Waschen_vorne_aktiv 5000;
BA_REL_ "GenSigTimeoutTime" BU_SG_REL_ Klima_MSB SG_ 1702 WWSs_01_upd 5000;
BA_REL_ "GenSigTimeoutTime" BU_SG_REL_ Klima_MSB SG_ 388 ZV_auf_Kessy 5000;
BA_REL_ "GenSigTimeoutTime" BU_SG_REL_ Klima_MSB SG_ 388 ZV_auf_Funk 5000;
BA_REL_ "GenSigTimeoutTime" BU_SG_REL_ Klima_MSB SG_ 1411 ZV_verriegelt_intern_ist 2000;
BA_REL_ "GenSigTimeoutTime" BU_SG_REL_ Klima_MSB SG_ 1411 ZV_verriegelt_extern_ist 2000;
BA_REL_ "GenSigTimeoutTime" BU_SG_REL_ Klima_MSB SG_ 1411 ZV_verriegelt_intern_soll 2000;
BA_REL_ "GenSigTimeoutTime" BU_SG_REL_ Klima_MSB SG_ 1411 ZV_verriegelt_extern_soll 2000;
BA_REL_ "GenSigTimeoutTime" BU_SG_REL_ Klima_MSB SG_ 1411 ZV_Schluessel_Zugang 2000;
BA_REL_ "GenSigTimeoutTime" BU_SG_REL_ Lift_VA SG_ 976 FT_Tuer_geoeffnet 1000;
BA_REL_ "GenSigTimeoutTime" BU_SG_REL_ VAS_L SG_ 976 FT_Tuer_geoeffnet 1000;
BA_REL_ "GenSigTimeoutTime" BU_SG_REL_ VAS_L SG_ 976 FT_verriegelt 1000;
BA_REL_ "GenSigTimeoutTime" BU_SG_REL_ VAS_L SG_ 976 FT_TAG_betaetigt 1000;
BA_REL_ "GenSigTimeoutTime" BU_SG_REL_ VAS_L SG_ 976 FT_TIG_betaetigt 1000;
BA_REL_ "GenSigTimeoutTime" BU_SG_REL_ VAS_L SG_ 975 HBFS_Tuer_geoeffnet 1000;
BA_REL_ "GenSigTimeoutTime" BU_SG_REL_ VAS_L SG_ 975 HBFS_verriegelt 1000;
BA_REL_ "GenSigTimeoutTime" BU_SG_REL_ VAS_L SG_ 975 HBFS_TAG_betaetigt 1000;
BA_REL_ "GenSigTimeoutTime" BU_SG_REL_ VAS_L SG_ 975 HBFS_TIG_betaetigt 1000;
BA_REL_ "GenSigTimeoutTime" BU_SG_REL_ VAS_L SG_ 974 HFS_Tuer_geoeffnet 1000;
BA_REL_ "GenSigTimeoutTime" BU_SG_REL_ VAS_L SG_ 974 HFS_verriegelt 1000;
BA_REL_ "GenSigTimeoutTime" BU_SG_REL_ VAS_L SG_ 974 HFS_TAG_betaetigt 1000;
BA_REL_ "GenSigTimeoutTime" BU_SG_REL_ VAS_L SG_ 974 HFS_TIG_betaetigt 1000;
BA_REL_ "GenSigTimeoutTime" BU_SG_REL_ VAS_L SG_ 2463978634 VAS_R_01_CRC 1000;
BA_REL_ "GenSigTimeoutTime" BU_SG_REL_ VAS_L SG_ 2463978634 VAS_R_01_BZ 1000;
BA_REL_ "GenSigTimeoutTime" BU_SG_REL_ VAS_L SG_ 2463978634 VAS_R_Bedien_Master 1000;
BA_REL_ "GenSigTimeoutTime" BU_SG_REL_ VAS_L SG_ 2463978634 VAS_R_Autobahnview_aktiv 1000;
BA_REL_ "GenSigTimeoutTime" BU_SG_REL_ VAS_L SG_ 2463978634 VAS_R_Parkview_aktiv 1000;
BA_REL_ "GenSigTimeoutTime" BU_SG_REL_ VAS_L SG_ 2463978634 VAS_R_Turnview_aktiv 1000;
BA_REL_ "GenSigTimeoutTime" BU_SG_REL_ VAS_L SG_ 2463978634 VAS_R_HMI_Aktiv 1000;
BA_REL_ "GenSigTimeoutTime" BU_SG_REL_ VAS_L SG_ 2463978634 VAS_R_SWA_HMI_Diagnose 1000;
BA_REL_ "GenSigTimeoutTime" BU_SG_REL_ VAS_L SG_ 2463978634 VAS_R_Fahrerwarnung 1000;
BA_REL_ "GenSigTimeoutTime" BU_SG_REL_ VAS_L SG_ 2463978634 VAS_R_Spiegelauswahl 1000;
BA_REL_ "GenSigTimeoutTime" BU_SG_REL_ VAS_L SG_ 2463978634 VAS_R_Verstell_Pos_X 1000;
BA_REL_ "GenSigTimeoutTime" BU_SG_REL_ VAS_L SG_ 2463978634 VAS_R_Heizung_Aktiv 1000;
BA_REL_ "GenSigTimeoutTime" BU_SG_REL_ VAS_L SG_ 2463978634 VAS_R_Verstell_Pos_Y 1000;
BA_REL_ "GenSigTimeoutTime" BU_SG_REL_ VAS_L SG_ 2463978634 VAS_R_Zoom_Level 1000;
BA_REL_ "GenSigTimeoutTime" BU_SG_REL_ VAS_L SG_ 2463978637 VAS_R_Zoom_Level_Req_L 5000;
BA_REL_ "GenSigTimeoutTime" BU_SG_REL_ VAS_L SG_ 2463978637 VAS_R_Dimmung_BAP_Status 5000;
BA_REL_ "GenSigTimeoutTime" BU_SG_REL_ VAS_L SG_ 2463978637 VAS_R_Betriebsstunden 5000;
BA_REL_ "GenSigTimeoutTime" BU_SG_REL_ VAS_L SG_ 2463978637 VAS_R_HBM 5000;
BA_REL_ "GenSigTimeoutTime" BU_SG_REL_ VAS_L SG_ 2463978637 VAS_R_Parkview_BAP_Status 5000;
BA_REL_ "GenSigTimeoutTime" BU_SG_REL_ VAS_L SG_ 2463978637 VAS_R_Display_Sync 5000;
BA_REL_ "GenSigTimeoutTime" BU_SG_REL_ VAS_L SG_ 2463978637 VAS_R_Turnview_BAP_Status 5000;
BA_REL_ "GenSigTimeoutTime" BU_SG_REL_ VAS_L SG_ 2463978637 VAS_R_Autobahnview_BAP_Status 5000;
BA_REL_ "GenSigTimeoutTime" BU_SG_REL_ VAS_L SG_ 2463978637 VAS_R_DefaultView 5000;
BA_REL_ "GenSigTimeoutTime" BU_SG_REL_ VAS_L SG_ 2463978637 VAS_R_Verstell_Pos_X_Req_L 5000;
BA_REL_ "GenSigTimeoutTime" BU_SG_REL_ VAS_L SG_ 2463978637 VAS_R_Dimmung 5000;
BA_REL_ "GenSigTimeoutTime" BU_SG_REL_ VAS_L SG_ 2463978637 VAS_R_Verstell_Pos_Y_Req_L 5000;
BA_REL_ "GenSigTimeoutTime" BU_SG_REL_ VAS_L SG_ 2463978637 VAS_R_PanAndZoom_Ctrl_Req_L 5000;
BA_REL_ "GenSigTimeoutTime" BU_SG_REL_ VAS_L SG_ 1702 Wischer_vorne_aktiv 5000;
BA_REL_ "GenSigTimeoutTime" BU_SG_REL_ VAS_L SG_ 1411 ZV_verriegelt_intern_ist 2000;
BA_REL_ "GenSigTimeoutTime" BU_SG_REL_ VAS_L SG_ 1411 ZV_verriegelt_extern_ist 2000;
BA_REL_ "GenSigTimeoutTime" BU_SG_REL_ VAS_R SG_ 976 FT_Tuer_geoeffnet 1000;
BA_REL_ "GenSigTimeoutTime" BU_SG_REL_ VAS_R SG_ 976 FT_verriegelt 1000;
BA_REL_ "GenSigTimeoutTime" BU_SG_REL_ VAS_R SG_ 976 FT_TAG_betaetigt 1000;
BA_REL_ "GenSigTimeoutTime" BU_SG_REL_ VAS_R SG_ 976 FT_TIG_betaetigt 1000;
BA_REL_ "GenSigTimeoutTime" BU_SG_REL_ VAS_R SG_ 975 HBFS_Tuer_geoeffnet 1000;
BA_REL_ "GenSigTimeoutTime" BU_SG_REL_ VAS_R SG_ 975 HBFS_verriegelt 1000;
BA_REL_ "GenSigTimeoutTime" BU_SG_REL_ VAS_R SG_ 975 HBFS_TAG_betaetigt 1000;
BA_REL_ "GenSigTimeoutTime" BU_SG_REL_ VAS_R SG_ 975 HBFS_TIG_betaetigt 1000;
BA_REL_ "GenSigTimeoutTime" BU_SG_REL_ VAS_R SG_ 974 HFS_Tuer_geoeffnet 1000;
BA_REL_ "GenSigTimeoutTime" BU_SG_REL_ VAS_R SG_ 974 HFS_verriegelt 1000;
BA_REL_ "GenSigTimeoutTime" BU_SG_REL_ VAS_R SG_ 974 HFS_TAG_betaetigt 1000;
BA_REL_ "GenSigTimeoutTime" BU_SG_REL_ VAS_R SG_ 974 HFS_TIG_betaetigt 1000;
BA_REL_ "GenSigTimeoutTime" BU_SG_REL_ VAS_R SG_ 2463978633 VAS_L_01_CRC 1000;
BA_REL_ "GenSigTimeoutTime" BU_SG_REL_ VAS_R SG_ 2463978633 VAS_L_01_BZ 1000;
BA_REL_ "GenSigTimeoutTime" BU_SG_REL_ VAS_R SG_ 2463978633 VAS_L_Bedien_Master 1000;
BA_REL_ "GenSigTimeoutTime" BU_SG_REL_ VAS_R SG_ 2463978633 VAS_L_Parkview_aktiv 1000;
BA_REL_ "GenSigTimeoutTime" BU_SG_REL_ VAS_R SG_ 2463978633 VAS_L_Autobahnview_aktiv 1000;
BA_REL_ "GenSigTimeoutTime" BU_SG_REL_ VAS_R SG_ 2463978633 VAS_L_Turnview_aktiv 1000;
BA_REL_ "GenSigTimeoutTime" BU_SG_REL_ VAS_R SG_ 2463978633 VAS_L_HMI_Aktiv 1000;
BA_REL_ "GenSigTimeoutTime" BU_SG_REL_ VAS_R SG_ 2463978633 VAS_L_SWA_HMI_Diagnose 1000;
BA_REL_ "GenSigTimeoutTime" BU_SG_REL_ VAS_R SG_ 2463978633 VAS_L_Texte 1000;
BA_REL_ "GenSigTimeoutTime" BU_SG_REL_ VAS_R SG_ 2463978633 VAS_L_Spiegelauswahl 1000;
BA_REL_ "GenSigTimeoutTime" BU_SG_REL_ VAS_R SG_ 2463978633 VAS_L_Verstell_Pos_X 1000;
BA_REL_ "GenSigTimeoutTime" BU_SG_REL_ VAS_R SG_ 2463978633 VAS_L_Heizung_Aktiv 1000;
BA_REL_ "GenSigTimeoutTime" BU_SG_REL_ VAS_R SG_ 2463978633 VAS_L_Verstell_Pos_Y 1000;
BA_REL_ "GenSigTimeoutTime" BU_SG_REL_ VAS_R SG_ 2463978633 VAS_L_Zoom_Level 1000;
BA_REL_ "GenSigTimeoutTime" BU_SG_REL_ VAS_R SG_ 2463978636 VAS_L_Zoom_Level_Req_R 5000;
BA_REL_ "GenSigTimeoutTime" BU_SG_REL_ VAS_R SG_ 2463978636 VAS_L_Dimmung_BAP_Anf 5000;
BA_REL_ "GenSigTimeoutTime" BU_SG_REL_ VAS_R SG_ 2463978636 VAS_L_Betriebsstunden 5000;
BA_REL_ "GenSigTimeoutTime" BU_SG_REL_ VAS_R SG_ 2463978636 VAS_L_HBM 5000;
BA_REL_ "GenSigTimeoutTime" BU_SG_REL_ VAS_R SG_ 2463978636 VAS_L_Parkview_BAP_Freigabe 5000;
BA_REL_ "GenSigTimeoutTime" BU_SG_REL_ VAS_R SG_ 2463978636 VAS_L_Display_Sync 5000;
BA_REL_ "GenSigTimeoutTime" BU_SG_REL_ VAS_R SG_ 2463978636 VAS_L_Turnview_BAP_Freigabe 5000;
BA_REL_ "GenSigTimeoutTime" BU_SG_REL_ VAS_R SG_ 2463978636 VAS_L_Autobahnview_BAP_Freigabe 5000;
BA_REL_ "GenSigTimeoutTime" BU_SG_REL_ VAS_R SG_ 2463978636 VAS_L_DefaultView 5000;
BA_REL_ "GenSigTimeoutTime" BU_SG_REL_ VAS_R SG_ 2463978636 VAS_L_Verstell_Pos_X_Req_R 5000;
BA_REL_ "GenSigTimeoutTime" BU_SG_REL_ VAS_R SG_ 2463978636 VAS_L_Dimmung 5000;
BA_REL_ "GenSigTimeoutTime" BU_SG_REL_ VAS_R SG_ 2463978636 VAS_L_Verstell_Pos_Y_Req_R 5000;
BA_REL_ "GenSigTimeoutTime" BU_SG_REL_ VAS_R SG_ 2463978636 VAS_L_PanAndZoom_Ctrl_Req_R 5000;
BA_REL_ "GenSigTimeoutTime" BU_SG_REL_ VAS_R SG_ 1702 Wischer_vorne_aktiv 5000;
BA_REL_ "GenSigTimeoutTime" BU_SG_REL_ VAS_R SG_ 1411 ZV_verriegelt_intern_ist 2000;
BA_REL_ "GenSigTimeoutTime" BU_SG_REL_ VAS_R SG_ 1411 ZV_verriegelt_extern_ist 2000;
VAL_ 976 FT_Tuer_geoeffnet 0 "geschlossen" 1 "Tuer_offen" ;
VAL_ 976 FT_verriegelt 0 "Init" 1 "verriegelt" ;
VAL_ 976 FT_gesafet 0 "Init" 1 "gesafet" ;
VAL_ 976 FT_Schluesselschalter_auf 0 "Init" 1 "Schluesselschalter_auf_betaetigt" ;
VAL_ 976 FT_Schluesselschalter_zu 1 "Schluesselschalter zu betaetigt" ;
VAL_ 976 FT_Unlock_Taster 0 "Init" 1 "Unlock_Taster_betaetigt" ;
VAL_ 976 FT_Lock_Taster 0 "Init" 1 "Lock_Taster_betaetigt" ;
VAL_ 976 FT_Sperrklinke 0 "Schloss_in_Vorraste_und_Hauptraste" 1 "Tuer_auf_oder_Tuer_Position_zwischen_Vor_und_Hauptraste" ;
VAL_ 976 FT_TAG_betaetigt 0 "nicht_betaetigt" 1 "betaetigt" ;
VAL_ 976 FT_TIG_betaetigt 0 "nicht_betaetigt" 1 "betaetigt" ;
VAL_ 976 FT_IRUE_Taste 0 "Init" 1 "IRUE_Taste_betaetigt" ;
VAL_ 976 FT_HD_Taste 0 "nicht_betaetigt" 1 "Heckdeckeltaste_betaetigt" ;
VAL_ 976 FT_TD_Taste_Fehler 0 "iO" 1 "defekt" ;
VAL_ 976 FT_TD_Taste 0 "Init" 1 "Tankdeckel_Taster_betaetigt" ;
VAL_ 976 SSR_Temp_Freigabe 0 "SSR_Deaktiviert" 1 "SSR_Freigegeben" ;
VAL_ 976 FT_HD_Taste_2 0 "Taste_nicht_gedrueckt" 1 "Taste_gedrueckt" ;
VAL_ 976 FT_TSG_hinten_verbaut 0 "nicht verbaut" 1 "verbaut" ;
VAL_ 976 FT_Sp_Blk_def 0 "iO" 1 "defekt" ;
VAL_ 976 FT_FH_S_ManHoch 0 "Init" 1 "FH_Schalter_man_hoch_betaetigt" ;
VAL_ 976 FT_FH_S_AutoHoch 0 "Init" 1 "FH_Schalter_auto_hoch_betaetigt" ;
VAL_ 976 FT_FH_S_ManTief 0 "Init" 1 "FH_Schalter_man_tief_betaetigt" ;
VAL_ 976 FT_FH_S_AutoTief 0 "Init" 1 "FH_Schalter_auto_tief_betaetigt" ;
VAL_ 976 FT_FH_Bew_hoch 0 "Init" 1 "FH_in_Bewegung_hoch" ;
VAL_ 976 FT_FH_Bew_tief 0 "Init" 1 "FH_in_Bewegung_tief" ;
VAL_ 976 FT_FH_Fang 0 "ausserhalb_Fangbereich" 1 "innerhalb_Fangbereich" ;
VAL_ 976 FT_FH_Block 0 "Init" 1 "Fenster_Block" ;
VAL_ 976 FT_FH_Thermo 0 "Init" 1 "Thermoschutz_aktiv" ;
VAL_ 976 FT_UEKB_aktiviert 0 "Init" 1 "UEKB_aktiv" ;
VAL_ 976 ASW_HMI_defekt 0 "iO" 1 "defekt" ;
VAL_ 976 FT_FH_normiert 0 "Init" 1 "Fenster_normiert" ;
VAL_ 976 FT_Schliesstaster 1 "Schliesstaster_betaetigt" ;
VAL_ 976 FT_Zuziehhilfe_aktiv 0 "Init" 1 "Zuziehilfe_aktiv" ;
VAL_ 976 FT_SP_ausgerastet 0 "Init" 1 "Spiegel_ausgerastet" ;
VAL_ 976 FT_SP_lr_aktiv 0 "Init" 1 "Spiegel_xAchse_aktiv" ;
VAL_ 976 FT_SP_ht_aktiv 0 "Init" 1 "Spiegel_yAchse_aktiv" ;
VAL_ 976 ASW_wakeup 0 "Sleep" 1 "Wakeup" ;
VAL_ 976 FT_Oben_Block_erw 0 "Fensterheber_nicht_in_Blockerwar" 1 "Fensterheber_in_Blockerwartung_o" ;
VAL_ 976 FT_Unten_Block_erw 0 "Fensterheber_nicht_in_Blockerwar" 1 "Fensterheber_in_Blockerwartung_u" ;
VAL_ 976 FT_Kisi_li_aktiv 0 "inaktiv" 1 "aktiv" ;
VAL_ 976 FT_Kisi_re_aktiv 0 "inaktiv" 1 "aktiv" ;
VAL_ 976 FT_Kisi_Taster_li 0 "nicht_betaetigt" 1 "betaetigt" ;
VAL_ 976 FT_Kisi_Taster_re 0 "nicht_betaetigt" 1 "betaetigt" ;
VAL_ 976 FT_BFS_Fond_Freigabe 0 "Init" 1 "Freigabe_fuer_Fondbedienung_BFS" ;
VAL_ 976 FT_Kisi_Fehler 0 "kein_Fehler" 1 "Fehler" ;
VAL_ 976 FT_Daemmglas 0 "Normalglas_verbaut" 1 "Daemmglas_verbaut" ;
VAL_ 976 FT_SP_Heizung_Status 0 "Init" 1 "Status_Spiegelheizung_ein" ;
VAL_ 976 ASW_Warnung_aktiv_FS 0 "nicht_angefordert" 1 "angefordert" ;
VAL_ 976 FT_FH_Pos_oben 1 "Scheibe oben (nach Absenken auf Position) " ;
VAL_ 976 FT_Tuerschloss_defekt 0 "Tuerschloss_funktionsfaehig" 1 "Tuerschloss_defekt" ;
VAL_ 976 FT_SWA_Taster 0 "Taster_nicht_betaetigt" 1 "Taster_betaetigt" ;
VAL_ 976 SWA_HMI_Diagnose 0 "kein_Fehler_erkannt" 1 "Fehler_Taster_erkannt" 2 "Fehler_LED_erkannt" 3 "Fehler_LED_und_Taster_erkannt" ;
VAL_ 976 FS_Status_eTAG 0 "Init" 1 "Griff_ausgefahren" 2 "Griff_eingefahren" 3 "Fehler" ;
VAL_ 1449 TSG_FlHz_FS_NTC_A 125 "Fehler_NTC_OpenLoad_KS_Plus" 126 "Fehler_NTC_Overload_KS_Minus" 127 "Init" ;
VAL_ 1449 TSG_FlHz_FS_FnAbbruchHzKreis_A 0 "OK" 1 "FunktionsAbbruch" ;
VAL_ 1449 TSG_FlHz_FS_NTC_B 125 "Fehler_NTC_OpenLoad_KS_Plus" 126 "Fehler_NTC_Overload_KS_Minus" 127 "Init" ;
VAL_ 1449 TSG_FlHz_FS_FnAbbruchHzKreis_B 0 "OK" 1 "FunktionsAbbruch" ;
VAL_ 975 HBFS_Tuer_geoeffnet 0 "geschlossen" 1 "offen" ;
VAL_ 975 HBFS_verriegelt 0 "nicht_verriegelt" 1 "verriegelt" ;
VAL_ 975 HBFS_gesafet 0 "nicht_gesafet" 1 "gesafet" ;
VAL_ 975 HBFS_Heckrollotaster_betaetigt 0 "keine_Verfahranweisung_in_Richtung_Hoch" 1 "In_Richtung_Hoch_Verfahren" ;
VAL_ 975 HBFS_Tuerschloss_defekt 0 "Tuerschloss_funktionsfaehig" 1 "Tuerschloss_defekt" ;
VAL_ 975 HBFS_Unlock_Taster 0 "nicht_betaetigt" 1 "betaetigt" ;
VAL_ 975 HBFS_Lock_Taster 0 "nicht_betaetigt" 1 "betaetigt" ;
VAL_ 975 HBFS_Sperrklinke 0 "Schloss_in_Vorraste_und_Hauptraste" 1 "Tuer_auf_oder_Tuer_Position_zwischen_Vor_und_Hauptraste" ;
VAL_ 975 HBFS_TAG_betaetigt 0 "nicht_betaetigt" 1 "betaetigt" ;
VAL_ 975 HBFS_TIG_betaetigt 0 "nicht_betaetigt" 1 "betaetigt" ;
VAL_ 975 HBFS_FH_S_HFS_AutoHoch 0 "keine_Bedienung" 1 "Automatiklauf_Angefordert" ;
VAL_ 975 HBFS_FH_S_HFS_AutoTief 0 "keine_Bedienung" 1 "Automatiklauf_Angefordert" ;
VAL_ 975 HBFS_FH_S_HFS_ManHoch 0 "keine_Bedienung" 1 "Manueller_Lauf_Angefordert" ;
VAL_ 975 HBFS_FH_S_HFS_ManTief 0 "keine_Bedienung" 1 "Manueller_Lauf_Angefordert" ;
VAL_ 975 HBFS_Tuer_Status 0 "Init" 1 "Tuer_geschlossen" 2 "Tuer_offen" 3 "Fehler" ;
VAL_ 975 HBFS_SAD_Schalter 0 "nicht_betaetigt" 5 "AUF_manuell" 6 "AUF_automatik" 7 "ZU_manuell" 8 "ZU_automatik" 13 "nicht_verfuegbar" 14 "Init" 15 "Fehler" ;
VAL_ 975 HBFS_FH_S_ManHoch 0 "nicht_betaetigt" 1 "betaetigt" ;
VAL_ 975 HBFS_FH_S_AutoHoch 0 "nicht_betaetigt" 1 "betaetigt" ;
VAL_ 975 HBFS_FH_S_ManTief 0 "nicht_betaetigt" 1 "betaetigt" ;
VAL_ 975 HBFS_FH_S_AutoTief 0 "nicht_betaetigt" 1 "betaetigt" ;
VAL_ 975 HBFS_FH_Bew_hoch 0 "inaktiv" 1 "aktiv" ;
VAL_ 975 HBFS_FH_Bew_tief 0 "inaktiv" 1 "aktiv" ;
VAL_ 975 HBFS_FH_Fang 0 "ausserhalb_Fangbereich" 1 "innerhalb_Fangbereich" ;
VAL_ 975 HBFS_FH_Block 0 "inaktiv" 1 "aktiv" ;
VAL_ 975 HBFS_FH_Thermo 0 "inaktiv" 1 "aktiv" ;
VAL_ 975 HBFS_UEKB_aktiviert 0 "inaktiv" 1 "aktiv" ;
VAL_ 975 HBFS_Tueroeffnen_Warnung 0 "Tuerwarnung_nicht_aktiv" 1 "Tuerwarnung_aktiv" ;
VAL_ 975 HBFS_FH_normiert 0 "inaktiv" 1 "aktiv" ;
VAL_ 975 ASW_Warnung_aktiv_HBFS 0 "nicht_angefordert" 1 "angefordert" ;
VAL_ 975 HBFS_Zuziehhilfe_aktiv 0 "Init" 1 "Zuziehhilfe_aktiv" ;
VAL_ 975 HBFS_Seitenrollo_hoch 1 "Seitenrollo_in_Bewegung_hoch" ;
VAL_ 975 HBFS_Seitenrollo_tief 0 "Init" 1 "Seitenrollo_in_Bewegung_tief" ;
VAL_ 975 HBFS_Status_KiSi 0 "inaktiv" 1 "aktiv" ;
VAL_ 975 SSR_HBFS_Pos_Unten 0 "SSR_Oben" 1 "SSR_Unten" ;
VAL_ 975 HBFS_Oben_Block_erw 0 "Fensterheber_nicht_in_Blockerwar" 1 "Fensterheber_in_Blockerwartung_o" ;
VAL_ 975 HBFS_Unten_Block_erw 0 "Fensterheber_nicht_in_Blockerwar" 1 "Fensterheber_in_Blockerwartung_u" ;
VAL_ 975 MTHBFS_M_Taste 0 "nicht_betaetigt" 1 "betaetigt" ;
VAL_ 975 MTHBFS_Pos1 0 "nicht_betaetigt" 1 "betaetigt" ;
VAL_ 975 MTHBFS_Pos2 0 "nicht_betaetigt" 1 "betaetigt" ;
VAL_ 975 MTHBFS_Pos3 0 "nicht_betaetigt" 1 "betaetigt" ;
VAL_ 975 HBFS_MRollo_Schalter 0 "nicht_betaetigt" 1 "ZU_manuell" 2 "ZU_automatik" 3 "AUF_manuell" 4 "AUF_automatik" 5 "nicht_verfuegbar" 6 "Init" 7 "Fehler" ;
VAL_ 975 HBFS_Lock_Taster_inv 0 "Lock Taster betätgit" 1 "Lock Taster nicht betätigt" ;
VAL_ 975 HBFS_Status_KiSi_inv 0 "aktiv" 1 "inaktiv" ;
VAL_ 975 HBFS_Status_eTAG 0 "Init" 1 "Griff_ausgefahren" 2 "Griff_eingefahren" 3 "Fehler" ;
VAL_ 975 HBFS_Tuer_Status_QBit 0 "Status_Tuerkontakt_sicher" 1 "Status_Tuerkontakt_unsicher" ;
VAL_ 975 HBFS_TIG_betaetigt_schliessen 0 "nicht_betaetigt" 1 "betaetigt" ;
VAL_ 1457 TSG_FlHz_HBFS_NTC_A 125 "Fehler_NTC_OpenLoad__KS_Plus" 126 "Fehler_NTC_Overload__KS_Minus" 127 "Init" ;
VAL_ 1457 TSG_FlHz_HBFS_FnAbbruchHzKreis_A 0 "OK" 1 "FunktionsAbbruch" ;
VAL_ 1457 TSG_FlHz_HBFS_NTC_B 125 "Fehler_NTC_OpenLoad__KS_Plus" 126 "Fehler_NTC_Overload__KS_Minus" 127 "Init" ;
VAL_ 1457 TSG_FlHz_HBFS_FnAbbruchHzKreis_B 0 "OK" 1 "FunktionsAbbruch" ;
VAL_ 974 HFS_Tuer_geoeffnet 0 "geschlossen" 1 "offen" ;
VAL_ 974 HFS_verriegelt 0 "nicht_verriegelt" 1 "verriegelt" ;
VAL_ 974 HFS_gesafet 0 "nicht_gesafet" 1 "gesafet" ;
VAL_ 974 HFS_Heckrollotaster_betaetigt 0 "keine_Verfahranweisung_in_Richtung_Hoch" 1 "In_Richtung_Hoch_Verfahren" ;
VAL_ 974 HFS_Tuerschloss_defekt 0 "Tuerschloss_funktionsfaehig" 1 "Tuerschloss_defekt" ;
VAL_ 974 HFS_Unlock_Taster 0 "nicht_betaetigt" 1 "betaetigt" ;
VAL_ 974 HFS_Lock_Taster 0 "nicht_betaetigt" 1 "betaetigt" ;
VAL_ 974 HFS_Sperrklinke 0 "Schloss_in_Vorraste_und_Hauptraste" 1 "Tuer_auf_oder_Tuer_Position_zwischen_Vor_und_Hauptraste" ;
VAL_ 974 HFS_TAG_betaetigt 0 "nicht_betaetigt" 1 "betaetigt" ;
VAL_ 974 HFS_TIG_betaetigt 0 "nicht_betaetigt" 1 "betaetigt" ;
VAL_ 974 HFS_FH_S_HBFS_AutoHoch 0 "keine_Bedienung" 1 "Automatiklauf_Angefordert" ;
VAL_ 974 HFS_FH_S_HBFS_AutoTief 0 "keine_Bedienung" 1 "Automatiklauf_Angefordert" ;
VAL_ 974 HFS_FH_S_HBFS_ManHoch 0 "keine_Bedienung" 1 "Manueller_Lauf_Angefordert" ;
VAL_ 974 HFS_FH_S_HBFS_ManTief 0 "keine_Bedienung" 1 "Manueller_Lauf_Angefordert" ;
VAL_ 974 HFS_Tuer_Status 0 "Init" 1 "Tuer_geschlossen" 2 "Tuer_offen" 3 "Fehler" ;
VAL_ 974 HFS_SAD_Schalter 0 "nicht_betaetigt" 5 "AUF_manuell" 6 "AUF_automatik" 7 "ZU_manuell" 8 "ZU_automatik" 13 "nicht_verfuegbar" 14 "Init" 15 "Fehler" ;
VAL_ 974 HFS_FH_S_ManHoch 0 "nicht_betaetigt" 1 "betaetigt" ;
VAL_ 974 HFS_FH_S_AutoHoch 0 "nicht_betaetigt" 1 "betaetigt" ;
VAL_ 974 HFS_FH_S_ManTief 0 "nicht_betaetigt" 1 "betaetigt" ;
VAL_ 974 HFS_FH_S_AutoTief 0 "nicht_betaetigt" 1 "betaetigt" ;
VAL_ 974 HFS_FH_Bew_hoch 0 "inaktiv" 1 "aktiv" ;
VAL_ 974 HFS_FH_Bew_tief 0 "inaktiv" 1 "aktiv" ;
VAL_ 974 HFS_FH_Fang 0 "ausserhalb_Fangbereich" 1 "innerhalb_Fangbereich" ;
VAL_ 974 HFS_FH_Block 0 "inaktiv" 1 "aktiv" ;
VAL_ 974 HFS_FH_Thermo 0 "inaktiv" 1 "aktiv" ;
VAL_ 974 HFS_UEKB_aktiviert 0 "inaktiv" 1 "aktiv" ;
VAL_ 974 HFS_Tueroeffnen_Warnung 0 "Tuerwarnung_nicht_aktiv" 1 "Tuerwarnung_aktiv" ;
VAL_ 974 HFS_FH_normiert 0 "inaktiv" 1 "aktiv" ;
VAL_ 974 ASW_Warnung_aktiv_HFS 0 "nicht_angefordert" 1 "angefordert" ;
VAL_ 974 HFS_Zuziehhilfe_aktiv 0 "Init" 1 "Zuziehhilfe_aktiv" ;
VAL_ 974 HFS_Seitenrollo_hoch 0 "Init" 1 "Seitenrollo_in_Bewegung_hoch" ;
VAL_ 974 HFS_Seitenrollo_tief 0 "Init" 1 "Seitenrollo_in_Bewegung_tief" ;
VAL_ 974 HFS_Status_KiSi 0 "inaktiv" 1 "aktiv" ;
VAL_ 974 SSR_HFS_Pos_Unten 0 "SSR_Oben" 1 "SSR_Unten" ;
VAL_ 974 HFS_Oben_Block_erw 0 "Fensterheber_nicht_in_Blockerwar" 1 "Fensterheber_in_Blockerwartung_o" ;
VAL_ 974 HFS_Unten_Block_erw 0 "Fensterheber_nicht_in_Blockerwar" 1 "Fensterheber_in_Blockerwartung_u" ;
VAL_ 974 MTHFS_M_Taste 0 "nicht_betaetigt" 1 "betaetigt" ;
VAL_ 974 MTHFS_Pos1 0 "nicht_betaetigt" 1 "betaetigt" ;
VAL_ 974 MTHFS_Pos2 0 "nicht_betaetigt" 1 "betaetigt" ;
VAL_ 974 MTHFS_Pos3 0 "nicht_betaetigt" 1 "betaetigt" ;
VAL_ 974 HFS_MRollo_Schalter 0 "nicht_betaetigt" 1 "ZU_manuell" 2 "ZU_automatik" 3 "AUF_manuell" 4 "AUF_automatik" 5 "nicht_verfuegbar" 6 "Init" 7 "Fehler" ;
VAL_ 974 HFS_Lock_Taster_inv 0 "Lock Taster betätgit" 1 "Lock Taster nicht betätigt" ;
VAL_ 974 HFS_Status_eTAG 0 "Init" 1 "Griff_ausgefahren" 2 "Griff_eingefahren" 3 "Fehler" ;
VAL_ 974 HFS_Tuer_Status_QBit 0 "Status_Tuerkontakt_sicher" 1 "Status_Tuerkontakt_unsicher" ;
VAL_ 974 HFS_TCR_Mode_aktiv 0 "TCR_Mode_deaktiv" 1 "TCR_Mode_aktiv" ;
VAL_ 1458 TSG_FlHz_HFS_NTC_A 125 "Fehler_NTC_OpenLoad__KS_Plus" 126 "Fehler_NTC_Overload__KS_Minus" 127 "Init" ;
VAL_ 1458 TSG_FlHz_HFS_FnAbbruchHzKreis_A 0 "OK" 1 "FunktionsAbbruch" ;
VAL_ 1458 TSG_FlHz_HFS_NTC_B 125 "Fehler_NTC_OpenLoad__KS_Plus" 126 "Fehler_NTC_Overload__KS_Minus" 127 "Init" ;
VAL_ 1458 TSG_FlHz_HFS_FnAbbruchHzKreis_B 0 "OK" 1 "FunktionsAbbruch" ;
VAL_ 346 MO_Anforderung_HMS 0 "keine_Anforderung" 1 "halten" 2 "parken" 3 "halten_Standby" 4 "anfahren" 5 "Loesen_ueber_Rampe" 7 "HMS_uebernehmen" ;
VAL_ 346 TSK_vMax_aktuell 254 "kein_Limit_aktiv" 255 "Init" ;
VAL_ 346 TSK_Status_EA 0 "Aus" 1 "Init_oder_nicht_verbaut" 3 "Aktiv" 4 "Uebertreten" 5 "Abschaltung_laeuft" 6 "Reversibel_aus" 7 "Fehler" ;
VAL_ 346 TSK_vMax_Fahrerassistenz 511 "Init_ungueltig_keine_Beschraenkung" ;
VAL_ 346 TSK_Einheit_vMax_Fahrerassistenz 0 "kmh" 1 "mph" ;
VAL_ 346 TSK_Status_PLA 0 "Aus_Funktionsbereit" 1 "Init_oder_nicht_verbaut" 2 "aktivierbar" 3 "aktiv" 5 "Abschaltung_laeuft" 6 "reversibel_aus" 7 "Fehler" ;
VAL_ 346 TSK_aktives_System 0 "keine_Funktion_aktiv" 1 "GRA_ACC" 2 "ARA" 3 "Speedlimiter" 4 "IPA" 5 "PLA" 6 "PEA_Ausrollassistent" 7 "EA" ;
VAL_ 346 TSK_erhoehter_Fahrwiderstand 0 "kein_erhoehter_Fahrwiderstand" 1 "erhoehter_Fahrwiderstand" ;
VAL_ 346 TSK_Anf_Antriebsmoment 0 "keine_Anforderung" 1 "Anforderung_aktiv" ;
VAL_ 346 TSK_Status_ARA 0 "Aus" 1 "Init_oder_nicht_verbaut" 2 "aktivierbar" 3 "aktiv" 5 "abschaltung_laeuft" 6 "reversibel_aus" 7 "Fehler" ;
VAL_ 346 TSK_Status_IPA 0 "Aus_Funktionsbereit" 1 "Init_oder_nicht_verbaut" 2 "aktivierbar" 3 "aktiv" 4 "Fahreruebernahme_angefordert" 5 "Abschaltung_laueft" 6 "reversibel_aus" 7 "Fehler" ;
VAL_ 2589283609 UGDO_LED_Code_01 0 "Init" 1 "LED_green_on" 2 "LED_yellow_on" 3 "LED_red_on" 4 "LED_green_flashing_with_10_Hz" 5 "LED_yellow_flashing_with_1_Hz" 16 "LED_flashing_off" 17 "LED_green_flashing_1_x_1_Hz" 18 "LED_green_flashing_2_x_1_Hz" 19 "LED_green_flashing_3_x_1_Hz" 20 "LED_green_flashing_4_x_1_Hz" 21 "LED_green_flashing_5_x_1_Hz" 22 "LED_green_flashing_6_x_1_Hz" 23 "LED_green_flashing_7_x_1_Hz" 24 "LED_green_flashing_8_x_1_Hz" 25 "LED_green_flashing_9_x_1_Hz" 26 "LED_green_flashing_10_x_1_Hz" 27 "LED_green_flashing_11_x_1_Hz" 28 "LED_green_flashing_12_x_1_Hz" 29 "LED_green_flashing_13_x_1_Hz" 30 "LED_green_flashing_14_x_1_Hz" ;
VAL_ 2589283609 UGDO_Function_01 0 "LED Function" 1 "Transceiver locked" 2 "reserviert" 3 "reserviert" 4 "Successful learned" 5 "reserviert" 6 "Timeout learning" 7 "Fehler" ;
VAL_ 2589283609 UGDO_Failure_Antenne 0 "normal" 1 "Fehler" ;
VAL_ 2589283609 UGDO_Failure_Codierung 0 "normal" 1 "Fehler" ;
VAL_ 2589283609 UGDO_Failure_Hardware 0 "normal" 1 "Fehler" ;
VAL_ 2589283609 UGDO_ResponseError 0 "normal" 1 "Fehler" ;
VAL_ 2589283609 UGDO_Channel_1 0 "not_trained" 1 "trained" ;
VAL_ 2589283609 UGDO_Channel_2 0 "not_trained" 1 "trained" ;
VAL_ 2589283609 UGDO_Channel_3 0 "not_trained" 1 "trained" ;
VAL_ 2589283609 UGDO_Channel_4 0 "not_trained" 1 "trained" ;
VAL_ 2589283609 UGDO_Channel_5 0 "not_trained" 1 "trained" ;
VAL_ 2589283609 UGDO_Channel_6 0 "not_trained" 1 "trained" ;
VAL_ 2589283609 UGDO_Channel_7 0 "not_trained" 1 "trained" ;
VAL_ 2589283609 UGDO_Channel_8 0 "not_trained" 1 "trained" ;
VAL_ 2589283609 UGDO_Channel_9 0 "not_trained" 1 "trained" ;
VAL_ 2589283609 UGDO_Channel_10 0 "not_trained" 1 "trained" ;
VAL_ 2589283609 UGDO_Channel_11 0 "not_trained" 1 "trained" ;
VAL_ 2589283609 UGDO_Channel_12 0 "not_trained" 1 "trained" ;
VAL_ 2589283609 UGDO_Channel_13 0 "not_trained" 1 "trained" ;
VAL_ 2589283609 UGDO_Channel_14 0 "not_trained" 1 "trained" ;
VAL_ 2589283609 UGDO_Channel_15 0 "not_trained" 1 "trained" ;
VAL_ 2589283609 UGDO_DoorState 0 "idle" 1 "move" 2 "open" 3 "close" 4 "movement_stopped_stop_movement" 5 "no_com_door_out_of_reach" 6 "communication_error" ;
VAL_ 1718 UH_Typ 0 "undefiniert" 1 "Quarzuhr" 2 "DCF" 3 "GPS" ;
VAL_ 1718 UH_DLS 0 "Winterzeit" 1 "Sommerzeit" ;
VAL_ 1718 UH_Monat 0 "Init" 14 "Relatives_Datum" 15 "Fehler" ;
VAL_ 1718 UH_Tag 0 "Init" ;
VAL_ 2463978633 VAS_L_Bedien_Master 0 "Bedien_Slave" 1 "Bedien_Master" ;
VAL_ 2463978633 VAS_L_Parkview_aktiv 0 "Parkview_nicht_aktiv" 1 "Parkview_aktiv" ;
VAL_ 2463978633 VAS_L_Autobahnview_aktiv 0 "Autobahnview_nicht_aktiv" 1 "Autobahnview_aktiv" ;
VAL_ 2463978633 VAS_L_Turnview_aktiv 0 "Turnview_nicht_aktiv" 1 "Turnview_aktiv" ;
VAL_ 2463978633 VAS_L_HMI_Aktiv 0 "HMI_Inaktiv" 1 "HMI_Aktiv" ;
VAL_ 2463978633 VAS_L_SWA_HMI_Diagnose 0 "kein_Fehler_erkannt" 1 "Fehler_erkannt" ;
VAL_ 2463978633 VAS_L_Texte 0 "keine_Stoerung" 1 "Kameras_verschmutzt" 2 "Systemstoerung_links" 3 "Systemstoerung_rechts" 4 "allgemeine_Systemstoerung" 7 "Init" ;
VAL_ 2463978633 VAS_L_Spiegelauswahl 0 "Spiegel_links" 1 "Spiegel_rechts" ;
VAL_ 2463978633 VAS_L_Verstell_Pos_X 511 "Fehler" ;
VAL_ 2463978633 VAS_L_Heizung_Aktiv 127 "Fehler" ;
VAL_ 2463978633 VAS_L_Verstell_Pos_Y 511 "Fehler" ;
VAL_ 2463978633 VAS_L_Zoom_Level 127 "Fehler" ;
VAL_ 2463978636 VAS_L_Zoom_Level_Req_R 255 "Fehler" ;
VAL_ 2463978636 VAS_L_Dimmung_BAP_Anf 254 "Init" 255 "Fehler" ;
VAL_ 2463978636 VAS_L_Betriebsstunden 255 "Init" ;
VAL_ 2463978636 VAS_L_HBM 0 "deaktiv" 1 "aktiv" ;
VAL_ 2463978636 VAS_L_Parkview_BAP_Freigabe 0 "BAP_Parkview_gesperrt" 1 "BAP_Parkview_freigegeben" ;
VAL_ 2463978636 VAS_L_Display_Sync 0 "Init" 1 "Display_Startup" 2 "Display_Shutdown" 3 "Fehler" ;
VAL_ 2463978636 VAS_L_Turnview_BAP_Freigabe 0 "BAP_Turnview_gesperrt" 1 "BAP_Turnview_freigegeben" ;
VAL_ 2463978636 VAS_L_Autobahnview_BAP_Freigabe 0 "BAP_Autobahnview_gesperrt" 1 "BAP_Autobahnview_freigegeben" ;
VAL_ 2463978636 VAS_L_DefaultView 0 "nicht_aktiv" 1 "aktiv" ;
VAL_ 2463978636 VAS_L_Verstell_Pos_X_Req_R 511 "Fehler" ;
VAL_ 2463978636 VAS_L_Dimmung 126 "Init" 127 "Fehler" ;
VAL_ 2463978636 VAS_L_Verstell_Pos_Y_Req_R 511 "Fehler" ;
VAL_ 2463978636 VAS_L_PanAndZoom_Ctrl_Req_R 0 "Init" ;
VAL_ 2463978634 VAS_R_Bedien_Master 0 "Bedien_Slave" 1 "Bedien_Master" ;
VAL_ 2463978634 VAS_R_Autobahnview_aktiv 0 "Autobahnview_nicht_aktiv" 1 "Autobahnview_aktiv" ;
VAL_ 2463978634 VAS_R_Parkview_aktiv 0 "Parkview_nicht_aktiv" 1 "Parkview_aktiv" ;
VAL_ 2463978634 VAS_R_Turnview_aktiv 0 "Turnview_nicht_aktiv" 1 "Turnview_aktiv" ;
VAL_ 2463978634 VAS_R_HMI_Aktiv 0 "HMI_Inaktiv" 1 "HMI_Aktiv" ;
VAL_ 2463978634 VAS_R_SWA_HMI_Diagnose 0 "kein_Fehler_erkannt" 1 "Fehler_erkannt" ;
VAL_ 2463978634 VAS_R_Fahrerwarnung 0 "keine_Stoerung" 1 "Kameras_verschmutzt" 2 "Systemstoerung_links" 3 "Systemstoerung_rechts" 4 "allgemeine_Systemstoerung" 7 "Init" ;
VAL_ 2463978634 VAS_R_Spiegelauswahl 0 "Spiegel_links" 1 "Spiegel_rechts" ;
VAL_ 2463978634 VAS_R_Verstell_Pos_X 511 "Fehler" ;
VAL_ 2463978634 VAS_R_Heizung_Aktiv 127 "Fehler" ;
VAL_ 2463978634 VAS_R_Verstell_Pos_Y 511 "Fehler" ;
VAL_ 2463978634 VAS_R_Zoom_Level 127 "Fehler" ;
VAL_ 2463978637 VAS_R_Zoom_Level_Req_L 255 "Fehler" ;
VAL_ 2463978637 VAS_R_Dimmung_BAP_Status 254 "Init" 255 "Fehler" ;
VAL_ 2463978637 VAS_R_Betriebsstunden 255 "Init" ;
VAL_ 2463978637 VAS_R_HBM 0 "deaktiv" 1 "aktiv" ;
VAL_ 2463978637 VAS_R_Parkview_BAP_Status 0 "BAP_Parkview_deaktiv" 1 "BAP_Parkview_aktiv" ;
VAL_ 2463978637 VAS_R_Display_Sync 0 "Init" 1 "Display_Startup" 2 "Display_Shutdown" 3 "Fehler" ;
VAL_ 2463978637 VAS_R_Turnview_BAP_Status 0 "BAP_Turnview_deaktiv" 1 "BAP_Turnview_aktiv" ;
VAL_ 2463978637 VAS_R_Autobahnview_BAP_Status 0 "BAP_Autobahnview_deaktiv" 1 "BAP_Autobahnview_aktiv" ;
VAL_ 2463978637 VAS_R_DefaultView 0 "nicht_aktiv" 1 "aktiv" ;
VAL_ 2463978637 VAS_R_Verstell_Pos_X_Req_L 511 "Fehler" ;
VAL_ 2463978637 VAS_R_Dimmung 126 "Init" 127 "Fehler" ;
VAL_ 2463978637 VAS_R_Verstell_Pos_Y_Req_L 511 "Fehler" ;
VAL_ 2463978637 VAS_R_PanAndZoom_Ctrl_Req_L 0 "Init" ;
VAL_ 995 VS_VD_zu_ver 1 "Zustand des Verdecks verriegelt und geschlossen" ;
VAL_ 995 VS_VD_entriegelt 0 "Init" 1 "Zustand_des_Verdeck_entriegelt" ;
VAL_ 995 VS_VD_offen_ver 0 "Init" 1 "Verdeck_verriegelt_und_offen" ;
VAL_ 995 VS_VD_Zwischenposition 0 "Init" 1 "Verdeck_in_Zwischenposition" ;
VAL_ 995 VS_VD_Bew_auf 1 "Verdeck in Bewegung auf" ;
VAL_ 995 VS_VD_Bew_zu 1 "Verdeck in Bewegung zu" ;
VAL_ 995 VS_Verdeck_Anf 0 "init_nicht_aktiv" 1 "aktiv" ;
VAL_ 995 VS_Hardtop 0 "Init" 1 "Hardtop_montiert" ;
VAL_ 995 VS_VD_Fehler 0 "Init" 1 "Fehlerzustand Verdeck" ;
VAL_ 995 VS_Lampe_Blk 0 "Kontrollleuchte_inaktiv" 1 "Kontrollleuchte_aktiv" ;
VAL_ 995 VS_HD_sperren 0 "HD Entriegelung freigegeben" 1 "HD Entriegelung gesperrt" ;
VAL_ 995 VS_HHS_enable 0 "Init" 1 "Freigabe HHS" ;
VAL_ 995 VD_SpannungsAnf 0 "keine_Anforderung" 1 "Anforderung_Stufe1" 2 "Anforderung_Stufe2" 3 "Anforderung_Stufe3" ;
VAL_ 995 VS_VDKD_auf 0 "VDKD_nicht_vollst_auf" 1 "VDKD_vollstaendig_auf" ;
VAL_ 995 VS_FS_AutoHoch 0 "Keine_Verfahranforderung" 1 "Automatischer_Hochlauf" ;
VAL_ 995 VS_FS_AutoTief 0 "Keine_Verfahranforderung" 1 "Automatischer_Tieflauf" ;
VAL_ 995 VS_FS_ManHoch 0 "Keine_Verfahranforderung" 1 "Manueller_Hochlauf" ;
VAL_ 995 VS_FS_ManTief 0 "Keine_Verfahranforderung" 1 "Manueller_Tieflauf" ;
VAL_ 995 VS_BFS_AutoHoch 0 "Keine_Verfahranforderung" 1 "Automatischer_Hochlauf" ;
VAL_ 995 VS_BFS_AutoTief 0 "Keine_Verfahranforderung" 1 "Automatischer_Tieflauf" ;
VAL_ 995 VS_BFS_ManHoch 0 "Keine_Verfahranforderung" 1 "Manueller_Hochlauf" ;
VAL_ 995 VS_BFS_ManTief 0 "Keine_Verfahranforderung" 1 "Manueller_Tieflauf" ;
VAL_ 995 VS_HFS_AutoHoch 0 "Keine_Verfahranforderung" 1 "Automatischer_Hochlauf" ;
VAL_ 995 VS_HFS_AutoTief 0 "Keine_Verfahranforderung" 1 "Automatischer_Tieflauf" ;
VAL_ 995 VS_HFS_ManHoch 0 "Keine_Verfahranforderung" 1 "Manueller_Hochlauf" ;
VAL_ 995 VS_HFS_ManTief 0 "Keine_Verfahranforderung" 1 "Manueller_Tieflauf" ;
VAL_ 995 VS_HBFS_AutoHoch 0 "Keine_Verfahranforderung" 1 "Automatischer_Hochlauf" ;
VAL_ 995 VS_HBFS_AutoTief 0 "Keine_Verfahranforderung" 1 "Automatischer_Tieflauf" ;
VAL_ 995 VS_HBFS_ManHoch 0 "Keine_Verfahranforderung" 1 "Manueller_Hochlauf" ;
VAL_ 995 VS_HBFS_ManTief 0 "Keine_Verfahranforderung" 1 "Manueller_Tieflauf" ;
VAL_ 995 VS_FH_FT_Langhub 0 "Init" ;
VAL_ 995 VS_Windschott_nicht_abgelegt 0 "inaktiv" 1 "aktiv" ;
VAL_ 995 VS_FH_BT_Langhub 0 "Init" ;
VAL_ 995 VS_FH_HFS_Langhub 0 "Init" ;
VAL_ 995 VS_Heckschloss_auf 0 "kein_Oeffnen" 1 "Heckschloss_oeffnen" ;
VAL_ 995 VS_FH_HBFS_Langhub 0 "Init" ;
VAL_ 995 VSG_Meldungen 0 "keine_Meldung" ;
VAL_ 995 VS_StartStopp_Info 0 "Stoppfreigabe" 1 "Stoppverbot" 2 "Startanforderung" 3 "Fehler" ;
VAL_ 1361 WFS_Schluessel_Fahrberecht 0 "kein authorisierter Schluessel erkannt" 1 "aktive_Funkschluessel_Nr_01" 2 "aktive_Funkschluessel_Nr_02" 3 "aktive_Funkschluessel_Nr_03" 4 "aktive_Funkschluessel_Nr_04" 5 "aktive_Funkschluessel_Nr_05" 6 "aktive_Funkschluessel_Nr_06" 7 "aktive_Funkschluessel_Nr_07" 8 "aktive_Funkschluessel_Nr_08" 9 "ungueltig_09" 10 "ungueltig_10" 11 "ungueltig_11" 12 "ungueltig_12" 13 "ungueltig_13" 14 "ungueltig_14" 15 "digitaler_Schluessel_aktiv" ;
VAL_ 1361 WFS_ID_Geb_autorisiert 0 "Schluessel_nicht_authorisiert" 1 "Schluessel_authorisiert" ;
VAL_ 1361 WFS_ID_Geb_autorisiert_in_Kl15 0 "nicht_authorisiert_in_Kl15" 1 "authorisiert_in_Kl15" ;
VAL_ 1361 WFS_ID_Geb_steckt 0 "kein_Schluessel_im_Zuendschloss" 1 " Schluessel steckt im Zuendschloss" ;
VAL_ 1361 WFS_Safe 0 "Init" 1 "WFS nicht deaktiviert" ;
VAL_ 1361 WFS_LZ 0 "nicht def." 1 "LZ 1" 2 "LZ 2" 3 "LZ 3" ;
VAL_ 1361 WFS_ELV_authorisiert 0 "ELV_nicht_authorisiert" 1 "ELV_authorisiert" ;
VAL_ 1361 WFS_LF_Aktiv 0 "Funktempfang_nicht_aktiv" 1 "LF_Funkempfang_aktiv" ;
VAL_ 1361 WFS_Betrieb_Lesespule 0 "keine_Schluesselkomm_Lesespule" 1 "Schluesselkomm_Lesespule" ;
VAL_ 1361 WFS_Klemmenfreigabe 0 "keine_Freigabe" 1 "Freigabe" ;
VAL_ 1361 WFS_Fahrerhinweise 0 "Keine_Anzeigeanforderung" 1 "Schuessel_Auth_niO" 2 "Notlauf_aktiv" 3 "Schluessel_Kessy_nicht_gefunden" ;
VAL_ 1361 WFS_Parken_Status 0 "Limitierung_inaktiv" 1 "Limitierung_aktiv" 2 "Abbruch" ;
VAL_ 1702 Wischer_vorne_aktiv 0 "Init" 1 "Wischer_vorne_laeuft" ;
VAL_ 1702 Waschen_vorne_aktiv 0 "inaktiv" 1 "Waschen_aktiv" ;
VAL_ 1702 Wischer_vorne_Normal 1 "Wischer Front normal aktiv" ;
VAL_ 1702 Wischer_vorne_Schnell 1 "Wischer vorne schnell aktiv" ;
VAL_ 1702 Wischer_vorne_Parklage 0 "Wischer_Front_nicht_in_Parklage" 1 "Wischer_Front_in_Parklage__Initialzustand" ;
VAL_ 1702 Wischer_vorne_defekt 0 "Init" 1 "Wischer vorne defekt" ;
VAL_ 1702 Wischer_vorne_blockiert 1 "Wischer vorne blockiert" ;
VAL_ 1702 Wischer1_Wischgeschwindigkeit 0 "0 U/min" 62 "Init" 63 "Fehler" ;
VAL_ 1702 BCM1_SRA_aktiv 0 "nicht aktiv" 1 "aktiv" ;
VAL_ 1702 Heckwischer_Anforderung 0 "Aus" 1 "Ein" ;
VAL_ 1702 WWSs_01_upd 0 "nicht_aktuell" 1 "aktuell" ;
VAL_ 1702 Wischer_Anzeigetext 0 "keine_Anzeige" 1 "Hinweis_Service_Position" 2 "void" 3 "void" ;
VAL_ 2463978613 zFAS_Pilottaster_LED_Farbe_Anf 0 "keine_Anforderung" 1 "Farbe1" 2 "Farbe2" 3 "Farbe3" ;
VAL_ 2463978613 zFAS_Pilottaster_LED_Modus_Anf 0 "keine_Anforderung" 1 "Sonderfunktion_ein" ;
VAL_ 2463978613 zFAS_Blinker_li 0 "keine_Anforderung" 1 "Blinker_links_aktivieren" ;
VAL_ 2463978613 zFAS_Blinker_re 0 "keine_Anforderung" 1 "Blinker_rechts_aktivieren" ;
VAL_ 388 ZV_FT_verriegeln 0 "FT_nicht_verriegeln" 1 "FT_verriegeln" ;
VAL_ 388 ZV_FT_entriegeln 0 "FT_nicht_entriegeln" 1 "FT_entriegeln" ;
VAL_ 388 ZV_BT_verriegeln 0 "BT_nicht_verriegeln" 1 "BT_verriegeln" ;
VAL_ 388 ZV_BT_entriegeln 0 "BT_nicht_entriegeln" 1 "BT_ist_zu_entriegeln" ;
VAL_ 388 ZV_HFS_verriegeln 0 "inaktiv" 1 "aktiv" ;
VAL_ 388 ZV_HFS_entriegeln 0 "inaktiv" 1 "aktiv" ;
VAL_ 388 ZV_HBFS_verriegeln 0 "inaktiv" 1 "aktiv" ;
VAL_ 388 ZV_HBFS_entriegeln 0 "inaktiv" 1 "aktiv" ;
VAL_ 388 ZV_zentral_safen 0 "nicht_safen" 1 "Befehl_zentral_safen" ;
VAL_ 388 ZV_zentral_entsafen 0 "Init" 1 "Befehl_zentral_entsafen" ;
VAL_ 388 ZV_Spg_Anklappen 0 "inaktiv" 1 "aktiv" ;
VAL_ 388 ZV_Softtouch_betaetigt 0 "Softtouch_nicht_betaetigt" 1 "Softtouch_betaetigt" ;
VAL_ 388 ZV_LED_Steuerung 0 "LED_aus" 1 "LED_ein" ;
VAL_ 388 ZV_LED_Uebernahme 0 "Init" 1 "TSG_uebernimmt_LED_Steuerung" ;
VAL_ 388 ZV_auf_FT 0 "nicht_betaetigt" 1 "betaetigt" ;
VAL_ 388 ZV_zu_FT 0 "nicht_betaetigt" 1 "betaetigt" ;
VAL_ 388 ZV_auf_BT 0 "nicht_betaetigt" 1 "betaetigt" ;
VAL_ 388 ZV_zu_BT 0 "nicht_betaetigt" 1 "betaetigt" ;
VAL_ 388 ZV_auf_Funk 0 "nicht_betaetigt" 1 "betaetigt" ;
VAL_ 388 ZV_zu_Funk 0 "nicht_betaetigt" 1 "betaetigt" ;
VAL_ 388 VIP_Sensor_betaetigt 0 "Heckentr_VIP_nicht_angefordert" 1 "Heckentr_VIP_angefordert" ;
VAL_ 388 VIP_Freigabe 0 "keine_Freigabe" 1 "Freigabe" ;
VAL_ 388 ZV_zu_Zeitl_Nachverr 0 "Init" 1 "Nachverriegeln" ;
VAL_ 388 ZV_HSK_entriegeln 0 "Handschuhkasten nicht entriegeln" 1 "Handschuhkasten entriegeln" ;
VAL_ 388 ZV_HSK_verriegeln 0 "Handschuhkasten nicht verriegeln" 1 "Handschuhkasten_verriegelt" ;
VAL_ 388 ZV_Verdeck_zu 0 "inaktiv" 1 "aktiv" ;
VAL_ 388 ZV_Verdeck_auf 0 "inaktiv" 1 "aktiv" ;
VAL_ 388 FH_FT_hoch 0 "keine_Anforderung" 1 "FT_hoch" ;
VAL_ 388 FH_FT_tief 0 "keine_Anforderung" 1 "FT_tief" ;
VAL_ 388 FH_BT_hoch 0 "keine_Anforderung" 1 "BT_hoch" ;
VAL_ 388 FH_BT_tief 0 "keine_Anforderung" 1 "BT_tief" ;
VAL_ 388 FH_HFS_hoch 0 "inaktiv" 1 "aktiv" ;
VAL_ 388 FH_HFS_tief 0 "inaktiv" 1 "aktiv" ;
VAL_ 388 FH_HBFS_hoch 0 "inaktiv" 1 "aktiv" ;
VAL_ 388 FH_HBFS_tief 0 "inaktiv" 1 "aktiv" ;
VAL_ 388 BCM_Spg_Synchron 0 "inaktiv" 1 "aktiv" ;
VAL_ 388 BCM_BF_Spg_Absenkung 0 "inaktiv" 1 "aktiv" ;
VAL_ 388 ZV_entriegeln_Anf 0 "nicht_betaetigt" 1 "betaetigt" ;
VAL_ 388 ZV_auto_Ansteuerung 0 "Kein_Autolock_Unlock" 1 "Autolock_Unlock" ;
VAL_ 1411 BCM_FH_Freigabe 1 "Funktionsfreigabe Fensterheber" ;
VAL_ 1411 BCM_Komfortfkt_Freigabe 0 "Komfortfunktion gesperrt" 1 "globale Freigabe der Komfortfunktion erteilt" ;
VAL_ 1411 BCM_HSK_Freigabe 0 "erlauben" 1 "sperren" ;
VAL_ 1411 BCM_Verdeck_Freigabe 0 "Verdeckbetrieb nicht erlaubt" 1 "Verdeckbetrieb erlaubt" ;
VAL_ 1411 ZV_verriegelt_intern_ist 1 "Fahrzeug innen verriegelt; Istzustand" ;
VAL_ 1411 ZV_verriegelt_extern_ist 1 "Fahrzeug_aussen_verriegelt_Istzustand" ;
VAL_ 1411 ZV_verriegelt_intern_soll 1 "Fahrzeug verriegelt intern; Sollzusstand" ;
VAL_ 1411 ZV_verriegelt_extern_soll 1 "Fahrzeug verriegelt extern; Sollzusstand" ;
VAL_ 1411 ZV_gesafet_extern_ist 1 "Fahrzeug aussen gesafet; Istzustand" ;
VAL_ 1411 ZV_gesafet_extern_soll 1 "Fahrzeug_aussen_gesafet_Sollzustand" ;
VAL_ 1411 ZV_Einzeltuerentriegelung 1 "Fahrzeug an Einzeltuer entriegelt" ;
VAL_ 1411 ZV_Heckeinzelentriegelung 1 "Heckdeckeleinzelentriegelung" ;
VAL_ 1411 ZV_FT_offen 0 "FT_geschlossen" 1 "FT_geoeffnet" ;
VAL_ 1411 ZV_BT_offen 0 "BT_geschlossen" 1 "BT_geoeffnet" ;
VAL_ 1411 ZV_HFS_offen 0 "geschlossen" 1 "offen" ;
VAL_ 1411 ZV_HBFS_offen 0 "geschlossen" 1 "offen" ;
VAL_ 1411 ZV_HD_offen 1 "Heckdeckel_auf" ;
VAL_ 1411 ZV_HS_offen 0 "Heckscheibe_geschlossen" 1 "Heckscheibe auf" ;
VAL_ 1411 IRUE_aktiv 0 "unscharf" 1 "scharf" ;
VAL_ 1411 DWA_aktiv 0 "unscharf" 1 "scharf" ;
VAL_ 1411 HD_Hauptraste 0 "geschlossen" 1 "offen" ;
VAL_ 1411 HD_Vorraste 0 "geschlossen" 1 "offen" ;
VAL_ 1411 FFB_CarFinder 0 "nicht aktiv" 1 "aktiv" ;
VAL_ 1411 FFB_Komfortoeffnen 0 "kein_Komfortoeffnen_empfangen" 1 "Komfortoeffnen ueber Funk empfangen" ;
VAL_ 1411 FFB_Komfortschliessen 0 "kein_Komfortschliessen_empfangen" 1 "Komfortschliessen ueber Funk empfangen" ;
VAL_ 1411 ZV_Schluessel_Zugang 0 "kein_auth_Schluessel_erkannt" 1 "aktive_Funkschluessel_Nr_01" 2 "aktive_Funkschluessel_Nr_02" 3 "aktive_Funkschluessel_Nr_03" 4 "aktive_Funkschluessel_Nr_04" 5 "aktive_Funkschluessel_Nr_05" 6 "aktive_Funkschluessel_Nr_06" 7 "aktive_Funkschluessel_Nr_07" 8 "aktive_Funkschluessel_Nr_08" 9 "aktive_SmartDevice_Nr_09" 10 "ungueltig_10" 11 "ungueltig_11" 12 "ungueltig_12" 13 "ungueltig_13" 14 "ungueltig_14" 15 "ungueltig_15" ;
VAL_ 1411 ZV_SafeFunktion_aktiv 0 "inaktiv" 1 "aktiv" ;
VAL_ 1411 FBS_Warn_Schluessel_Batt 0 "i.O." 1 "defekt" ;
VAL_ 1411 ZV_Oeffnungsmodus 0 "globale_Oeffnung" 1 "ZV_mit_Einzeltuerentr" 2 "ZV_individuell_selektiv" 3 "ZV_seitenselektiv" ;
VAL_ 1411 HFS_verriegelt 0 "nicht_verriegelt" 1 "verriegelt" ;
VAL_ 1411 HFS_gesafet 0 "nicht_gesafet" 1 "gesafet" ;
VAL_ 1411 HBFS_verriegelt 0 "nicht_verriegelt" 1 "verriegelt" ;
VAL_ 1411 HBFS_gesafet 0 "nicht_gesafet" 1 "gesafet" ;
VAL_ 1411 ZV_ist_Zustand_verfuegbar 0 "nicht_verfuegbar" 1 "verfuegbar_alle_TSGs_am_Bus" ;
VAL_ 1411 IRUE_Taster_Fkts_LED 0 "LED_aus" 1 "LED_ein" ;
VAL_ 1411 ZV_Tankklappe_offen 0 "Tankklappe_geschlossen" 1 "Tankklappe_offen" ;
VAL_ 1411 ZV_Rollo_auf 0 "inaktiv" 1 "aktiv" ;
VAL_ 1411 ZV_Rollo_zu 0 "inaktiv" 1 "aktiv" ;
VAL_ 1411 ZV_SAD_auf 0 "inaktiv" 1 "aktiv" ;
VAL_ 1411 ZV_SAD_zu 0 "inaktiv" 1 "aktiv" ;
VAL_ 1411 BCM_Tankklappensteller_Fehler 0 "kein_Fehler" 1 "Fehler" ;
VAL_ 1411 ZV_verriegelt_soll 0 "Init" 1 "nicht_verriegelt" 2 "verriegelt" ;
